VERSION ""

NS_ :

BS_:

BU_: Bosch_Radar2 Bosch_Radar1 RADAR_INPUT BoschRadar1
VAL_TABLE_ ValueTable_Power_SNA 255 "SNA" ;
VAL_TABLE_ ValueTable_YAngle_SNA 65535 "SNA" ;
VAL_TABLE_ ValueTable_YSigmaAngle_SNA 1023 "SNA" ;
VAL_TABLE_ ValueTable_AngleType 1 "First 2 angles valid in C msg" 0 "First 4 angles valid in C msg" ;
VAL_TABLE_ RI_Veh_PRNDSTAT 0 "Park" 1 "Reverse" 2 "Neutral" 3 "Drive" ;

BO_ 1958 Radar2_Diag_Response: 8 Bosch_Radar2
 SG_ R2_DiagResponse : 7|64@0+ (1,0) [0|0] "" Vector__XXX

BO_ 1957 Radar2_Diag_Request: 8 RADAR_INPUT
 SG_ R2_DiagRequest : 7|64@0+ (1,0) [0|0] ""  Bosch_Radar2

BO_ 1985 Radar1_Diag_Response: 8 Bosch_Radar1
 SG_ R1_DiagResponse : 7|64@0+ (1,0) [0|0] "" Vector__XXX

BO_ 1879 Radar1_Diag_Request: 8 RADAR_INPUT
 SG_ R1_DiagRequest : 7|64@0+ (1,0) [0|0] ""  Bosch_Radar1

BO_ 1285 Radar1_Obj00_A: 8 Bosch_Radar1
 SG_ Radar1_Obj00_wObstacle : 53|5@0+ (0.03125,0) [0|0.96875] "" Vector__XXX
 SG_ Radar1_Obj00_wNonObstacle : 63|5@0+ (0.03125,0) [0|0.96875] "" Vector__XXX
 SG_ Radar1_Obj00_wExist : 36|5@0+ (0.03125,0) [0|0.96875] "-" Vector__XXX
 SG_ Radar1_Obj00_ax : 47|10@0+ (0.03125,-16) [-16|15.96875] "m/s2" Vector__XXX
 SG_ Radar1_Obj00_vx : 11|12@0+ (0.0625,-128) [-128|127.9375] "m/s" Vector__XXX
 SG_ Radar1_Obj00_dy : 31|11@0+ (0.125,-128) [-128|127.875] "m" Vector__XXX
 SG_ Radar1_Obj00_dx : 7|12@0+ (0.0625,-128) [-128|127.9375] "m" Vector__XXX
 SG_ Radar1_Obj00_flagValid : 48|1@0+ (1,0) [0|1] "" Vector__XXX
 SG_ Radar1_Obj00_flagHist : 57|1@0+ (1,0) [0|1] "" Vector__XXX
 SG_ Radar1_Obj00_flagMeas : 58|1@0+ (1,0) [0|1] "" Vector__XXX
 SG_ Radar1_Obj00_MessAconsistBit : 56|1@0+ (1,0) [0|1] "" Vector__XXX

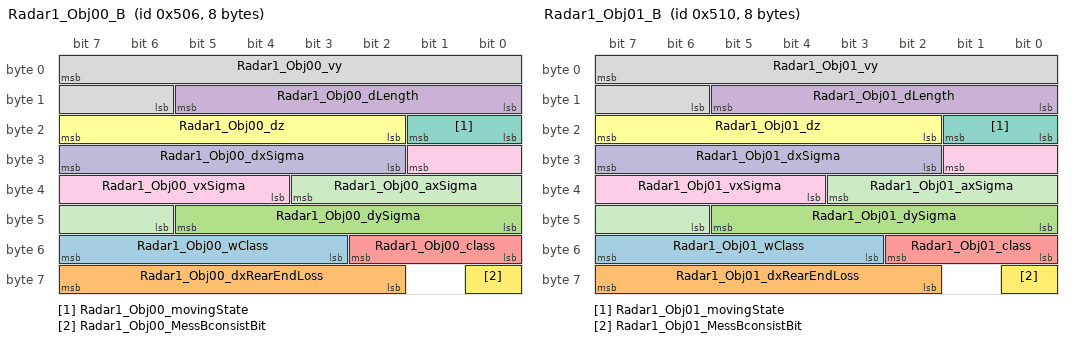
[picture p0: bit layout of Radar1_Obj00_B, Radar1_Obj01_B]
BO_ 1286 Radar1_Obj00_B: 8 Bosch_Radar1
 SG_ Radar1_Obj00_wClass : 55|5@0+ (0.03125,0) [0|0.96875] "" Vector__XXX
 SG_ Radar1_Obj00_dxRearEndLoss : 63|6@0+ (0.125,0) [0|7.875] "m" Vector__XXX
 SG_ Radar1_Obj00_dySigma : 45|6@0+ (0.0625,0) [0|3.9375] "m" Vector__XXX
 SG_ Radar1_Obj00_dLength : 13|6@0+ (0.125,0) [0|7.875] "m" Vector__XXX
 SG_ Radar1_Obj00_class : 50|3@0+ (1,0) [0|7] "" Vector__XXX
 SG_ Radar1_Obj00_dz : 23|6@0+ (0.25,-5) [-5|10.75] "m" Vector__XXX
 SG_ Radar1_Obj00_movingState : 17|2@0+ (1,0) [0|3] "" Vector__XXX
 SG_ Radar1_Obj00_vy : 7|10@0+ (0.125,-64) [-64|63.875] "m/s" Vector__XXX
 SG_ Radar1_Obj00_vxSigma : 25|6@0+ (0.0625,0) [0|3.9375] "m/s" Vector__XXX
 SG_ Radar1_Obj00_dxSigma : 31|6@0+ (0.0625,0) [0|3.9375] "m" Vector__XXX
 SG_ Radar1_Obj00_axSigma : 35|6@0+ (0.0625,0) [0|3.9375] "m/s2" Vector__XXX
 SG_ Radar1_Obj00_MessBconsistBit : 56|1@0+ (1,0) [0|1] "" Vector__XXX

BO_ 1295 Radar1_Obj01_A: 8 Bosch_Radar1
 SG_ Radar1_Obj01_wObstacle : 53|5@0+ (0.03125,0) [0|0.96875] "" Vector__XXX
 SG_ Radar1_Obj01_wNonObstacle : 63|5@0+ (0.03125,0) [0|0.96875] "" Vector__XXX
 SG_ Radar1_Obj01_wExist : 36|5@0+ (0.03125,0) [0|0.96875] "-" Vector__XXX
 SG_ Radar1_Obj01_ax : 47|10@0+ (0.03125,-16) [-16|15.96875] "m/s2" Vector__XXX
 SG_ Radar1_Obj01_vx : 11|12@0+ (0.0625,-128) [-128|127.9375] "m/s" Vector__XXX
 SG_ Radar1_Obj01_dy : 31|11@0+ (0.125,-128) [-128|127.875] "m" Vector__XXX
 SG_ Radar1_Obj01_dx : 7|12@0+ (0.0625,-128) [-128|127.9375] "m" Vector__XXX
 SG_ Radar1_Obj01_flagValid : 48|1@0+ (1,0) [0|1] "" Vector__XXX
 SG_ Radar1_Obj01_flagHist : 57|1@0+ (1,0) [0|1] "" Vector__XXX
 SG_ Radar1_Obj01_flagMeas : 58|1@0+ (1,0) [0|1] "" Vector__XXX
 SG_ Radar1_Obj01_MessAconsistBit : 56|1@0+ (1,0) [0|1] "" Vector__XXX

BO_ 1296 Radar1_Obj01_B: 8 Bosch_Radar1
 SG_ Radar1_Obj01_wClass : 55|5@0+ (0.03125,0) [0|0.96875] "" Vector__XXX
 SG_ Radar1_Obj01_dxRearEndLoss : 63|6@0+ (0.125,0) [0|7.875] "m" Vector__XXX
 SG_ Radar1_Obj01_dySigma : 45|6@0+ (0.0625,0) [0|3.9375] "m" Vector__XXX
 SG_ Radar1_Obj01_dLength : 13|6@0+ (0.125,0) [0|7.875] "m" Vector__XXX
 SG_ Radar1_Obj01_class : 50|3@0+ (1,0) [0|7] "" Vector__XXX
 SG_ Radar1_Obj01_dz : 23|6@0+ (0.25,-5) [-5|10.75] "m" Vector__XXX
 SG_ Radar1_Obj01_movingState : 17|2@0+ (1,0) [0|3] "" Vector__XXX
 SG_ Radar1_Obj01_vy : 7|10@0+ (0.125,-64) [-64|63.875] "m/s" Vector__XXX
 SG_ Radar1_Obj01_vxSigma : 25|6@0+ (0.0625,0) [0|3.9375] "m/s" Vector__XXX
 SG_ Radar1_Obj01_dxSigma : 31|6@0+ (0.0625,0) [0|3.9375] "m" Vector__XXX
 SG_ Radar1_Obj01_axSigma : 35|6@0+ (0.0625,0) [0|3.9375] "m/s2" Vector__XXX
 SG_ Radar1_Obj01_MessBconsistBit : 56|1@0+ (1,0) [0|1] "" Vector__XXX

BO_ 1305 Radar1_Obj02_A: 8 Bosch_Radar1
 SG_ Radar1_Obj02_wObstacle : 53|5@0+ (0.03125,0) [0|0.96875] "" Vector__XXX
 SG_ Radar1_Obj02_wNonObstacle : 63|5@0+ (0.03125,0) [0|0.96875] "" Vector__XXX
 SG_ Radar1_Obj02_wExist : 36|5@0+ (0.03125,0) [0|0.96875] "-" Vector__XXX
 SG_ Radar1_Obj02_ax : 47|10@0+ (0.03125,-16) [-16|15.96875] "m/s2" Vector__XXX
 SG_ Radar1_Obj02_vx : 11|12@0+ (0.0625,-128) [-128|127.9375] "m/s" Vector__XXX
 SG_ Radar1_Obj02_dy : 31|11@0+ (0.125,-128) [-128|127.875] "m" Vector__XXX
 SG_ Radar1_Obj02_dx : 7|12@0+ (0.0625,-128) [-128|127.9375] "m" Vector__XXX
 SG_ Radar1_Obj02_flagValid : 48|1@0+ (1,0) [0|1] "" Vector__XXX
 SG_ Radar1_Obj02_flagHist : 57|1@0+ (1,0) [0|1] "" Vector__XXX
 SG_ Radar1_Obj02_flagMeas : 58|1@0+ (1,0) [0|1] "" Vector__XXX
 SG_ Radar1_Obj02_MessAconsistBit : 56|1@0+ (1,0) [0|1] "" Vector__XXX

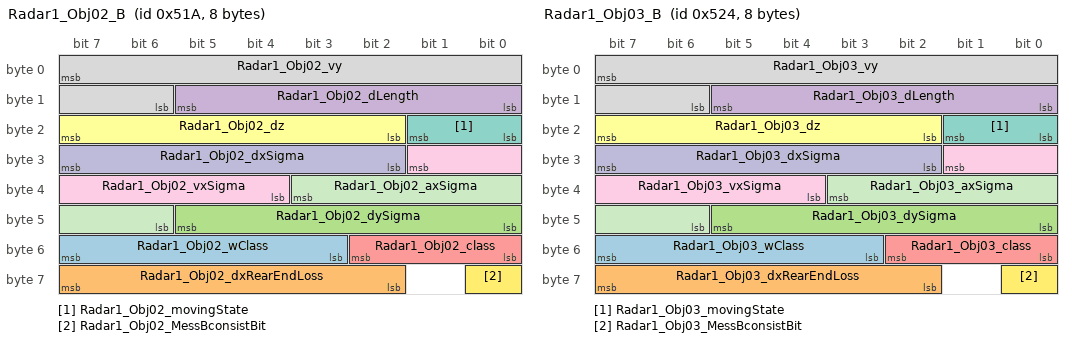
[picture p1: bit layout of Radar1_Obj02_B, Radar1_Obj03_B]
BO_ 1306 Radar1_Obj02_B: 8 Bosch_Radar1
 SG_ Radar1_Obj02_wClass : 55|5@0+ (0.03125,0) [0|0.96875] "" Vector__XXX
 SG_ Radar1_Obj02_dxRearEndLoss : 63|6@0+ (0.125,0) [0|7.875] "m" Vector__XXX
 SG_ Radar1_Obj02_dySigma : 45|6@0+ (0.0625,0) [0|3.9375] "m" Vector__XXX
 SG_ Radar1_Obj02_dLength : 13|6@0+ (0.125,0) [0|7.875] "m" Vector__XXX
 SG_ Radar1_Obj02_class : 50|3@0+ (1,0) [0|7] "" Vector__XXX
 SG_ Radar1_Obj02_dz : 23|6@0+ (0.25,-5) [-5|10.75] "m" Vector__XXX
 SG_ Radar1_Obj02_movingState : 17|2@0+ (1,0) [0|3] "" Vector__XXX
 SG_ Radar1_Obj02_vy : 7|10@0+ (0.125,-64) [-64|63.875] "m/s" Vector__XXX
 SG_ Radar1_Obj02_vxSigma : 25|6@0+ (0.0625,0) [0|3.9375] "m/s" Vector__XXX
 SG_ Radar1_Obj02_dxSigma : 31|6@0+ (0.0625,0) [0|3.9375] "m" Vector__XXX
 SG_ Radar1_Obj02_axSigma : 35|6@0+ (0.0625,0) [0|3.9375] "m/s2" Vector__XXX
 SG_ Radar1_Obj02_MessBconsistBit : 56|1@0+ (1,0) [0|1] "" Vector__XXX

BO_ 1315 Radar1_Obj03_A: 8 Bosch_Radar1
 SG_ Radar1_Obj03_wObstacle : 53|5@0+ (0.03125,0) [0|0.96875] "" Vector__XXX
 SG_ Radar1_Obj03_wNonObstacle : 63|5@0+ (0.03125,0) [0|0.96875] "" Vector__XXX
 SG_ Radar1_Obj03_wExist : 36|5@0+ (0.03125,0) [0|0.96875] "-" Vector__XXX
 SG_ Radar1_Obj03_ax : 47|10@0+ (0.03125,-16) [-16|15.96875] "m/s2" Vector__XXX
 SG_ Radar1_Obj03_vx : 11|12@0+ (0.0625,-128) [-128|127.9375] "m/s" Vector__XXX
 SG_ Radar1_Obj03_dy : 31|11@0+ (0.125,-128) [-128|127.875] "m" Vector__XXX
 SG_ Radar1_Obj03_dx : 7|12@0+ (0.0625,-128) [-128|127.9375] "m" Vector__XXX
 SG_ Radar1_Obj03_flagValid : 48|1@0+ (1,0) [0|1] "" Vector__XXX
 SG_ Radar1_Obj03_flagHist : 57|1@0+ (1,0) [0|1] "" Vector__XXX
 SG_ Radar1_Obj03_flagMeas : 58|1@0+ (1,0) [0|1] "" Vector__XXX
 SG_ Radar1_Obj03_MessAconsistBit : 56|1@0+ (1,0) [0|1] "" Vector__XXX

BO_ 1316 Radar1_Obj03_B: 8 Bosch_Radar1
 SG_ Radar1_Obj03_wClass : 55|5@0+ (0.03125,0) [0|0.96875] "" Vector__XXX
 SG_ Radar1_Obj03_dxRearEndLoss : 63|6@0+ (0.125,0) [0|7.875] "m" Vector__XXX
 SG_ Radar1_Obj03_dySigma : 45|6@0+ (0.0625,0) [0|3.9375] "m" Vector__XXX
 SG_ Radar1_Obj03_dLength : 13|6@0+ (0.125,0) [0|7.875] "m" Vector__XXX
 SG_ Radar1_Obj03_class : 50|3@0+ (1,0) [0|7] "" Vector__XXX
 SG_ Radar1_Obj03_dz : 23|6@0+ (0.25,-5) [-5|10.75] "m" Vector__XXX
 SG_ Radar1_Obj03_movingState : 17|2@0+ (1,0) [0|3] "" Vector__XXX
 SG_ Radar1_Obj03_vy : 7|10@0+ (0.125,-64) [-64|63.875] "m/s" Vector__XXX
 SG_ Radar1_Obj03_vxSigma : 25|6@0+ (0.0625,0) [0|3.9375] "m/s" Vector__XXX
 SG_ Radar1_Obj03_dxSigma : 31|6@0+ (0.0625,0) [0|3.9375] "m" Vector__XXX
 SG_ Radar1_Obj03_axSigma : 35|6@0+ (0.0625,0) [0|3.9375] "m/s2" Vector__XXX
 SG_ Radar1_Obj03_MessBconsistBit : 56|1@0+ (1,0) [0|1] "" Vector__XXX

BO_ 1325 Radar1_Obj04_A: 8 Bosch_Radar1
 SG_ Radar1_Obj04_wObstacle : 53|5@0+ (0.03125,0) [0|0.96875] "" Vector__XXX
 SG_ Radar1_Obj04_wNonObstacle : 63|5@0+ (0.03125,0) [0|0.96875] "" Vector__XXX
 SG_ Radar1_Obj04_wExist : 36|5@0+ (0.03125,0) [0|0.96875] "-" Vector__XXX
 SG_ Radar1_Obj04_ax : 47|10@0+ (0.03125,-16) [-16|15.96875] "m/s2" Vector__XXX
 SG_ Radar1_Obj04_vx : 11|12@0+ (0.0625,-128) [-128|127.9375] "m/s" Vector__XXX
 SG_ Radar1_Obj04_dy : 31|11@0+ (0.125,-128) [-128|127.875] "m" Vector__XXX
 SG_ Radar1_Obj04_dx : 7|12@0+ (0.0625,-128) [-128|127.9375] "m" Vector__XXX
 SG_ Radar1_Obj04_flagValid : 48|1@0+ (1,0) [0|1] "" Vector__XXX
 SG_ Radar1_Obj04_flagHist : 57|1@0+ (1,0) [0|1] "" Vector__XXX
 SG_ Radar1_Obj04_flagMeas : 58|1@0+ (1,0) [0|1] "" Vector__XXX
 SG_ Radar1_Obj04_MessAconsistBit : 56|1@0+ (1,0) [0|1] "" Vector__XXX

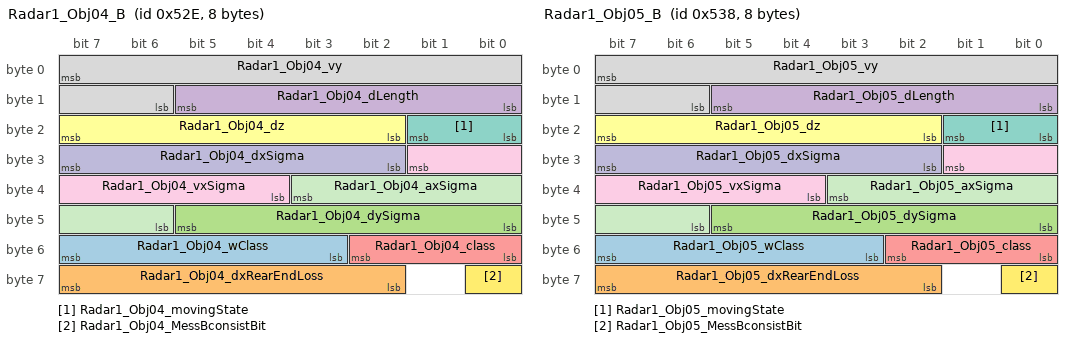
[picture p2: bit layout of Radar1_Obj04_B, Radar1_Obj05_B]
BO_ 1326 Radar1_Obj04_B: 8 Bosch_Radar1
 SG_ Radar1_Obj04_wClass : 55|5@0+ (0.03125,0) [0|0.96875] "" Vector__XXX
 SG_ Radar1_Obj04_dxRearEndLoss : 63|6@0+ (0.125,0) [0|7.875] "m" Vector__XXX
 SG_ Radar1_Obj04_dySigma : 45|6@0+ (0.0625,0) [0|3.9375] "m" Vector__XXX
 SG_ Radar1_Obj04_dLength : 13|6@0+ (0.125,0) [0|7.875] "m" Vector__XXX
 SG_ Radar1_Obj04_class : 50|3@0+ (1,0) [0|7] "" Vector__XXX
 SG_ Radar1_Obj04_dz : 23|6@0+ (0.25,-5) [-5|10.75] "m" Vector__XXX
 SG_ Radar1_Obj04_movingState : 17|2@0+ (1,0) [0|3] "" Vector__XXX
 SG_ Radar1_Obj04_vy : 7|10@0+ (0.125,-64) [-64|63.875] "m/s" Vector__XXX
 SG_ Radar1_Obj04_vxSigma : 25|6@0+ (0.0625,0) [0|3.9375] "m/s" Vector__XXX
 SG_ Radar1_Obj04_dxSigma : 31|6@0+ (0.0625,0) [0|3.9375] "m" Vector__XXX
 SG_ Radar1_Obj04_axSigma : 35|6@0+ (0.0625,0) [0|3.9375] "m/s2" Vector__XXX
 SG_ Radar1_Obj04_MessBconsistBit : 56|1@0+ (1,0) [0|1] "" Vector__XXX

BO_ 1335 Radar1_Obj05_A: 8 Bosch_Radar1
 SG_ Radar1_Obj05_wObstacle : 53|5@0+ (0.03125,0) [0|0.96875] "" Vector__XXX
 SG_ Radar1_Obj05_wNonObstacle : 63|5@0+ (0.03125,0) [0|0.96875] "" Vector__XXX
 SG_ Radar1_Obj05_wExist : 36|5@0+ (0.03125,0) [0|0.96875] "-" Vector__XXX
 SG_ Radar1_Obj05_ax : 47|10@0+ (0.03125,-16) [-16|15.96875] "m/s2" Vector__XXX
 SG_ Radar1_Obj05_vx : 11|12@0+ (0.0625,-128) [-128|127.9375] "m/s" Vector__XXX
 SG_ Radar1_Obj05_dy : 31|11@0+ (0.125,-128) [-128|127.875] "m" Vector__XXX
 SG_ Radar1_Obj05_dx : 7|12@0+ (0.0625,-128) [-128|127.9375] "m" Vector__XXX
 SG_ Radar1_Obj05_flagValid : 48|1@0+ (1,0) [0|1] "" Vector__XXX
 SG_ Radar1_Obj05_flagHist : 57|1@0+ (1,0) [0|1] "" Vector__XXX
 SG_ Radar1_Obj05_flagMeas : 58|1@0+ (1,0) [0|1] "" Vector__XXX
 SG_ Radar1_Obj05_MessAconsistBit : 56|1@0+ (1,0) [0|1] "" Vector__XXX

BO_ 1336 Radar1_Obj05_B: 8 Bosch_Radar1
 SG_ Radar1_Obj05_wClass : 55|5@0+ (0.03125,0) [0|0.96875] "" Vector__XXX
 SG_ Radar1_Obj05_dxRearEndLoss : 63|6@0+ (0.125,0) [0|7.875] "m" Vector__XXX
 SG_ Radar1_Obj05_dySigma : 45|6@0+ (0.0625,0) [0|3.9375] "m" Vector__XXX
 SG_ Radar1_Obj05_dLength : 13|6@0+ (0.125,0) [0|7.875] "m" Vector__XXX
 SG_ Radar1_Obj05_class : 50|3@0+ (1,0) [0|7] "" Vector__XXX
 SG_ Radar1_Obj05_dz : 23|6@0+ (0.25,-5) [-5|10.75] "m" Vector__XXX
 SG_ Radar1_Obj05_movingState : 17|2@0+ (1,0) [0|3] "" Vector__XXX
 SG_ Radar1_Obj05_vy : 7|10@0+ (0.125,-64) [-64|63.875] "m/s" Vector__XXX
 SG_ Radar1_Obj05_vxSigma : 25|6@0+ (0.0625,0) [0|3.9375] "m/s" Vector__XXX
 SG_ Radar1_Obj05_dxSigma : 31|6@0+ (0.0625,0) [0|3.9375] "m" Vector__XXX
 SG_ Radar1_Obj05_axSigma : 35|6@0+ (0.0625,0) [0|3.9375] "m/s2" Vector__XXX
 SG_ Radar1_Obj05_MessBconsistBit : 56|1@0+ (1,0) [0|1] "" Vector__XXX

BO_ 1345 Radar1_Obj06_A: 8 Bosch_Radar1
 SG_ Radar1_Obj06_wObstacle : 53|5@0+ (0.03125,0) [0|0.96875] "" Vector__XXX
 SG_ Radar1_Obj06_wNonObstacle : 63|5@0+ (0.03125,0) [0|0.96875] "" Vector__XXX
 SG_ Radar1_Obj06_wExist : 36|5@0+ (0.03125,0) [0|0.96875] "-" Vector__XXX
 SG_ Radar1_Obj06_ax : 47|10@0+ (0.03125,-16) [-16|15.96875] "m/s2" Vector__XXX
 SG_ Radar1_Obj06_vx : 11|12@0+ (0.0625,-128) [-128|127.9375] "m/s" Vector__XXX
 SG_ Radar1_Obj06_dy : 31|11@0+ (0.125,-128) [-128|127.875] "m" Vector__XXX
 SG_ Radar1_Obj06_dx : 7|12@0+ (0.0625,-128) [-128|127.9375] "m" Vector__XXX
 SG_ Radar1_Obj06_flagValid : 48|1@0+ (1,0) [0|1] "" Vector__XXX
 SG_ Radar1_Obj06_flagHist : 57|1@0+ (1,0) [0|1] "" Vector__XXX
 SG_ Radar1_Obj06_flagMeas : 58|1@0+ (1,0) [0|1] "" Vector__XXX
 SG_ Radar1_Obj06_MessAconsistBit : 56|1@0+ (1,0) [0|1] "" Vector__XXX

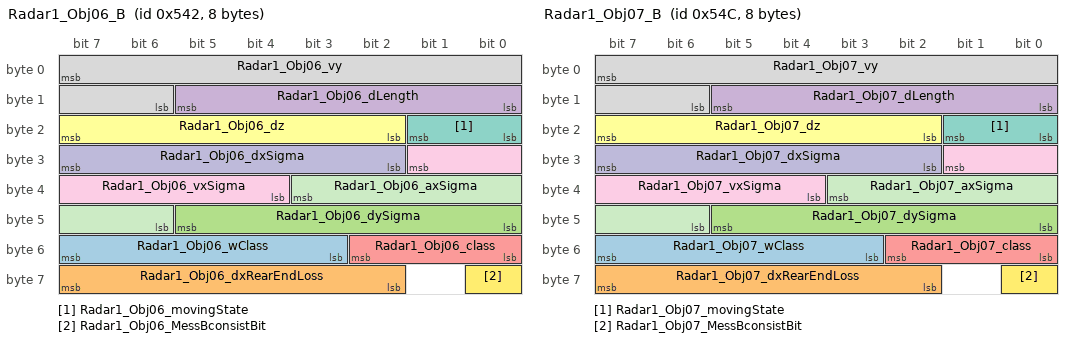
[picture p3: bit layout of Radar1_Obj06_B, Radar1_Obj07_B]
BO_ 1346 Radar1_Obj06_B: 8 Bosch_Radar1
 SG_ Radar1_Obj06_wClass : 55|5@0+ (0.03125,0) [0|0.96875] "" Vector__XXX
 SG_ Radar1_Obj06_dxRearEndLoss : 63|6@0+ (0.125,0) [0|7.875] "m" Vector__XXX
 SG_ Radar1_Obj06_dySigma : 45|6@0+ (0.0625,0) [0|3.9375] "m" Vector__XXX
 SG_ Radar1_Obj06_dLength : 13|6@0+ (0.125,0) [0|7.875] "m" Vector__XXX
 SG_ Radar1_Obj06_class : 50|3@0+ (1,0) [0|7] "" Vector__XXX
 SG_ Radar1_Obj06_dz : 23|6@0+ (0.25,-5) [-5|10.75] "m" Vector__XXX
 SG_ Radar1_Obj06_movingState : 17|2@0+ (1,0) [0|3] "" Vector__XXX
 SG_ Radar1_Obj06_vy : 7|10@0+ (0.125,-64) [-64|63.875] "m/s" Vector__XXX
 SG_ Radar1_Obj06_vxSigma : 25|6@0+ (0.0625,0) [0|3.9375] "m/s" Vector__XXX
 SG_ Radar1_Obj06_dxSigma : 31|6@0+ (0.0625,0) [0|3.9375] "m" Vector__XXX
 SG_ Radar1_Obj06_axSigma : 35|6@0+ (0.0625,0) [0|3.9375] "m/s2" Vector__XXX
 SG_ Radar1_Obj06_MessBconsistBit : 56|1@0+ (1,0) [0|1] "" Vector__XXX

BO_ 1355 Radar1_Obj07_A: 8 Bosch_Radar1
 SG_ Radar1_Obj07_wObstacle : 53|5@0+ (0.03125,0) [0|0.96875] "" Vector__XXX
 SG_ Radar1_Obj07_wNonObstacle : 63|5@0+ (0.03125,0) [0|0.96875] "" Vector__XXX
 SG_ Radar1_Obj07_wExist : 36|5@0+ (0.03125,0) [0|0.96875] "-" Vector__XXX
 SG_ Radar1_Obj07_ax : 47|10@0+ (0.03125,-16) [-16|15.96875] "m/s2" Vector__XXX
 SG_ Radar1_Obj07_vx : 11|12@0+ (0.0625,-128) [-128|127.9375] "m/s" Vector__XXX
 SG_ Radar1_Obj07_dy : 31|11@0+ (0.125,-128) [-128|127.875] "m" Vector__XXX
 SG_ Radar1_Obj07_dx : 7|12@0+ (0.0625,-128) [-128|127.9375] "m" Vector__XXX
 SG_ Radar1_Obj07_flagValid : 48|1@0+ (1,0) [0|1] "" Vector__XXX
 SG_ Radar1_Obj07_flagHist : 57|1@0+ (1,0) [0|1] "" Vector__XXX
 SG_ Radar1_Obj07_flagMeas : 58|1@0+ (1,0) [0|1] "" Vector__XXX
 SG_ Radar1_Obj07_MessAconsistBit : 56|1@0+ (1,0) [0|1] "" Vector__XXX

BO_ 1356 Radar1_Obj07_B: 8 Bosch_Radar1
 SG_ Radar1_Obj07_wClass : 55|5@0+ (0.03125,0) [0|0.96875] "" Vector__XXX
 SG_ Radar1_Obj07_dxRearEndLoss : 63|6@0+ (0.125,0) [0|7.875] "m" Vector__XXX
 SG_ Radar1_Obj07_dySigma : 45|6@0+ (0.0625,0) [0|3.9375] "m" Vector__XXX
 SG_ Radar1_Obj07_dLength : 13|6@0+ (0.125,0) [0|7.875] "m" Vector__XXX
 SG_ Radar1_Obj07_class : 50|3@0+ (1,0) [0|7] "" Vector__XXX
 SG_ Radar1_Obj07_dz : 23|6@0+ (0.25,-5) [-5|10.75] "m" Vector__XXX
 SG_ Radar1_Obj07_movingState : 17|2@0+ (1,0) [0|3] "" Vector__XXX
 SG_ Radar1_Obj07_vy : 7|10@0+ (0.125,-64) [-64|63.875] "m/s" Vector__XXX
 SG_ Radar1_Obj07_vxSigma : 25|6@0+ (0.0625,0) [0|3.9375] "m/s" Vector__XXX
 SG_ Radar1_Obj07_dxSigma : 31|6@0+ (0.0625,0) [0|3.9375] "m" Vector__XXX
 SG_ Radar1_Obj07_axSigma : 35|6@0+ (0.0625,0) [0|3.9375] "m/s2" Vector__XXX
 SG_ Radar1_Obj07_MessBconsistBit : 56|1@0+ (1,0) [0|1] "" Vector__XXX

BO_ 1365 Radar1_Obj08_A: 8 Bosch_Radar1
 SG_ Radar1_Obj08_wObstacle : 53|5@0+ (0.03125,0) [0|0.96875] "" Vector__XXX
 SG_ Radar1_Obj08_wNonObstacle : 63|5@0+ (0.03125,0) [0|0.96875] "" Vector__XXX
 SG_ Radar1_Obj08_wExist : 36|5@0+ (0.03125,0) [0|0.96875] "-" Vector__XXX
 SG_ Radar1_Obj08_ax : 47|10@0+ (0.03125,-16) [-16|15.96875] "m/s2" Vector__XXX
 SG_ Radar1_Obj08_vx : 11|12@0+ (0.0625,-128) [-128|127.9375] "m/s" Vector__XXX
 SG_ Radar1_Obj08_dy : 31|11@0+ (0.125,-128) [-128|127.875] "m" Vector__XXX
 SG_ Radar1_Obj08_dx : 7|12@0+ (0.0625,-128) [-128|127.9375] "m" Vector__XXX
 SG_ Radar1_Obj08_flagValid : 48|1@0+ (1,0) [0|1] "" Vector__XXX
 SG_ Radar1_Obj08_flagHist : 57|1@0+ (1,0) [0|1] "" Vector__XXX
 SG_ Radar1_Obj08_flagMeas : 58|1@0+ (1,0) [0|1] "" Vector__XXX
 SG_ Radar1_Obj08_MessAconsistBit : 56|1@0+ (1,0) [0|1] "" Vector__XXX

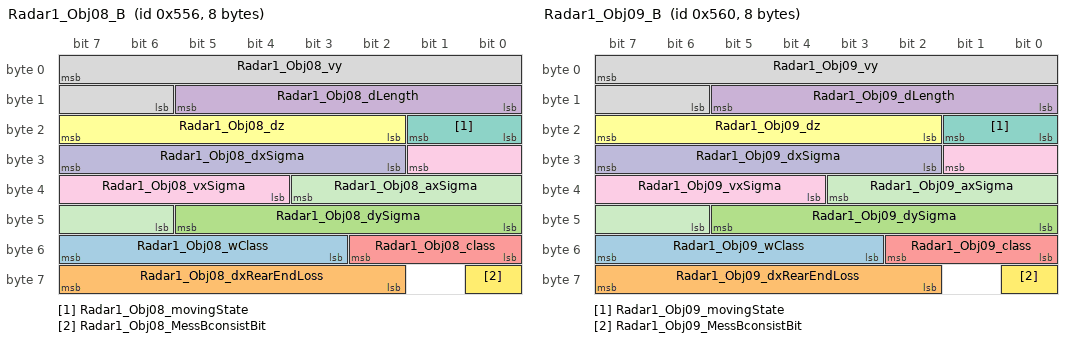
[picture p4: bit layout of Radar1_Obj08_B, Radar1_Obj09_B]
BO_ 1366 Radar1_Obj08_B: 8 Bosch_Radar1
 SG_ Radar1_Obj08_wClass : 55|5@0+ (0.03125,0) [0|0.96875] "" Vector__XXX
 SG_ Radar1_Obj08_dxRearEndLoss : 63|6@0+ (0.125,0) [0|7.875] "m" Vector__XXX
 SG_ Radar1_Obj08_dySigma : 45|6@0+ (0.0625,0) [0|3.9375] "m" Vector__XXX
 SG_ Radar1_Obj08_dLength : 13|6@0+ (0.125,0) [0|7.875] "m" Vector__XXX
 SG_ Radar1_Obj08_class : 50|3@0+ (1,0) [0|7] "" Vector__XXX
 SG_ Radar1_Obj08_dz : 23|6@0+ (0.25,-5) [-5|10.75] "m" Vector__XXX
 SG_ Radar1_Obj08_movingState : 17|2@0+ (1,0) [0|3] "" Vector__XXX
 SG_ Radar1_Obj08_vy : 7|10@0+ (0.125,-64) [-64|63.875] "m/s" Vector__XXX
 SG_ Radar1_Obj08_vxSigma : 25|6@0+ (0.0625,0) [0|3.9375] "m/s" Vector__XXX
 SG_ Radar1_Obj08_dxSigma : 31|6@0+ (0.0625,0) [0|3.9375] "m" Vector__XXX
 SG_ Radar1_Obj08_axSigma : 35|6@0+ (0.0625,0) [0|3.9375] "m/s2" Vector__XXX
 SG_ Radar1_Obj08_MessBconsistBit : 56|1@0+ (1,0) [0|1] "" Vector__XXX

BO_ 1375 Radar1_Obj09_A: 8 Bosch_Radar1
 SG_ Radar1_Obj09_wObstacle : 53|5@0+ (0.03125,0) [0|0.96875] "" Vector__XXX
 SG_ Radar1_Obj09_wNonObstacle : 63|5@0+ (0.03125,0) [0|0.96875] "" Vector__XXX
 SG_ Radar1_Obj09_wExist : 36|5@0+ (0.03125,0) [0|0.96875] "-" Vector__XXX
 SG_ Radar1_Obj09_ax : 47|10@0+ (0.03125,-16) [-16|15.96875] "m/s2" Vector__XXX
 SG_ Radar1_Obj09_vx : 11|12@0+ (0.0625,-128) [-128|127.9375] "m/s" Vector__XXX
 SG_ Radar1_Obj09_dy : 31|11@0+ (0.125,-128) [-128|127.875] "m" Vector__XXX
 SG_ Radar1_Obj09_dx : 7|12@0+ (0.0625,-128) [-128|127.9375] "m" Vector__XXX
 SG_ Radar1_Obj09_flagValid : 48|1@0+ (1,0) [0|1] "" Vector__XXX
 SG_ Radar1_Obj09_flagHist : 57|1@0+ (1,0) [0|1] "" Vector__XXX
 SG_ Radar1_Obj09_flagMeas : 58|1@0+ (1,0) [0|1] "" Vector__XXX
 SG_ Radar1_Obj09_MessAconsistBit : 56|1@0+ (1,0) [0|1] "" Vector__XXX

BO_ 1376 Radar1_Obj09_B: 8 Bosch_Radar1
 SG_ Radar1_Obj09_wClass : 55|5@0+ (0.03125,0) [0|0.96875] "" Vector__XXX
 SG_ Radar1_Obj09_dxRearEndLoss : 63|6@0+ (0.125,0) [0|7.875] "m" Vector__XXX
 SG_ Radar1_Obj09_dySigma : 45|6@0+ (0.0625,0) [0|3.9375] "m" Vector__XXX
 SG_ Radar1_Obj09_dLength : 13|6@0+ (0.125,0) [0|7.875] "m" Vector__XXX
 SG_ Radar1_Obj09_class : 50|3@0+ (1,0) [0|7] "" Vector__XXX
 SG_ Radar1_Obj09_dz : 23|6@0+ (0.25,-5) [-5|10.75] "m" Vector__XXX
 SG_ Radar1_Obj09_movingState : 17|2@0+ (1,0) [0|3] "" Vector__XXX
 SG_ Radar1_Obj09_vy : 7|10@0+ (0.125,-64) [-64|63.875] "m/s" Vector__XXX
 SG_ Radar1_Obj09_vxSigma : 25|6@0+ (0.0625,0) [0|3.9375] "m/s" Vector__XXX
 SG_ Radar1_Obj09_dxSigma : 31|6@0+ (0.0625,0) [0|3.9375] "m" Vector__XXX
 SG_ Radar1_Obj09_axSigma : 35|6@0+ (0.0625,0) [0|3.9375] "m/s2" Vector__XXX
 SG_ Radar1_Obj09_MessBconsistBit : 56|1@0+ (1,0) [0|1] "" Vector__XXX

BO_ 1385 Radar1_Obj10_A: 8 Bosch_Radar1
 SG_ Radar1_Obj10_wObstacle : 53|5@0+ (0.03125,0) [0|0.96875] "" Vector__XXX
 SG_ Radar1_Obj10_wNonObstacle : 63|5@0+ (0.03125,0) [0|0.96875] "" Vector__XXX
 SG_ Radar1_Obj10_wExist : 36|5@0+ (0.03125,0) [0|0.96875] "-" Vector__XXX
 SG_ Radar1_Obj10_ax : 47|10@0+ (0.03125,-16) [-16|15.96875] "m/s2" Vector__XXX
 SG_ Radar1_Obj10_vx : 11|12@0+ (0.0625,-128) [-128|127.9375] "m/s" Vector__XXX
 SG_ Radar1_Obj10_dy : 31|11@0+ (0.125,-128) [-128|127.875] "m" Vector__XXX
 SG_ Radar1_Obj10_dx : 7|12@0+ (0.0625,-128) [-128|127.9375] "m" Vector__XXX
 SG_ Radar1_Obj10_flagValid : 48|1@0+ (1,0) [0|1] "" Vector__XXX
 SG_ Radar1_Obj10_flagHist : 57|1@0+ (1,0) [0|1] "" Vector__XXX
 SG_ Radar1_Obj10_flagMeas : 58|1@0+ (1,0) [0|1] "" Vector__XXX
 SG_ Radar1_Obj10_MessAconsistBit : 56|1@0+ (1,0) [0|1] "" Vector__XXX

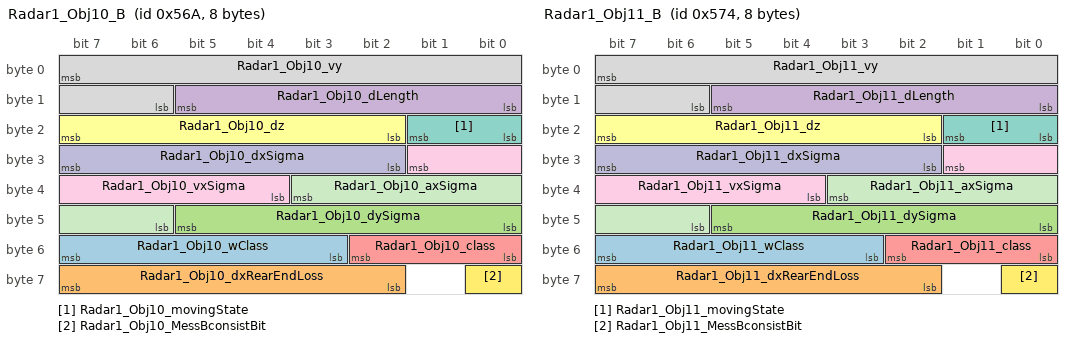
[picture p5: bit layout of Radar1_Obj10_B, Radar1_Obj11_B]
BO_ 1386 Radar1_Obj10_B: 8 Bosch_Radar1
 SG_ Radar1_Obj10_wClass : 55|5@0+ (0.03125,0) [0|0.96875] "" Vector__XXX
 SG_ Radar1_Obj10_dxRearEndLoss : 63|6@0+ (0.125,0) [0|7.875] "m" Vector__XXX
 SG_ Radar1_Obj10_dySigma : 45|6@0+ (0.0625,0) [0|3.9375] "m" Vector__XXX
 SG_ Radar1_Obj10_dLength : 13|6@0+ (0.125,0) [0|7.875] "m" Vector__XXX
 SG_ Radar1_Obj10_class : 50|3@0+ (1,0) [0|7] "" Vector__XXX
 SG_ Radar1_Obj10_dz : 23|6@0+ (0.25,-5) [-5|10.75] "m" Vector__XXX
 SG_ Radar1_Obj10_movingState : 17|2@0+ (1,0) [0|3] "" Vector__XXX
 SG_ Radar1_Obj10_vy : 7|10@0+ (0.125,-64) [-64|63.875] "m/s" Vector__XXX
 SG_ Radar1_Obj10_vxSigma : 25|6@0+ (0.0625,0) [0|3.9375] "m/s" Vector__XXX
 SG_ Radar1_Obj10_dxSigma : 31|6@0+ (0.0625,0) [0|3.9375] "m" Vector__XXX
 SG_ Radar1_Obj10_axSigma : 35|6@0+ (0.0625,0) [0|3.9375] "m/s2" Vector__XXX
 SG_ Radar1_Obj10_MessBconsistBit : 56|1@0+ (1,0) [0|1] "" Vector__XXX

BO_ 1395 Radar1_Obj11_A: 8 Bosch_Radar1
 SG_ Radar1_Obj11_wObstacle : 53|5@0+ (0.03125,0) [0|0.96875] "" Vector__XXX
 SG_ Radar1_Obj11_wNonObstacle : 63|5@0+ (0.03125,0) [0|0.96875] "" Vector__XXX
 SG_ Radar1_Obj11_wExist : 36|5@0+ (0.03125,0) [0|0.96875] "-" Vector__XXX
 SG_ Radar1_Obj11_ax : 47|10@0+ (0.03125,-16) [-16|15.96875] "m/s2" Vector__XXX
 SG_ Radar1_Obj11_vx : 11|12@0+ (0.0625,-128) [-128|127.9375] "m/s" Vector__XXX
 SG_ Radar1_Obj11_dy : 31|11@0+ (0.125,-128) [-128|127.875] "m" Vector__XXX
 SG_ Radar1_Obj11_dx : 7|12@0+ (0.0625,-128) [-128|127.9375] "m" Vector__XXX
 SG_ Radar1_Obj11_flagValid : 48|1@0+ (1,0) [0|1] "" Vector__XXX
 SG_ Radar1_Obj11_flagHist : 57|1@0+ (1,0) [0|1] "" Vector__XXX
 SG_ Radar1_Obj11_flagMeas : 58|1@0+ (1,0) [0|1] "" Vector__XXX
 SG_ Radar1_Obj11_MessAconsistBit : 56|1@0+ (1,0) [0|1] "" Vector__XXX

BO_ 1396 Radar1_Obj11_B: 8 Bosch_Radar1
 SG_ Radar1_Obj11_wClass : 55|5@0+ (0.03125,0) [0|0.96875] "" Vector__XXX
 SG_ Radar1_Obj11_dxRearEndLoss : 63|6@0+ (0.125,0) [0|7.875] "m" Vector__XXX
 SG_ Radar1_Obj11_dySigma : 45|6@0+ (0.0625,0) [0|3.9375] "m" Vector__XXX
 SG_ Radar1_Obj11_dLength : 13|6@0+ (0.125,0) [0|7.875] "m" Vector__XXX
 SG_ Radar1_Obj11_class : 50|3@0+ (1,0) [0|7] "" Vector__XXX
 SG_ Radar1_Obj11_dz : 23|6@0+ (0.25,-5) [-5|10.75] "m" Vector__XXX
 SG_ Radar1_Obj11_movingState : 17|2@0+ (1,0) [0|3] "" Vector__XXX
 SG_ Radar1_Obj11_vy : 7|10@0+ (0.125,-64) [-64|63.875] "m/s" Vector__XXX
 SG_ Radar1_Obj11_vxSigma : 25|6@0+ (0.0625,0) [0|3.9375] "m/s" Vector__XXX
 SG_ Radar1_Obj11_dxSigma : 31|6@0+ (0.0625,0) [0|3.9375] "m" Vector__XXX
 SG_ Radar1_Obj11_axSigma : 35|6@0+ (0.0625,0) [0|3.9375] "m/s2" Vector__XXX
 SG_ Radar1_Obj11_MessBconsistBit : 56|1@0+ (1,0) [0|1] "" Vector__XXX

BO_ 1405 Radar1_Obj12_A: 8 Bosch_Radar1
 SG_ Radar1_Obj12_wObstacle : 53|5@0+ (0.03125,0) [0|0.96875] "" Vector__XXX
 SG_ Radar1_Obj12_wNonObstacle : 63|5@0+ (0.03125,0) [0|0.96875] "" Vector__XXX
 SG_ Radar1_Obj12_wExist : 36|5@0+ (0.03125,0) [0|0.96875] "-" Vector__XXX
 SG_ Radar1_Obj12_ax : 47|10@0+ (0.03125,-16) [-16|15.96875] "m/s2" Vector__XXX
 SG_ Radar1_Obj12_vx : 11|12@0+ (0.0625,-128) [-128|127.9375] "m/s" Vector__XXX
 SG_ Radar1_Obj12_dy : 31|11@0+ (0.125,-128) [-128|127.875] "m" Vector__XXX
 SG_ Radar1_Obj12_dx : 7|12@0+ (0.0625,-128) [-128|127.9375] "m" Vector__XXX
 SG_ Radar1_Obj12_flagValid : 48|1@0+ (1,0) [0|1] "" Vector__XXX
 SG_ Radar1_Obj12_flagHist : 57|1@0+ (1,0) [0|1] "" Vector__XXX
 SG_ Radar1_Obj12_flagMeas : 58|1@0+ (1,0) [0|1] "" Vector__XXX
 SG_ Radar1_Obj12_MessAconsistBit : 56|1@0+ (1,0) [0|1] "" Vector__XXX

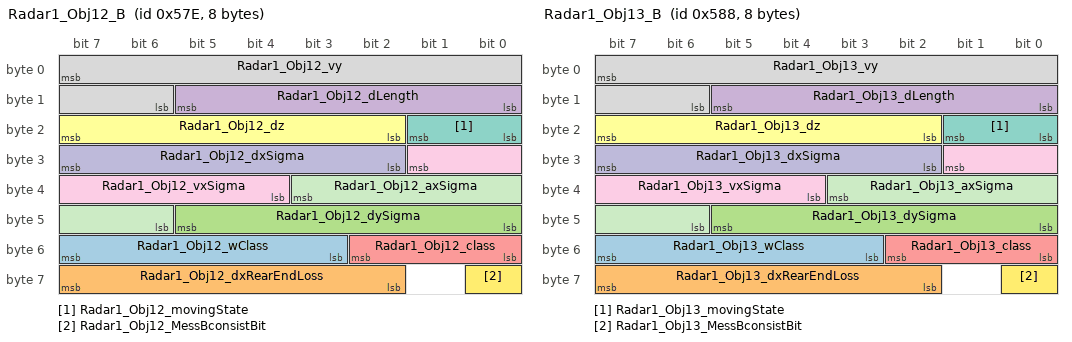
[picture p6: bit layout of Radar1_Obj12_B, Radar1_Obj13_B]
BO_ 1406 Radar1_Obj12_B: 8 Bosch_Radar1
 SG_ Radar1_Obj12_wClass : 55|5@0+ (0.03125,0) [0|0.96875] "" Vector__XXX
 SG_ Radar1_Obj12_dxRearEndLoss : 63|6@0+ (0.125,0) [0|7.875] "m" Vector__XXX
 SG_ Radar1_Obj12_dySigma : 45|6@0+ (0.0625,0) [0|3.9375] "m" Vector__XXX
 SG_ Radar1_Obj12_dLength : 13|6@0+ (0.125,0) [0|7.875] "m" Vector__XXX
 SG_ Radar1_Obj12_class : 50|3@0+ (1,0) [0|7] "" Vector__XXX
 SG_ Radar1_Obj12_dz : 23|6@0+ (0.25,-5) [-5|10.75] "m" Vector__XXX
 SG_ Radar1_Obj12_movingState : 17|2@0+ (1,0) [0|3] "" Vector__XXX
 SG_ Radar1_Obj12_vy : 7|10@0+ (0.125,-64) [-64|63.875] "m/s" Vector__XXX
 SG_ Radar1_Obj12_vxSigma : 25|6@0+ (0.0625,0) [0|3.9375] "m/s" Vector__XXX
 SG_ Radar1_Obj12_dxSigma : 31|6@0+ (0.0625,0) [0|3.9375] "m" Vector__XXX
 SG_ Radar1_Obj12_axSigma : 35|6@0+ (0.0625,0) [0|3.9375] "m/s2" Vector__XXX
 SG_ Radar1_Obj12_MessBconsistBit : 56|1@0+ (1,0) [0|1] "" Vector__XXX

BO_ 1415 Radar1_Obj13_A: 8 Bosch_Radar1
 SG_ Radar1_Obj13_wObstacle : 53|5@0+ (0.03125,0) [0|0.96875] "" Vector__XXX
 SG_ Radar1_Obj13_wNonObstacle : 63|5@0+ (0.03125,0) [0|0.96875] "" Vector__XXX
 SG_ Radar1_Obj13_wExist : 36|5@0+ (0.03125,0) [0|0.96875] "-" Vector__XXX
 SG_ Radar1_Obj13_ax : 47|10@0+ (0.03125,-16) [-16|15.96875] "m/s2" Vector__XXX
 SG_ Radar1_Obj13_vx : 11|12@0+ (0.0625,-128) [-128|127.9375] "m/s" Vector__XXX
 SG_ Radar1_Obj13_dy : 31|11@0+ (0.125,-128) [-128|127.875] "m" Vector__XXX
 SG_ Radar1_Obj13_dx : 7|12@0+ (0.0625,-128) [-128|127.9375] "m" Vector__XXX
 SG_ Radar1_Obj13_flagValid : 48|1@0+ (1,0) [0|1] "" Vector__XXX
 SG_ Radar1_Obj13_flagHist : 57|1@0+ (1,0) [0|1] "" Vector__XXX
 SG_ Radar1_Obj13_flagMeas : 58|1@0+ (1,0) [0|1] "" Vector__XXX
 SG_ Radar1_Obj13_MessAconsistBit : 56|1@0+ (1,0) [0|1] "" Vector__XXX

BO_ 1416 Radar1_Obj13_B: 8 Bosch_Radar1
 SG_ Radar1_Obj13_wClass : 55|5@0+ (0.03125,0) [0|0.96875] "" Vector__XXX
 SG_ Radar1_Obj13_dxRearEndLoss : 63|6@0+ (0.125,0) [0|7.875] "m" Vector__XXX
 SG_ Radar1_Obj13_dySigma : 45|6@0+ (0.0625,0) [0|3.9375] "m" Vector__XXX
 SG_ Radar1_Obj13_dLength : 13|6@0+ (0.125,0) [0|7.875] "m" Vector__XXX
 SG_ Radar1_Obj13_class : 50|3@0+ (1,0) [0|7] "" Vector__XXX
 SG_ Radar1_Obj13_dz : 23|6@0+ (0.25,-5) [-5|10.75] "m" Vector__XXX
 SG_ Radar1_Obj13_movingState : 17|2@0+ (1,0) [0|3] "" Vector__XXX
 SG_ Radar1_Obj13_vy : 7|10@0+ (0.125,-64) [-64|63.875] "m/s" Vector__XXX
 SG_ Radar1_Obj13_vxSigma : 25|6@0+ (0.0625,0) [0|3.9375] "m/s" Vector__XXX
 SG_ Radar1_Obj13_dxSigma : 31|6@0+ (0.0625,0) [0|3.9375] "m" Vector__XXX
 SG_ Radar1_Obj13_axSigma : 35|6@0+ (0.0625,0) [0|3.9375] "m/s2" Vector__XXX
 SG_ Radar1_Obj13_MessBconsistBit : 56|1@0+ (1,0) [0|1] "" Vector__XXX

BO_ 1425 Radar1_Obj14_A: 8 Bosch_Radar1
 SG_ Radar1_Obj14_wObstacle : 53|5@0+ (0.03125,0) [0|0.96875] "" Vector__XXX
 SG_ Radar1_Obj14_wNonObstacle : 63|5@0+ (0.03125,0) [0|0.96875] "" Vector__XXX
 SG_ Radar1_Obj14_wExist : 36|5@0+ (0.03125,0) [0|0.96875] "-" Vector__XXX
 SG_ Radar1_Obj14_ax : 47|10@0+ (0.03125,-16) [-16|15.96875] "m/s2" Vector__XXX
 SG_ Radar1_Obj14_vx : 11|12@0+ (0.0625,-128) [-128|127.9375] "m/s" Vector__XXX
 SG_ Radar1_Obj14_dy : 31|11@0+ (0.125,-128) [-128|127.875] "m" Vector__XXX
 SG_ Radar1_Obj14_dx : 7|12@0+ (0.0625,-128) [-128|127.9375] "m" Vector__XXX
 SG_ Radar1_Obj14_flagValid : 48|1@0+ (1,0) [0|1] "" Vector__XXX
 SG_ Radar1_Obj14_flagHist : 57|1@0+ (1,0) [0|1] "" Vector__XXX
 SG_ Radar1_Obj14_flagMeas : 58|1@0+ (1,0) [0|1] "" Vector__XXX
 SG_ Radar1_Obj14_MessAconsistBit : 56|1@0+ (1,0) [0|1] "" Vector__XXX

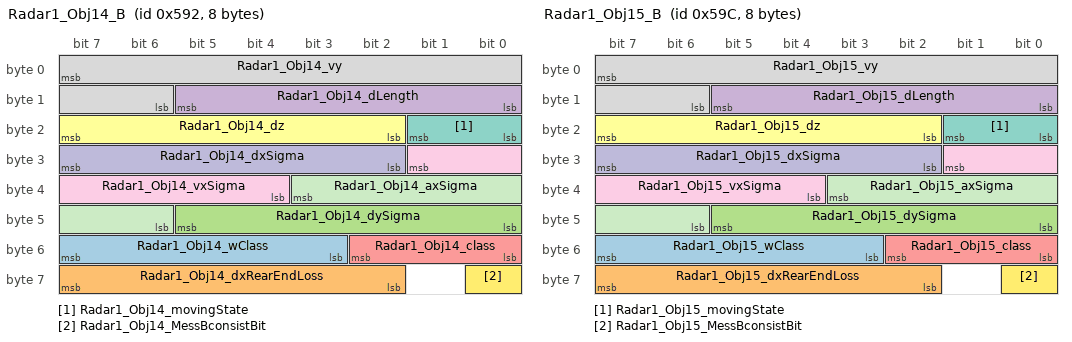
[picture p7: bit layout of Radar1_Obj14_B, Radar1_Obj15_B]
BO_ 1426 Radar1_Obj14_B: 8 Bosch_Radar1
 SG_ Radar1_Obj14_wClass : 55|5@0+ (0.03125,0) [0|0.96875] "" Vector__XXX
 SG_ Radar1_Obj14_dxRearEndLoss : 63|6@0+ (0.125,0) [0|7.875] "m" Vector__XXX
 SG_ Radar1_Obj14_dySigma : 45|6@0+ (0.0625,0) [0|3.9375] "m" Vector__XXX
 SG_ Radar1_Obj14_dLength : 13|6@0+ (0.125,0) [0|7.875] "m" Vector__XXX
 SG_ Radar1_Obj14_class : 50|3@0+ (1,0) [0|7] "" Vector__XXX
 SG_ Radar1_Obj14_dz : 23|6@0+ (0.25,-5) [-5|10.75] "m" Vector__XXX
 SG_ Radar1_Obj14_movingState : 17|2@0+ (1,0) [0|3] "" Vector__XXX
 SG_ Radar1_Obj14_vy : 7|10@0+ (0.125,-64) [-64|63.875] "m/s" Vector__XXX
 SG_ Radar1_Obj14_vxSigma : 25|6@0+ (0.0625,0) [0|3.9375] "m/s" Vector__XXX
 SG_ Radar1_Obj14_dxSigma : 31|6@0+ (0.0625,0) [0|3.9375] "m" Vector__XXX
 SG_ Radar1_Obj14_axSigma : 35|6@0+ (0.0625,0) [0|3.9375] "m/s2" Vector__XXX
 SG_ Radar1_Obj14_MessBconsistBit : 56|1@0+ (1,0) [0|1] "" Vector__XXX

BO_ 1435 Radar1_Obj15_A: 8 Bosch_Radar1
 SG_ Radar1_Obj15_wObstacle : 53|5@0+ (0.03125,0) [0|0.96875] "" Vector__XXX
 SG_ Radar1_Obj15_wNonObstacle : 63|5@0+ (0.03125,0) [0|0.96875] "" Vector__XXX
 SG_ Radar1_Obj15_wExist : 36|5@0+ (0.03125,0) [0|0.96875] "-" Vector__XXX
 SG_ Radar1_Obj15_ax : 47|10@0+ (0.03125,-16) [-16|15.96875] "m/s2" Vector__XXX
 SG_ Radar1_Obj15_vx : 11|12@0+ (0.0625,-128) [-128|127.9375] "m/s" Vector__XXX
 SG_ Radar1_Obj15_dy : 31|11@0+ (0.125,-128) [-128|127.875] "m" Vector__XXX
 SG_ Radar1_Obj15_dx : 7|12@0+ (0.0625,-128) [-128|127.9375] "m" Vector__XXX
 SG_ Radar1_Obj15_flagValid : 48|1@0+ (1,0) [0|1] "" Vector__XXX
 SG_ Radar1_Obj15_flagHist : 57|1@0+ (1,0) [0|1] "" Vector__XXX
 SG_ Radar1_Obj15_flagMeas : 58|1@0+ (1,0) [0|1] "" Vector__XXX
 SG_ Radar1_Obj15_MessAconsistBit : 56|1@0+ (1,0) [0|1] "" Vector__XXX

BO_ 1436 Radar1_Obj15_B: 8 Bosch_Radar1
 SG_ Radar1_Obj15_wClass : 55|5@0+ (0.03125,0) [0|0.96875] "" Vector__XXX
 SG_ Radar1_Obj15_dxRearEndLoss : 63|6@0+ (0.125,0) [0|7.875] "m" Vector__XXX
 SG_ Radar1_Obj15_dySigma : 45|6@0+ (0.0625,0) [0|3.9375] "m" Vector__XXX
 SG_ Radar1_Obj15_dLength : 13|6@0+ (0.125,0) [0|7.875] "m" Vector__XXX
 SG_ Radar1_Obj15_class : 50|3@0+ (1,0) [0|7] "" Vector__XXX
 SG_ Radar1_Obj15_dz : 23|6@0+ (0.25,-5) [-5|10.75] "m" Vector__XXX
 SG_ Radar1_Obj15_movingState : 17|2@0+ (1,0) [0|3] "" Vector__XXX
 SG_ Radar1_Obj15_vy : 7|10@0+ (0.125,-64) [-64|63.875] "m/s" Vector__XXX
 SG_ Radar1_Obj15_vxSigma : 25|6@0+ (0.0625,0) [0|3.9375] "m/s" Vector__XXX
 SG_ Radar1_Obj15_dxSigma : 31|6@0+ (0.0625,0) [0|3.9375] "m" Vector__XXX
 SG_ Radar1_Obj15_axSigma : 35|6@0+ (0.0625,0) [0|3.9375] "m/s2" Vector__XXX
 SG_ Radar1_Obj15_MessBconsistBit : 56|1@0+ (1,0) [0|1] "" Vector__XXX

BO_ 1445 Radar1_Obj16_A: 8 Bosch_Radar1
 SG_ Radar1_Obj16_wObstacle : 53|5@0+ (0.03125,0) [0|0.96875] "" Vector__XXX
 SG_ Radar1_Obj16_wNonObstacle : 63|5@0+ (0.03125,0) [0|0.96875] "" Vector__XXX
 SG_ Radar1_Obj16_wExist : 36|5@0+ (0.03125,0) [0|0.96875] "-" Vector__XXX
 SG_ Radar1_Obj16_ax : 47|10@0+ (0.03125,-16) [-16|15.96875] "m/s2" Vector__XXX
 SG_ Radar1_Obj16_vx : 11|12@0+ (0.0625,-128) [-128|127.9375] "m/s" Vector__XXX
 SG_ Radar1_Obj16_dy : 31|11@0+ (0.125,-128) [-128|127.875] "m" Vector__XXX
 SG_ Radar1_Obj16_dx : 7|12@0+ (0.0625,-128) [-128|127.9375] "m" Vector__XXX
 SG_ Radar1_Obj16_flagValid : 48|1@0+ (1,0) [0|1] "" Vector__XXX
 SG_ Radar1_Obj16_flagHist : 57|1@0+ (1,0) [0|1] "" Vector__XXX
 SG_ Radar1_Obj16_flagMeas : 58|1@0+ (1,0) [0|1] "" Vector__XXX
 SG_ Radar1_Obj16_MessAconsistBit : 56|1@0+ (1,0) [0|1] "" Vector__XXX

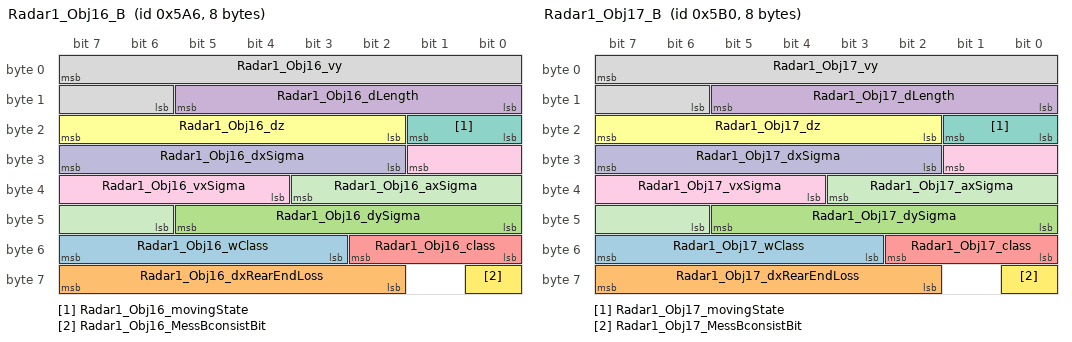
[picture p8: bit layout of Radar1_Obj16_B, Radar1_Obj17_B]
BO_ 1446 Radar1_Obj16_B: 8 Bosch_Radar1
 SG_ Radar1_Obj16_wClass : 55|5@0+ (0.03125,0) [0|0.96875] "" Vector__XXX
 SG_ Radar1_Obj16_dxRearEndLoss : 63|6@0+ (0.125,0) [0|7.875] "m" Vector__XXX
 SG_ Radar1_Obj16_dySigma : 45|6@0+ (0.0625,0) [0|3.9375] "m" Vector__XXX
 SG_ Radar1_Obj16_dLength : 13|6@0+ (0.125,0) [0|7.875] "m" Vector__XXX
 SG_ Radar1_Obj16_class : 50|3@0+ (1,0) [0|7] "" Vector__XXX
 SG_ Radar1_Obj16_dz : 23|6@0+ (0.25,-5) [-5|10.75] "m" Vector__XXX
 SG_ Radar1_Obj16_movingState : 17|2@0+ (1,0) [0|3] "" Vector__XXX
 SG_ Radar1_Obj16_vy : 7|10@0+ (0.125,-64) [-64|63.875] "m/s" Vector__XXX
 SG_ Radar1_Obj16_vxSigma : 25|6@0+ (0.0625,0) [0|3.9375] "m/s" Vector__XXX
 SG_ Radar1_Obj16_dxSigma : 31|6@0+ (0.0625,0) [0|3.9375] "m" Vector__XXX
 SG_ Radar1_Obj16_axSigma : 35|6@0+ (0.0625,0) [0|3.9375] "m/s2" Vector__XXX
 SG_ Radar1_Obj16_MessBconsistBit : 56|1@0+ (1,0) [0|1] "" Vector__XXX

BO_ 1455 Radar1_Obj17_A: 8 Bosch_Radar1
 SG_ Radar1_Obj17_wObstacle : 53|5@0+ (0.03125,0) [0|0.96875] "" Vector__XXX
 SG_ Radar1_Obj17_wNonObstacle : 63|5@0+ (0.03125,0) [0|0.96875] "" Vector__XXX
 SG_ Radar1_Obj17_wExist : 36|5@0+ (0.03125,0) [0|0.96875] "-" Vector__XXX
 SG_ Radar1_Obj17_ax : 47|10@0+ (0.03125,-16) [-16|15.96875] "m/s2" Vector__XXX
 SG_ Radar1_Obj17_vx : 11|12@0+ (0.0625,-128) [-128|127.9375] "m/s" Vector__XXX
 SG_ Radar1_Obj17_dy : 31|11@0+ (0.125,-128) [-128|127.875] "m" Vector__XXX
 SG_ Radar1_Obj17_dx : 7|12@0+ (0.0625,-128) [-128|127.9375] "m" Vector__XXX
 SG_ Radar1_Obj17_flagValid : 48|1@0+ (1,0) [0|1] "" Vector__XXX
 SG_ Radar1_Obj17_flagHist : 57|1@0+ (1,0) [0|1] "" Vector__XXX
 SG_ Radar1_Obj17_flagMeas : 58|1@0+ (1,0) [0|1] "" Vector__XXX
 SG_ Radar1_Obj17_MessAconsistBit : 56|1@0+ (1,0) [0|1] "" Vector__XXX

BO_ 1456 Radar1_Obj17_B: 8 Bosch_Radar1
 SG_ Radar1_Obj17_wClass : 55|5@0+ (0.03125,0) [0|0.96875] "" Vector__XXX
 SG_ Radar1_Obj17_dxRearEndLoss : 63|6@0+ (0.125,0) [0|7.875] "m" Vector__XXX
 SG_ Radar1_Obj17_dySigma : 45|6@0+ (0.0625,0) [0|3.9375] "m" Vector__XXX
 SG_ Radar1_Obj17_dLength : 13|6@0+ (0.125,0) [0|7.875] "m" Vector__XXX
 SG_ Radar1_Obj17_class : 50|3@0+ (1,0) [0|7] "" Vector__XXX
 SG_ Radar1_Obj17_dz : 23|6@0+ (0.25,-5) [-5|10.75] "m" Vector__XXX
 SG_ Radar1_Obj17_movingState : 17|2@0+ (1,0) [0|3] "" Vector__XXX
 SG_ Radar1_Obj17_vy : 7|10@0+ (0.125,-64) [-64|63.875] "m/s" Vector__XXX
 SG_ Radar1_Obj17_vxSigma : 25|6@0+ (0.0625,0) [0|3.9375] "m/s" Vector__XXX
 SG_ Radar1_Obj17_dxSigma : 31|6@0+ (0.0625,0) [0|3.9375] "m" Vector__XXX
 SG_ Radar1_Obj17_axSigma : 35|6@0+ (0.0625,0) [0|3.9375] "m/s2" Vector__XXX
 SG_ Radar1_Obj17_MessBconsistBit : 56|1@0+ (1,0) [0|1] "" Vector__XXX

BO_ 1465 Radar1_Obj18_A: 8 Bosch_Radar1
 SG_ Radar1_Obj18_wObstacle : 53|5@0+ (0.03125,0) [0|0.96875] "" Vector__XXX
 SG_ Radar1_Obj18_wNonObstacle : 63|5@0+ (0.03125,0) [0|0.96875] "" Vector__XXX
 SG_ Radar1_Obj18_wExist : 36|5@0+ (0.03125,0) [0|0.96875] "-" Vector__XXX
 SG_ Radar1_Obj18_ax : 47|10@0+ (0.03125,-16) [-16|15.96875] "m/s2" Vector__XXX
 SG_ Radar1_Obj18_vx : 11|12@0+ (0.0625,-128) [-128|127.9375] "m/s" Vector__XXX
 SG_ Radar1_Obj18_dy : 31|11@0+ (0.125,-128) [-128|127.875] "m" Vector__XXX
 SG_ Radar1_Obj18_dx : 7|12@0+ (0.0625,-128) [-128|127.9375] "m" Vector__XXX
 SG_ Radar1_Obj18_flagValid : 48|1@0+ (1,0) [0|1] "" Vector__XXX
 SG_ Radar1_Obj18_flagHist : 57|1@0+ (1,0) [0|1] "" Vector__XXX
 SG_ Radar1_Obj18_flagMeas : 58|1@0+ (1,0) [0|1] "" Vector__XXX
 SG_ Radar1_Obj18_MessAconsistBit : 56|1@0+ (1,0) [0|1] "" Vector__XXX

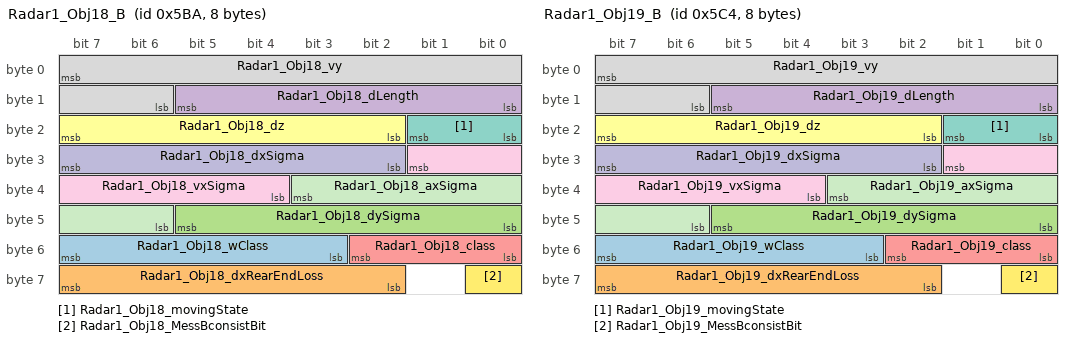
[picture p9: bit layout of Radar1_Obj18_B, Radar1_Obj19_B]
BO_ 1466 Radar1_Obj18_B: 8 Bosch_Radar1
 SG_ Radar1_Obj18_wClass : 55|5@0+ (0.03125,0) [0|0.96875] "" Vector__XXX
 SG_ Radar1_Obj18_dxRearEndLoss : 63|6@0+ (0.125,0) [0|7.875] "m" Vector__XXX
 SG_ Radar1_Obj18_dySigma : 45|6@0+ (0.0625,0) [0|3.9375] "m" Vector__XXX
 SG_ Radar1_Obj18_dLength : 13|6@0+ (0.125,0) [0|7.875] "m" Vector__XXX
 SG_ Radar1_Obj18_class : 50|3@0+ (1,0) [0|7] "" Vector__XXX
 SG_ Radar1_Obj18_dz : 23|6@0+ (0.25,-5) [-5|10.75] "m" Vector__XXX
 SG_ Radar1_Obj18_movingState : 17|2@0+ (1,0) [0|3] "" Vector__XXX
 SG_ Radar1_Obj18_vy : 7|10@0+ (0.125,-64) [-64|63.875] "m/s" Vector__XXX
 SG_ Radar1_Obj18_vxSigma : 25|6@0+ (0.0625,0) [0|3.9375] "m/s" Vector__XXX
 SG_ Radar1_Obj18_dxSigma : 31|6@0+ (0.0625,0) [0|3.9375] "m" Vector__XXX
 SG_ Radar1_Obj18_axSigma : 35|6@0+ (0.0625,0) [0|3.9375] "m/s2" Vector__XXX
 SG_ Radar1_Obj18_MessBconsistBit : 56|1@0+ (1,0) [0|1] "" Vector__XXX

BO_ 1475 Radar1_Obj19_A: 8 Bosch_Radar1
 SG_ Radar1_Obj19_wObstacle : 53|5@0+ (0.03125,0) [0|0.96875] "" Vector__XXX
 SG_ Radar1_Obj19_wNonObstacle : 63|5@0+ (0.03125,0) [0|0.96875] "" Vector__XXX
 SG_ Radar1_Obj19_wExist : 36|5@0+ (0.03125,0) [0|0.96875] "-" Vector__XXX
 SG_ Radar1_Obj19_ax : 47|10@0+ (0.03125,-16) [-16|15.96875] "m/s2" Vector__XXX
 SG_ Radar1_Obj19_vx : 11|12@0+ (0.0625,-128) [-128|127.9375] "m/s" Vector__XXX
 SG_ Radar1_Obj19_dy : 31|11@0+ (0.125,-128) [-128|127.875] "m" Vector__XXX
 SG_ Radar1_Obj19_dx : 7|12@0+ (0.0625,-128) [-128|127.9375] "m" Vector__XXX
 SG_ Radar1_Obj19_flagValid : 48|1@0+ (1,0) [0|1] "" Vector__XXX
 SG_ Radar1_Obj19_flagHist : 57|1@0+ (1,0) [0|1] "" Vector__XXX
 SG_ Radar1_Obj19_flagMeas : 58|1@0+ (1,0) [0|1] "" Vector__XXX
 SG_ Radar1_Obj19_MessAconsistBit : 56|1@0+ (1,0) [0|1] "" Vector__XXX

BO_ 1476 Radar1_Obj19_B: 8 Bosch_Radar1
 SG_ Radar1_Obj19_wClass : 55|5@0+ (0.03125,0) [0|0.96875] "" Vector__XXX
 SG_ Radar1_Obj19_dxRearEndLoss : 63|6@0+ (0.125,0) [0|7.875] "m" Vector__XXX
 SG_ Radar1_Obj19_dySigma : 45|6@0+ (0.0625,0) [0|3.9375] "m" Vector__XXX
 SG_ Radar1_Obj19_dLength : 13|6@0+ (0.125,0) [0|7.875] "m" Vector__XXX
 SG_ Radar1_Obj19_class : 50|3@0+ (1,0) [0|7] "" Vector__XXX
 SG_ Radar1_Obj19_dz : 23|6@0+ (0.25,-5) [-5|10.75] "m" Vector__XXX
 SG_ Radar1_Obj19_movingState : 17|2@0+ (1,0) [0|3] "" Vector__XXX
 SG_ Radar1_Obj19_vy : 7|10@0+ (0.125,-64) [-64|63.875] "m/s" Vector__XXX
 SG_ Radar1_Obj19_vxSigma : 25|6@0+ (0.0625,0) [0|3.9375] "m/s" Vector__XXX
 SG_ Radar1_Obj19_dxSigma : 31|6@0+ (0.0625,0) [0|3.9375] "m" Vector__XXX
 SG_ Radar1_Obj19_axSigma : 35|6@0+ (0.0625,0) [0|3.9375] "m/s2" Vector__XXX
 SG_ Radar1_Obj19_MessBconsistBit : 56|1@0+ (1,0) [0|1] "" Vector__XXX

BO_ 1485 Radar1_Obj20_A: 8 Bosch_Radar1
 SG_ Radar1_Obj20_wObstacle : 53|5@0+ (0.03125,0) [0|0.96875] "" Vector__XXX
 SG_ Radar1_Obj20_wNonObstacle : 63|5@0+ (0.03125,0) [0|0.96875] "" Vector__XXX
 SG_ Radar1_Obj20_wExist : 36|5@0+ (0.03125,0) [0|0.96875] "-" Vector__XXX
 SG_ Radar1_Obj20_ax : 47|10@0+ (0.03125,-16) [-16|15.96875] "m/s2" Vector__XXX
 SG_ Radar1_Obj20_vx : 11|12@0+ (0.0625,-128) [-128|127.9375] "m/s" Vector__XXX
 SG_ Radar1_Obj20_dy : 31|11@0+ (0.125,-128) [-128|127.875] "m" Vector__XXX
 SG_ Radar1_Obj20_dx : 7|12@0+ (0.0625,-128) [-128|127.9375] "m" Vector__XXX
 SG_ Radar1_Obj20_flagValid : 48|1@0+ (1,0) [0|1] "" Vector__XXX
 SG_ Radar1_Obj20_flagHist : 57|1@0+ (1,0) [0|1] "" Vector__XXX
 SG_ Radar1_Obj20_flagMeas : 58|1@0+ (1,0) [0|1] "" Vector__XXX
 SG_ Radar1_Obj20_MessAconsistBit : 56|1@0+ (1,0) [0|1] "" Vector__XXX

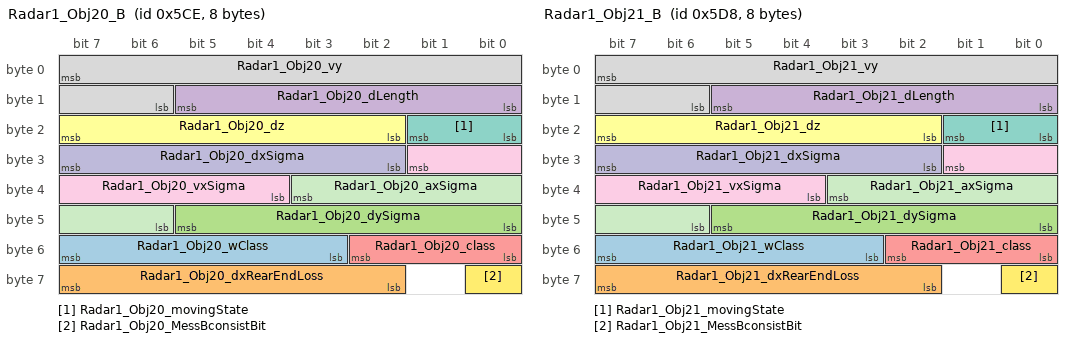
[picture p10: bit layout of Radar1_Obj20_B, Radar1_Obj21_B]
BO_ 1486 Radar1_Obj20_B: 8 Bosch_Radar1
 SG_ Radar1_Obj20_wClass : 55|5@0+ (0.03125,0) [0|0.96875] "" Vector__XXX
 SG_ Radar1_Obj20_dxRearEndLoss : 63|6@0+ (0.125,0) [0|7.875] "m" Vector__XXX
 SG_ Radar1_Obj20_dySigma : 45|6@0+ (0.0625,0) [0|3.9375] "m" Vector__XXX
 SG_ Radar1_Obj20_dLength : 13|6@0+ (0.125,0) [0|7.875] "m" Vector__XXX
 SG_ Radar1_Obj20_class : 50|3@0+ (1,0) [0|7] "" Vector__XXX
 SG_ Radar1_Obj20_dz : 23|6@0+ (0.25,-5) [-5|10.75] "m" Vector__XXX
 SG_ Radar1_Obj20_movingState : 17|2@0+ (1,0) [0|3] "" Vector__XXX
 SG_ Radar1_Obj20_vy : 7|10@0+ (0.125,-64) [-64|63.875] "m/s" Vector__XXX
 SG_ Radar1_Obj20_vxSigma : 25|6@0+ (0.0625,0) [0|3.9375] "m/s" Vector__XXX
 SG_ Radar1_Obj20_dxSigma : 31|6@0+ (0.0625,0) [0|3.9375] "m" Vector__XXX
 SG_ Radar1_Obj20_axSigma : 35|6@0+ (0.0625,0) [0|3.9375] "m/s2" Vector__XXX
 SG_ Radar1_Obj20_MessBconsistBit : 56|1@0+ (1,0) [0|1] "" Vector__XXX

BO_ 1495 Radar1_Obj21_A: 8 Bosch_Radar1
 SG_ Radar1_Obj21_wObstacle : 53|5@0+ (0.03125,0) [0|0.96875] "" Vector__XXX
 SG_ Radar1_Obj21_wNonObstacle : 63|5@0+ (0.03125,0) [0|0.96875] "" Vector__XXX
 SG_ Radar1_Obj21_wExist : 36|5@0+ (0.03125,0) [0|0.96875] "-" Vector__XXX
 SG_ Radar1_Obj21_ax : 47|10@0+ (0.03125,-16) [-16|15.96875] "m/s2" Vector__XXX
 SG_ Radar1_Obj21_vx : 11|12@0+ (0.0625,-128) [-128|127.9375] "m/s" Vector__XXX
 SG_ Radar1_Obj21_dy : 31|11@0+ (0.125,-128) [-128|127.875] "m" Vector__XXX
 SG_ Radar1_Obj21_dx : 7|12@0+ (0.0625,-128) [-128|127.9375] "m" Vector__XXX
 SG_ Radar1_Obj21_flagValid : 48|1@0+ (1,0) [0|1] "" Vector__XXX
 SG_ Radar1_Obj21_flagHist : 57|1@0+ (1,0) [0|1] "" Vector__XXX
 SG_ Radar1_Obj21_flagMeas : 58|1@0+ (1,0) [0|1] "" Vector__XXX
 SG_ Radar1_Obj21_MessAconsistBit : 56|1@0+ (1,0) [0|1] "" Vector__XXX

BO_ 1496 Radar1_Obj21_B: 8 Bosch_Radar1
 SG_ Radar1_Obj21_wClass : 55|5@0+ (0.03125,0) [0|0.96875] "" Vector__XXX
 SG_ Radar1_Obj21_dxRearEndLoss : 63|6@0+ (0.125,0) [0|7.875] "m" Vector__XXX
 SG_ Radar1_Obj21_dySigma : 45|6@0+ (0.0625,0) [0|3.9375] "m" Vector__XXX
 SG_ Radar1_Obj21_dLength : 13|6@0+ (0.125,0) [0|7.875] "m" Vector__XXX
 SG_ Radar1_Obj21_class : 50|3@0+ (1,0) [0|7] "" Vector__XXX
 SG_ Radar1_Obj21_dz : 23|6@0+ (0.25,-5) [-5|10.75] "m" Vector__XXX
 SG_ Radar1_Obj21_movingState : 17|2@0+ (1,0) [0|3] "" Vector__XXX
 SG_ Radar1_Obj21_vy : 7|10@0+ (0.125,-64) [-64|63.875] "m/s" Vector__XXX
 SG_ Radar1_Obj21_vxSigma : 25|6@0+ (0.0625,0) [0|3.9375] "m/s" Vector__XXX
 SG_ Radar1_Obj21_dxSigma : 31|6@0+ (0.0625,0) [0|3.9375] "m" Vector__XXX
 SG_ Radar1_Obj21_axSigma : 35|6@0+ (0.0625,0) [0|3.9375] "m/s2" Vector__XXX
 SG_ Radar1_Obj21_MessBconsistBit : 56|1@0+ (1,0) [0|1] "" Vector__XXX

BO_ 1505 Radar1_Obj22_A: 8 Bosch_Radar1
 SG_ Radar1_Obj22_wObstacle : 53|5@0+ (0.03125,0) [0|0.96875] "" Vector__XXX
 SG_ Radar1_Obj22_wNonObstacle : 63|5@0+ (0.03125,0) [0|0.96875] "" Vector__XXX
 SG_ Radar1_Obj22_wExist : 36|5@0+ (0.03125,0) [0|0.96875] "-" Vector__XXX
 SG_ Radar1_Obj22_ax : 47|10@0+ (0.03125,-16) [-16|15.96875] "m/s2" Vector__XXX
 SG_ Radar1_Obj22_vx : 11|12@0+ (0.0625,-128) [-128|127.9375] "m/s" Vector__XXX
 SG_ Radar1_Obj22_dy : 31|11@0+ (0.125,-128) [-128|127.875] "m" Vector__XXX
 SG_ Radar1_Obj22_dx : 7|12@0+ (0.0625,-128) [-128|127.9375] "m" Vector__XXX
 SG_ Radar1_Obj22_flagValid : 48|1@0+ (1,0) [0|1] "" Vector__XXX
 SG_ Radar1_Obj22_flagHist : 57|1@0+ (1,0) [0|1] "" Vector__XXX
 SG_ Radar1_Obj22_flagMeas : 58|1@0+ (1,0) [0|1] "" Vector__XXX
 SG_ Radar1_Obj22_MessAconsistBit : 56|1@0+ (1,0) [0|1] "" Vector__XXX

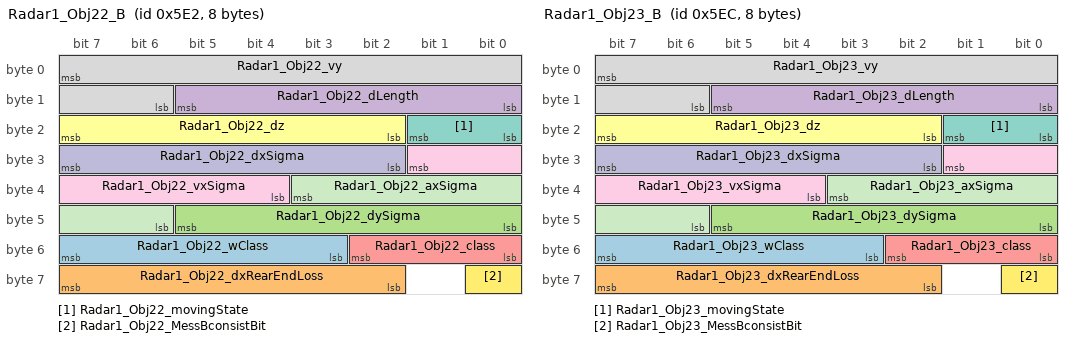
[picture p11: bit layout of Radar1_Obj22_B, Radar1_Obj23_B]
BO_ 1506 Radar1_Obj22_B: 8 Bosch_Radar1
 SG_ Radar1_Obj22_wClass : 55|5@0+ (0.03125,0) [0|0.96875] "" Vector__XXX
 SG_ Radar1_Obj22_dxRearEndLoss : 63|6@0+ (0.125,0) [0|7.875] "m" Vector__XXX
 SG_ Radar1_Obj22_dySigma : 45|6@0+ (0.0625,0) [0|3.9375] "m" Vector__XXX
 SG_ Radar1_Obj22_dLength : 13|6@0+ (0.125,0) [0|7.875] "m" Vector__XXX
 SG_ Radar1_Obj22_class : 50|3@0+ (1,0) [0|7] "" Vector__XXX
 SG_ Radar1_Obj22_dz : 23|6@0+ (0.25,-5) [-5|10.75] "m" Vector__XXX
 SG_ Radar1_Obj22_movingState : 17|2@0+ (1,0) [0|3] "" Vector__XXX
 SG_ Radar1_Obj22_vy : 7|10@0+ (0.125,-64) [-64|63.875] "m/s" Vector__XXX
 SG_ Radar1_Obj22_vxSigma : 25|6@0+ (0.0625,0) [0|3.9375] "m/s" Vector__XXX
 SG_ Radar1_Obj22_dxSigma : 31|6@0+ (0.0625,0) [0|3.9375] "m" Vector__XXX
 SG_ Radar1_Obj22_axSigma : 35|6@0+ (0.0625,0) [0|3.9375] "m/s2" Vector__XXX
 SG_ Radar1_Obj22_MessBconsistBit : 56|1@0+ (1,0) [0|1] "" Vector__XXX

BO_ 1515 Radar1_Obj23_A: 8 Bosch_Radar1
 SG_ Radar1_Obj23_wObstacle : 53|5@0+ (0.03125,0) [0|0.96875] "" Vector__XXX
 SG_ Radar1_Obj23_wNonObstacle : 63|5@0+ (0.03125,0) [0|0.96875] "" Vector__XXX
 SG_ Radar1_Obj23_wExist : 36|5@0+ (0.03125,0) [0|0.96875] "-" Vector__XXX
 SG_ Radar1_Obj23_ax : 47|10@0+ (0.03125,-16) [-16|15.96875] "m/s2" Vector__XXX
 SG_ Radar1_Obj23_vx : 11|12@0+ (0.0625,-128) [-128|127.9375] "m/s" Vector__XXX
 SG_ Radar1_Obj23_dy : 31|11@0+ (0.125,-128) [-128|127.875] "m" Vector__XXX
 SG_ Radar1_Obj23_dx : 7|12@0+ (0.0625,-128) [-128|127.9375] "m" Vector__XXX
 SG_ Radar1_Obj23_flagValid : 48|1@0+ (1,0) [0|1] "" Vector__XXX
 SG_ Radar1_Obj23_flagHist : 57|1@0+ (1,0) [0|1] "" Vector__XXX
 SG_ Radar1_Obj23_flagMeas : 58|1@0+ (1,0) [0|1] "" Vector__XXX
 SG_ Radar1_Obj23_MessAconsistBit : 56|1@0+ (1,0) [0|1] "" Vector__XXX

BO_ 1516 Radar1_Obj23_B: 8 Bosch_Radar1
 SG_ Radar1_Obj23_wClass : 55|5@0+ (0.03125,0) [0|0.96875] "" Vector__XXX
 SG_ Radar1_Obj23_dxRearEndLoss : 63|6@0+ (0.125,0) [0|7.875] "m" Vector__XXX
 SG_ Radar1_Obj23_dySigma : 45|6@0+ (0.0625,0) [0|3.9375] "m" Vector__XXX
 SG_ Radar1_Obj23_dLength : 13|6@0+ (0.125,0) [0|7.875] "m" Vector__XXX
 SG_ Radar1_Obj23_class : 50|3@0+ (1,0) [0|7] "" Vector__XXX
 SG_ Radar1_Obj23_dz : 23|6@0+ (0.25,-5) [-5|10.75] "m" Vector__XXX
 SG_ Radar1_Obj23_movingState : 17|2@0+ (1,0) [0|3] "" Vector__XXX
 SG_ Radar1_Obj23_vy : 7|10@0+ (0.125,-64) [-64|63.875] "m/s" Vector__XXX
 SG_ Radar1_Obj23_vxSigma : 25|6@0+ (0.0625,0) [0|3.9375] "m/s" Vector__XXX
 SG_ Radar1_Obj23_dxSigma : 31|6@0+ (0.0625,0) [0|3.9375] "m" Vector__XXX
 SG_ Radar1_Obj23_axSigma : 35|6@0+ (0.0625,0) [0|3.9375] "m/s2" Vector__XXX
 SG_ Radar1_Obj23_MessBconsistBit : 56|1@0+ (1,0) [0|1] "" Vector__XXX

BO_ 1525 Radar1_Obj24_A: 8 Bosch_Radar1
 SG_ Radar1_Obj24_wObstacle : 53|5@0+ (0.03125,0) [0|0.96875] "" Vector__XXX
 SG_ Radar1_Obj24_wNonObstacle : 63|5@0+ (0.03125,0) [0|0.96875] "" Vector__XXX
 SG_ Radar1_Obj24_wExist : 36|5@0+ (0.03125,0) [0|0.96875] "-" Vector__XXX
 SG_ Radar1_Obj24_ax : 47|10@0+ (0.03125,-16) [-16|15.96875] "m/s2" Vector__XXX
 SG_ Radar1_Obj24_vx : 11|12@0+ (0.0625,-128) [-128|127.9375] "m/s" Vector__XXX
 SG_ Radar1_Obj24_dy : 31|11@0+ (0.125,-128) [-128|127.875] "m" Vector__XXX
 SG_ Radar1_Obj24_dx : 7|12@0+ (0.0625,-128) [-128|127.9375] "m" Vector__XXX
 SG_ Radar1_Obj24_flagValid : 48|1@0+ (1,0) [0|1] "" Vector__XXX
 SG_ Radar1_Obj24_flagHist : 57|1@0+ (1,0) [0|1] "" Vector__XXX
 SG_ Radar1_Obj24_flagMeas : 58|1@0+ (1,0) [0|1] "" Vector__XXX
 SG_ Radar1_Obj24_MessAconsistBit : 56|1@0+ (1,0) [0|1] "" Vector__XXX

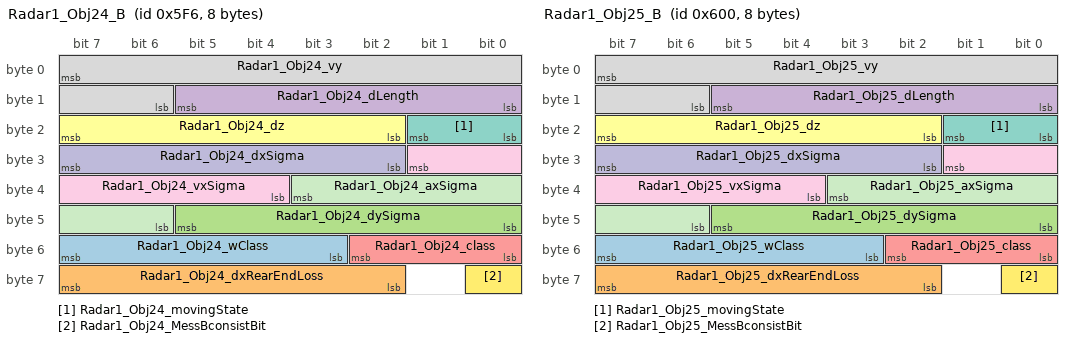
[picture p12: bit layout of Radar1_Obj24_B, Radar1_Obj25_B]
BO_ 1526 Radar1_Obj24_B: 8 Bosch_Radar1
 SG_ Radar1_Obj24_wClass : 55|5@0+ (0.03125,0) [0|0.96875] "" Vector__XXX
 SG_ Radar1_Obj24_dxRearEndLoss : 63|6@0+ (0.125,0) [0|7.875] "m" Vector__XXX
 SG_ Radar1_Obj24_dySigma : 45|6@0+ (0.0625,0) [0|3.9375] "m" Vector__XXX
 SG_ Radar1_Obj24_dLength : 13|6@0+ (0.125,0) [0|7.875] "m" Vector__XXX
 SG_ Radar1_Obj24_class : 50|3@0+ (1,0) [0|7] "" Vector__XXX
 SG_ Radar1_Obj24_dz : 23|6@0+ (0.25,-5) [-5|10.75] "m" Vector__XXX
 SG_ Radar1_Obj24_movingState : 17|2@0+ (1,0) [0|3] "" Vector__XXX
 SG_ Radar1_Obj24_vy : 7|10@0+ (0.125,-64) [-64|63.875] "m/s" Vector__XXX
 SG_ Radar1_Obj24_vxSigma : 25|6@0+ (0.0625,0) [0|3.9375] "m/s" Vector__XXX
 SG_ Radar1_Obj24_dxSigma : 31|6@0+ (0.0625,0) [0|3.9375] "m" Vector__XXX
 SG_ Radar1_Obj24_axSigma : 35|6@0+ (0.0625,0) [0|3.9375] "m/s2" Vector__XXX
 SG_ Radar1_Obj24_MessBconsistBit : 56|1@0+ (1,0) [0|1] "" Vector__XXX

BO_ 1535 Radar1_Obj25_A: 8 Bosch_Radar1
 SG_ Radar1_Obj25_wObstacle : 53|5@0+ (0.03125,0) [0|0.96875] "" Vector__XXX
 SG_ Radar1_Obj25_wNonObstacle : 63|5@0+ (0.03125,0) [0|0.96875] "" Vector__XXX
 SG_ Radar1_Obj25_wExist : 36|5@0+ (0.03125,0) [0|0.96875] "-" Vector__XXX
 SG_ Radar1_Obj25_ax : 47|10@0+ (0.03125,-16) [-16|15.96875] "m/s2" Vector__XXX
 SG_ Radar1_Obj25_vx : 11|12@0+ (0.0625,-128) [-128|127.9375] "m/s" Vector__XXX
 SG_ Radar1_Obj25_dy : 31|11@0+ (0.125,-128) [-128|127.875] "m" Vector__XXX
 SG_ Radar1_Obj25_dx : 7|12@0+ (0.0625,-128) [-128|127.9375] "m" Vector__XXX
 SG_ Radar1_Obj25_flagValid : 48|1@0+ (1,0) [0|1] "" Vector__XXX
 SG_ Radar1_Obj25_flagHist : 57|1@0+ (1,0) [0|1] "" Vector__XXX
 SG_ Radar1_Obj25_flagMeas : 58|1@0+ (1,0) [0|1] "" Vector__XXX
 SG_ Radar1_Obj25_MessAconsistBit : 56|1@0+ (1,0) [0|1] "" Vector__XXX

BO_ 1536 Radar1_Obj25_B: 8 Bosch_Radar1
 SG_ Radar1_Obj25_wClass : 55|5@0+ (0.03125,0) [0|0.96875] "" Vector__XXX
 SG_ Radar1_Obj25_dxRearEndLoss : 63|6@0+ (0.125,0) [0|7.875] "m" Vector__XXX
 SG_ Radar1_Obj25_dySigma : 45|6@0+ (0.0625,0) [0|3.9375] "m" Vector__XXX
 SG_ Radar1_Obj25_dLength : 13|6@0+ (0.125,0) [0|7.875] "m" Vector__XXX
 SG_ Radar1_Obj25_class : 50|3@0+ (1,0) [0|7] "" Vector__XXX
 SG_ Radar1_Obj25_dz : 23|6@0+ (0.25,-5) [-5|10.75] "m" Vector__XXX
 SG_ Radar1_Obj25_movingState : 17|2@0+ (1,0) [0|3] "" Vector__XXX
 SG_ Radar1_Obj25_vy : 7|10@0+ (0.125,-64) [-64|63.875] "m/s" Vector__XXX
 SG_ Radar1_Obj25_vxSigma : 25|6@0+ (0.0625,0) [0|3.9375] "m/s" Vector__XXX
 SG_ Radar1_Obj25_dxSigma : 31|6@0+ (0.0625,0) [0|3.9375] "m" Vector__XXX
 SG_ Radar1_Obj25_axSigma : 35|6@0+ (0.0625,0) [0|3.9375] "m/s2" Vector__XXX
 SG_ Radar1_Obj25_MessBconsistBit : 56|1@0+ (1,0) [0|1] "" Vector__XXX

BO_ 1545 Radar1_Obj26_A: 8 Bosch_Radar1
 SG_ Radar1_Obj26_wObstacle : 53|5@0+ (0.03125,0) [0|0.96875] "" Vector__XXX
 SG_ Radar1_Obj26_wNonObstacle : 63|5@0+ (0.03125,0) [0|0.96875] "" Vector__XXX
 SG_ Radar1_Obj26_wExist : 36|5@0+ (0.03125,0) [0|0.96875] "-" Vector__XXX
 SG_ Radar1_Obj26_ax : 47|10@0+ (0.03125,-16) [-16|15.96875] "m/s2" Vector__XXX
 SG_ Radar1_Obj26_vx : 11|12@0+ (0.0625,-128) [-128|127.9375] "m/s" Vector__XXX
 SG_ Radar1_Obj26_dy : 31|11@0+ (0.125,-128) [-128|127.875] "m" Vector__XXX
 SG_ Radar1_Obj26_dx : 7|12@0+ (0.0625,-128) [-128|127.9375] "m" Vector__XXX
 SG_ Radar1_Obj26_flagValid : 48|1@0+ (1,0) [0|1] "" Vector__XXX
 SG_ Radar1_Obj26_flagHist : 57|1@0+ (1,0) [0|1] "" Vector__XXX
 SG_ Radar1_Obj26_flagMeas : 58|1@0+ (1,0) [0|1] "" Vector__XXX
 SG_ Radar1_Obj26_MessAconsistBit : 56|1@0+ (1,0) [0|1] "" Vector__XXX

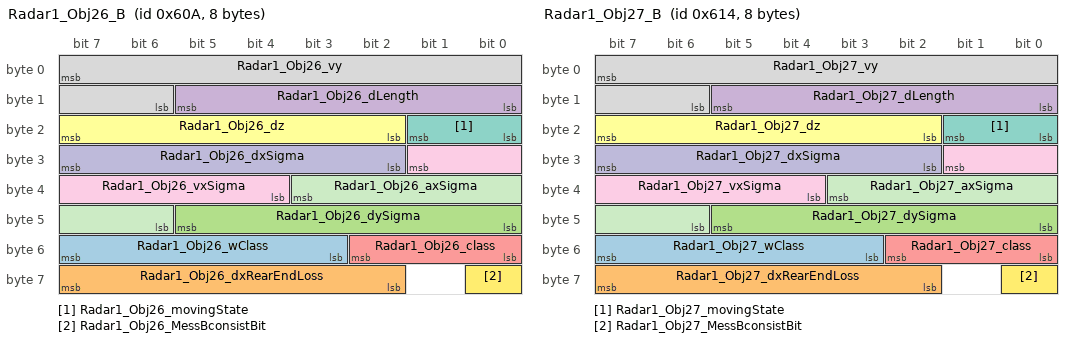
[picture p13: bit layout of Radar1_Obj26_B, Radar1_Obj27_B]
BO_ 1546 Radar1_Obj26_B: 8 Bosch_Radar1
 SG_ Radar1_Obj26_wClass : 55|5@0+ (0.03125,0) [0|0.96875] "" Vector__XXX
 SG_ Radar1_Obj26_dxRearEndLoss : 63|6@0+ (0.125,0) [0|7.875] "m" Vector__XXX
 SG_ Radar1_Obj26_dySigma : 45|6@0+ (0.0625,0) [0|3.9375] "m" Vector__XXX
 SG_ Radar1_Obj26_dLength : 13|6@0+ (0.125,0) [0|7.875] "m" Vector__XXX
 SG_ Radar1_Obj26_class : 50|3@0+ (1,0) [0|7] "" Vector__XXX
 SG_ Radar1_Obj26_dz : 23|6@0+ (0.25,-5) [-5|10.75] "m" Vector__XXX
 SG_ Radar1_Obj26_movingState : 17|2@0+ (1,0) [0|3] "" Vector__XXX
 SG_ Radar1_Obj26_vy : 7|10@0+ (0.125,-64) [-64|63.875] "m/s" Vector__XXX
 SG_ Radar1_Obj26_vxSigma : 25|6@0+ (0.0625,0) [0|3.9375] "m/s" Vector__XXX
 SG_ Radar1_Obj26_dxSigma : 31|6@0+ (0.0625,0) [0|3.9375] "m" Vector__XXX
 SG_ Radar1_Obj26_axSigma : 35|6@0+ (0.0625,0) [0|3.9375] "m/s2" Vector__XXX
 SG_ Radar1_Obj26_MessBconsistBit : 56|1@0+ (1,0) [0|1] "" Vector__XXX

BO_ 1555 Radar1_Obj27_A: 8 Bosch_Radar1
 SG_ Radar1_Obj27_wObstacle : 53|5@0+ (0.03125,0) [0|0.96875] "" Vector__XXX
 SG_ Radar1_Obj27_wNonObstacle : 63|5@0+ (0.03125,0) [0|0.96875] "" Vector__XXX
 SG_ Radar1_Obj27_wExist : 36|5@0+ (0.03125,0) [0|0.96875] "-" Vector__XXX
 SG_ Radar1_Obj27_ax : 47|10@0+ (0.03125,-16) [-16|15.96875] "m/s2" Vector__XXX
 SG_ Radar1_Obj27_vx : 11|12@0+ (0.0625,-128) [-128|127.9375] "m/s" Vector__XXX
 SG_ Radar1_Obj27_dy : 31|11@0+ (0.125,-128) [-128|127.875] "m" Vector__XXX
 SG_ Radar1_Obj27_dx : 7|12@0+ (0.0625,-128) [-128|127.9375] "m" Vector__XXX
 SG_ Radar1_Obj27_flagValid : 48|1@0+ (1,0) [0|1] "" Vector__XXX
 SG_ Radar1_Obj27_flagHist : 57|1@0+ (1,0) [0|1] "" Vector__XXX
 SG_ Radar1_Obj27_flagMeas : 58|1@0+ (1,0) [0|1] "" Vector__XXX
 SG_ Radar1_Obj27_MessAconsistBit : 56|1@0+ (1,0) [0|1] "" Vector__XXX

BO_ 1556 Radar1_Obj27_B: 8 Bosch_Radar1
 SG_ Radar1_Obj27_wClass : 55|5@0+ (0.03125,0) [0|0.96875] "" Vector__XXX
 SG_ Radar1_Obj27_dxRearEndLoss : 63|6@0+ (0.125,0) [0|7.875] "m" Vector__XXX
 SG_ Radar1_Obj27_dySigma : 45|6@0+ (0.0625,0) [0|3.9375] "m" Vector__XXX
 SG_ Radar1_Obj27_dLength : 13|6@0+ (0.125,0) [0|7.875] "m" Vector__XXX
 SG_ Radar1_Obj27_class : 50|3@0+ (1,0) [0|7] "" Vector__XXX
 SG_ Radar1_Obj27_dz : 23|6@0+ (0.25,-5) [-5|10.75] "m" Vector__XXX
 SG_ Radar1_Obj27_movingState : 17|2@0+ (1,0) [0|3] "" Vector__XXX
 SG_ Radar1_Obj27_vy : 7|10@0+ (0.125,-64) [-64|63.875] "m/s" Vector__XXX
 SG_ Radar1_Obj27_vxSigma : 25|6@0+ (0.0625,0) [0|3.9375] "m/s" Vector__XXX
 SG_ Radar1_Obj27_dxSigma : 31|6@0+ (0.0625,0) [0|3.9375] "m" Vector__XXX
 SG_ Radar1_Obj27_axSigma : 35|6@0+ (0.0625,0) [0|3.9375] "m/s2" Vector__XXX
 SG_ Radar1_Obj27_MessBconsistBit : 56|1@0+ (1,0) [0|1] "" Vector__XXX

BO_ 1565 Radar1_Obj28_A: 8 Bosch_Radar1
 SG_ Radar1_Obj28_wObstacle : 53|5@0+ (0.03125,0) [0|0.96875] "" Vector__XXX
 SG_ Radar1_Obj28_wNonObstacle : 63|5@0+ (0.03125,0) [0|0.96875] "" Vector__XXX
 SG_ Radar1_Obj28_wExist : 36|5@0+ (0.03125,0) [0|0.96875] "-" Vector__XXX
 SG_ Radar1_Obj28_ax : 47|10@0+ (0.03125,-16) [-16|15.96875] "m/s2" Vector__XXX
 SG_ Radar1_Obj28_vx : 11|12@0+ (0.0625,-128) [-128|127.9375] "m/s" Vector__XXX
 SG_ Radar1_Obj28_dy : 31|11@0+ (0.125,-128) [-128|127.875] "m" Vector__XXX
 SG_ Radar1_Obj28_dx : 7|12@0+ (0.0625,-128) [-128|127.9375] "m" Vector__XXX
 SG_ Radar1_Obj28_flagValid : 48|1@0+ (1,0) [0|1] "" Vector__XXX
 SG_ Radar1_Obj28_flagHist : 57|1@0+ (1,0) [0|1] "" Vector__XXX
 SG_ Radar1_Obj28_flagMeas : 58|1@0+ (1,0) [0|1] "" Vector__XXX
 SG_ Radar1_Obj28_MessAconsistBit : 56|1@0+ (1,0) [0|1] "" Vector__XXX

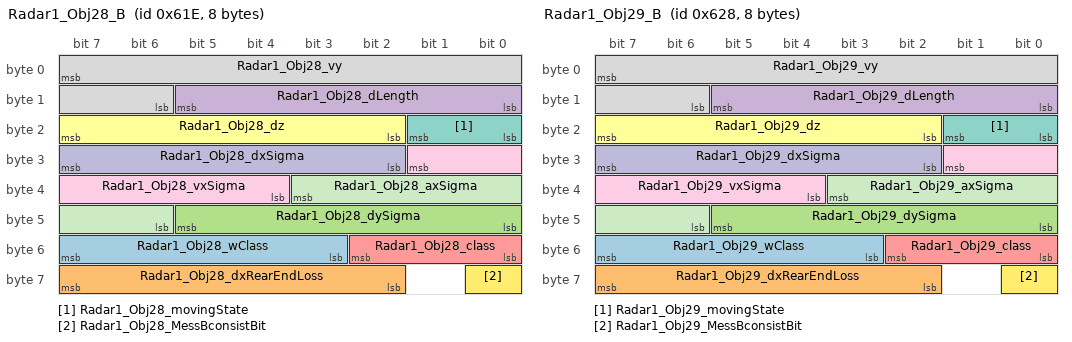
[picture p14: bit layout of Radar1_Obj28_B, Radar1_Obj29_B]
BO_ 1566 Radar1_Obj28_B: 8 Bosch_Radar1
 SG_ Radar1_Obj28_wClass : 55|5@0+ (0.03125,0) [0|0.96875] "" Vector__XXX
 SG_ Radar1_Obj28_dxRearEndLoss : 63|6@0+ (0.125,0) [0|7.875] "m" Vector__XXX
 SG_ Radar1_Obj28_dySigma : 45|6@0+ (0.0625,0) [0|3.9375] "m" Vector__XXX
 SG_ Radar1_Obj28_dLength : 13|6@0+ (0.125,0) [0|7.875] "m" Vector__XXX
 SG_ Radar1_Obj28_class : 50|3@0+ (1,0) [0|7] "" Vector__XXX
 SG_ Radar1_Obj28_dz : 23|6@0+ (0.25,-5) [-5|10.75] "m" Vector__XXX
 SG_ Radar1_Obj28_movingState : 17|2@0+ (1,0) [0|3] "" Vector__XXX
 SG_ Radar1_Obj28_vy : 7|10@0+ (0.125,-64) [-64|63.875] "m/s" Vector__XXX
 SG_ Radar1_Obj28_vxSigma : 25|6@0+ (0.0625,0) [0|3.9375] "m/s" Vector__XXX
 SG_ Radar1_Obj28_dxSigma : 31|6@0+ (0.0625,0) [0|3.9375] "m" Vector__XXX
 SG_ Radar1_Obj28_axSigma : 35|6@0+ (0.0625,0) [0|3.9375] "m/s2" Vector__XXX
 SG_ Radar1_Obj28_MessBconsistBit : 56|1@0+ (1,0) [0|1] "" Vector__XXX

BO_ 1575 Radar1_Obj29_A: 8 Bosch_Radar1
 SG_ Radar1_Obj29_wObstacle : 53|5@0+ (0.03125,0) [0|0.96875] "" Vector__XXX
 SG_ Radar1_Obj29_wNonObstacle : 63|5@0+ (0.03125,0) [0|0.96875] "" Vector__XXX
 SG_ Radar1_Obj29_wExist : 36|5@0+ (0.03125,0) [0|0.96875] "-" Vector__XXX
 SG_ Radar1_Obj29_ax : 47|10@0+ (0.03125,-16) [-16|15.96875] "m/s2" Vector__XXX
 SG_ Radar1_Obj29_vx : 11|12@0+ (0.0625,-128) [-128|127.9375] "m/s" Vector__XXX
 SG_ Radar1_Obj29_dy : 31|11@0+ (0.125,-128) [-128|127.875] "m" Vector__XXX
 SG_ Radar1_Obj29_dx : 7|12@0+ (0.0625,-128) [-128|127.9375] "m" Vector__XXX
 SG_ Radar1_Obj29_flagValid : 48|1@0+ (1,0) [0|1] "" Vector__XXX
 SG_ Radar1_Obj29_flagHist : 57|1@0+ (1,0) [0|1] "" Vector__XXX
 SG_ Radar1_Obj29_flagMeas : 58|1@0+ (1,0) [0|1] "" Vector__XXX
 SG_ Radar1_Obj29_MessAconsistBit : 56|1@0+ (1,0) [0|1] "" Vector__XXX

BO_ 1576 Radar1_Obj29_B: 8 Bosch_Radar1
 SG_ Radar1_Obj29_wClass : 55|5@0+ (0.03125,0) [0|0.96875] "" Vector__XXX
 SG_ Radar1_Obj29_dxRearEndLoss : 63|6@0+ (0.125,0) [0|7.875] "m" Vector__XXX
 SG_ Radar1_Obj29_dySigma : 45|6@0+ (0.0625,0) [0|3.9375] "m" Vector__XXX
 SG_ Radar1_Obj29_dLength : 13|6@0+ (0.125,0) [0|7.875] "m" Vector__XXX
 SG_ Radar1_Obj29_class : 50|3@0+ (1,0) [0|7] "" Vector__XXX
 SG_ Radar1_Obj29_dz : 23|6@0+ (0.25,-5) [-5|10.75] "m" Vector__XXX
 SG_ Radar1_Obj29_movingState : 17|2@0+ (1,0) [0|3] "" Vector__XXX
 SG_ Radar1_Obj29_vy : 7|10@0+ (0.125,-64) [-64|63.875] "m/s" Vector__XXX
 SG_ Radar1_Obj29_vxSigma : 25|6@0+ (0.0625,0) [0|3.9375] "m/s" Vector__XXX
 SG_ Radar1_Obj29_dxSigma : 31|6@0+ (0.0625,0) [0|3.9375] "m" Vector__XXX
 SG_ Radar1_Obj29_axSigma : 35|6@0+ (0.0625,0) [0|3.9375] "m/s2" Vector__XXX
 SG_ Radar1_Obj29_MessBconsistBit : 56|1@0+ (1,0) [0|1] "" Vector__XXX

BO_ 1585 Radar1_Obj30_A: 8 Bosch_Radar1
 SG_ Radar1_Obj30_wObstacle : 53|5@0+ (0.03125,0) [0|0.96875] "" Vector__XXX
 SG_ Radar1_Obj30_wNonObstacle : 63|5@0+ (0.03125,0) [0|0.96875] "" Vector__XXX
 SG_ Radar1_Obj30_wExist : 36|5@0+ (0.03125,0) [0|0.96875] "-" Vector__XXX
 SG_ Radar1_Obj30_ax : 47|10@0+ (0.03125,-16) [-16|15.96875] "m/s2" Vector__XXX
 SG_ Radar1_Obj30_vx : 11|12@0+ (0.0625,-128) [-128|127.9375] "m/s" Vector__XXX
 SG_ Radar1_Obj30_dy : 31|11@0+ (0.125,-128) [-128|127.875] "m" Vector__XXX
 SG_ Radar1_Obj30_dx : 7|12@0+ (0.0625,-128) [-128|127.9375] "m" Vector__XXX
 SG_ Radar1_Obj30_flagValid : 48|1@0+ (1,0) [0|1] "" Vector__XXX
 SG_ Radar1_Obj30_flagHist : 57|1@0+ (1,0) [0|1] "" Vector__XXX
 SG_ Radar1_Obj30_flagMeas : 58|1@0+ (1,0) [0|1] "" Vector__XXX
 SG_ Radar1_Obj30_MessAconsistBit : 56|1@0+ (1,0) [0|1] "" Vector__XXX

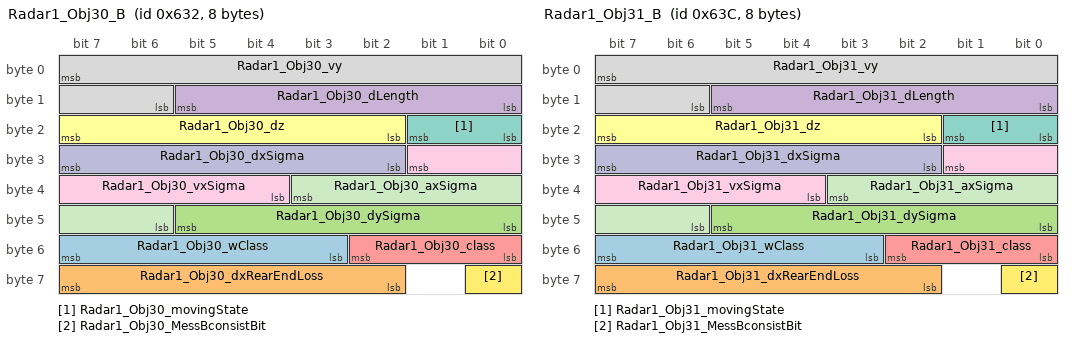
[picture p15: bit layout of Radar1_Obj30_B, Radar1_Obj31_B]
BO_ 1586 Radar1_Obj30_B: 8 Bosch_Radar1
 SG_ Radar1_Obj30_wClass : 55|5@0+ (0.03125,0) [0|0.96875] "" Vector__XXX
 SG_ Radar1_Obj30_dxRearEndLoss : 63|6@0+ (0.125,0) [0|7.875] "m" Vector__XXX
 SG_ Radar1_Obj30_dySigma : 45|6@0+ (0.0625,0) [0|3.9375] "m" Vector__XXX
 SG_ Radar1_Obj30_dLength : 13|6@0+ (0.125,0) [0|7.875] "m" Vector__XXX
 SG_ Radar1_Obj30_class : 50|3@0+ (1,0) [0|7] "" Vector__XXX
 SG_ Radar1_Obj30_dz : 23|6@0+ (0.25,-5) [-5|10.75] "m" Vector__XXX
 SG_ Radar1_Obj30_movingState : 17|2@0+ (1,0) [0|3] "" Vector__XXX
 SG_ Radar1_Obj30_vy : 7|10@0+ (0.125,-64) [-64|63.875] "m/s" Vector__XXX
 SG_ Radar1_Obj30_vxSigma : 25|6@0+ (0.0625,0) [0|3.9375] "m/s" Vector__XXX
 SG_ Radar1_Obj30_dxSigma : 31|6@0+ (0.0625,0) [0|3.9375] "m" Vector__XXX
 SG_ Radar1_Obj30_axSigma : 35|6@0+ (0.0625,0) [0|3.9375] "m/s2" Vector__XXX
 SG_ Radar1_Obj30_MessBconsistBit : 56|1@0+ (1,0) [0|1] "" Vector__XXX

BO_ 1595 Radar1_Obj31_A: 8 Bosch_Radar1
 SG_ Radar1_Obj31_wObstacle : 53|5@0+ (0.03125,0) [0|0.96875] "" Vector__XXX
 SG_ Radar1_Obj31_wNonObstacle : 63|5@0+ (0.03125,0) [0|0.96875] "" Vector__XXX
 SG_ Radar1_Obj31_wExist : 36|5@0+ (0.03125,0) [0|0.96875] "-" Vector__XXX
 SG_ Radar1_Obj31_ax : 47|10@0+ (0.03125,-16) [-16|15.96875] "m/s2" Vector__XXX
 SG_ Radar1_Obj31_vx : 11|12@0+ (0.0625,-128) [-128|127.9375] "m/s" Vector__XXX
 SG_ Radar1_Obj31_dy : 31|11@0+ (0.125,-128) [-128|127.875] "m" Vector__XXX
 SG_ Radar1_Obj31_dx : 7|12@0+ (0.0625,-128) [-128|127.9375] "m" Vector__XXX
 SG_ Radar1_Obj31_flagValid : 48|1@0+ (1,0) [0|1] "" Vector__XXX
 SG_ Radar1_Obj31_flagHist : 57|1@0+ (1,0) [0|1] "" Vector__XXX
 SG_ Radar1_Obj31_flagMeas : 58|1@0+ (1,0) [0|1] "" Vector__XXX
 SG_ Radar1_Obj31_MessAconsistBit : 56|1@0+ (1,0) [0|1] "" Vector__XXX

BO_ 1596 Radar1_Obj31_B: 8 Bosch_Radar1
 SG_ Radar1_Obj31_wClass : 55|5@0+ (0.03125,0) [0|0.96875] "" Vector__XXX
 SG_ Radar1_Obj31_dxRearEndLoss : 63|6@0+ (0.125,0) [0|7.875] "m" Vector__XXX
 SG_ Radar1_Obj31_dySigma : 45|6@0+ (0.0625,0) [0|3.9375] "m" Vector__XXX
 SG_ Radar1_Obj31_dLength : 13|6@0+ (0.125,0) [0|7.875] "m" Vector__XXX
 SG_ Radar1_Obj31_class : 50|3@0+ (1,0) [0|7] "" Vector__XXX
 SG_ Radar1_Obj31_dz : 23|6@0+ (0.25,-5) [-5|10.75] "m" Vector__XXX
 SG_ Radar1_Obj31_movingState : 17|2@0+ (1,0) [0|3] "" Vector__XXX
 SG_ Radar1_Obj31_vy : 7|10@0+ (0.125,-64) [-64|63.875] "m/s" Vector__XXX
 SG_ Radar1_Obj31_vxSigma : 25|6@0+ (0.0625,0) [0|3.9375] "m/s" Vector__XXX
 SG_ Radar1_Obj31_dxSigma : 31|6@0+ (0.0625,0) [0|3.9375] "m" Vector__XXX
 SG_ Radar1_Obj31_axSigma : 35|6@0+ (0.0625,0) [0|3.9375] "m/s2" Vector__XXX
 SG_ Radar1_Obj31_MessBconsistBit : 56|1@0+ (1,0) [0|1] "" Vector__XXX

BO_ 1605 Radar1_Target00_A: 8 Bosch_Radar1
 SG_ Radar1_Target00_wObstacle : 53|5@0+ (0.03125,0) [0|0.96875] "" Vector__XXX
 SG_ Radar1_Target00_wNonObstacle : 63|5@0+ (0.03125,0) [0|0.96875] "" Vector__XXX
 SG_ Radar1_Target00_wExist : 36|5@0+ (0.03125,0) [0|0.96875] "-" Vector__XXX
 SG_ Radar1_Target00_ax : 47|10@0+ (0.03125,-16) [-16|15.96875] "m/s2" Vector__XXX
 SG_ Radar1_Target00_vx : 11|12@0+ (0.0625,-128) [-128|127.9375] "m/s" Vector__XXX
 SG_ Radar1_Target00_dy : 31|11@0+ (0.125,-128) [-128|127.875] "m" Vector__XXX
 SG_ Radar1_Target00_dx : 7|12@0+ (0.0625,-128) [-128|127.9375] "m" Vector__XXX
 SG_ Radar1_Target00_flagValid : 48|1@0+ (1,0) [0|1] "" Vector__XXX
 SG_ Radar1_Target00_flagHist : 57|1@0+ (1,0) [0|1] "" Vector__XXX
 SG_ Radar1_Target00_flagMeas : 58|1@0+ (1,0) [0|1] "" Vector__XXX
 SG_ Radar1_Target00_MessAconsistBit : 56|1@0+ (1,0) [0|1] "" Vector__XXX

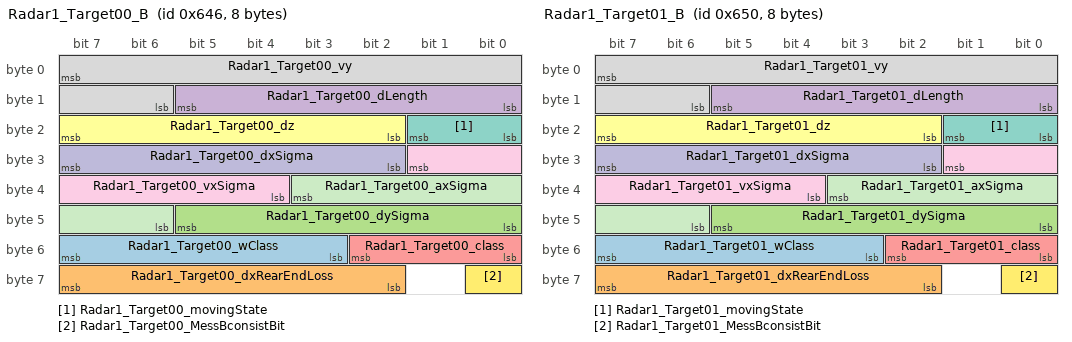
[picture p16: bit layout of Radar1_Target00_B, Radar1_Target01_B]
BO_ 1606 Radar1_Target00_B: 8 Bosch_Radar1
 SG_ Radar1_Target00_wClass : 55|5@0+ (0.03125,0) [0|0.96875] "" Vector__XXX
 SG_ Radar1_Target00_dxRearEndLoss : 63|6@0+ (0.125,0) [0|7.875] "m" Vector__XXX
 SG_ Radar1_Target00_dySigma : 45|6@0+ (0.0625,0) [0|3.9375] "m" Vector__XXX
 SG_ Radar1_Target00_dLength : 13|6@0+ (0.125,0) [0|7.875] "m" Vector__XXX
 SG_ Radar1_Target00_class : 50|3@0+ (1,0) [0|7] "" Vector__XXX
 SG_ Radar1_Target00_dz : 23|6@0+ (0.25,-5) [-5|10.75] "m" Vector__XXX
 SG_ Radar1_Target00_movingState : 17|2@0+ (1,0) [0|3] "" Vector__XXX
 SG_ Radar1_Target00_vy : 7|10@0+ (0.125,-64) [-64|63.875] "m/s" Vector__XXX
 SG_ Radar1_Target00_vxSigma : 25|6@0+ (0.0625,0) [0|3.9375] "m/s" Vector__XXX
 SG_ Radar1_Target00_dxSigma : 31|6@0+ (0.0625,0) [0|3.9375] "m" Vector__XXX
 SG_ Radar1_Target00_axSigma : 35|6@0+ (0.0625,0) [0|3.9375] "m/s2" Vector__XXX
 SG_ Radar1_Target00_MessBconsistBit : 56|1@0+ (1,0) [0|1] "" Vector__XXX

BO_ 1615 Radar1_Target01_A: 8 Bosch_Radar1
 SG_ Radar1_Target01_wObstacle : 53|5@0+ (0.03125,0) [0|0.96875] "" Vector__XXX
 SG_ Radar1_Target01_wNonObstacle : 63|5@0+ (0.03125,0) [0|0.96875] "" Vector__XXX
 SG_ Radar1_Target01_wExist : 36|5@0+ (0.03125,0) [0|0.96875] "-" Vector__XXX
 SG_ Radar1_Target01_ax : 47|10@0+ (0.03125,-16) [-16|15.96875] "m/s2" Vector__XXX
 SG_ Radar1_Target01_vx : 11|12@0+ (0.0625,-128) [-128|127.9375] "m/s" Vector__XXX
 SG_ Radar1_Target01_dy : 31|11@0+ (0.125,-128) [-128|127.875] "m" Vector__XXX
 SG_ Radar1_Target01_dx : 7|12@0+ (0.0625,-128) [-128|127.9375] "m" Vector__XXX
 SG_ Radar1_Target01_flagValid : 48|1@0+ (1,0) [0|1] "" Vector__XXX
 SG_ Radar1_Target01_flagHist : 57|1@0+ (1,0) [0|1] "" Vector__XXX
 SG_ Radar1_Target01_flagMeas : 58|1@0+ (1,0) [0|1] "" Vector__XXX
 SG_ Radar1_Target01_MessAconsistBit : 56|1@0+ (1,0) [0|1] "" Vector__XXX

BO_ 1616 Radar1_Target01_B: 8 Bosch_Radar1
 SG_ Radar1_Target01_wClass : 55|5@0+ (0.03125,0) [0|0.96875] "" Vector__XXX
 SG_ Radar1_Target01_dxRearEndLoss : 63|6@0+ (0.125,0) [0|7.875] "m" Vector__XXX
 SG_ Radar1_Target01_dySigma : 45|6@0+ (0.0625,0) [0|3.9375] "m" Vector__XXX
 SG_ Radar1_Target01_dLength : 13|6@0+ (0.125,0) [0|7.875] "m" Vector__XXX
 SG_ Radar1_Target01_class : 50|3@0+ (1,0) [0|7] "" Vector__XXX
 SG_ Radar1_Target01_dz : 23|6@0+ (0.25,-5) [-5|10.75] "m" Vector__XXX
 SG_ Radar1_Target01_movingState : 17|2@0+ (1,0) [0|3] "" Vector__XXX
 SG_ Radar1_Target01_vy : 7|10@0+ (0.125,-64) [-64|63.875] "m/s" Vector__XXX
 SG_ Radar1_Target01_vxSigma : 25|6@0+ (0.0625,0) [0|3.9375] "m/s" Vector__XXX
 SG_ Radar1_Target01_dxSigma : 31|6@0+ (0.0625,0) [0|3.9375] "m" Vector__XXX
 SG_ Radar1_Target01_axSigma : 35|6@0+ (0.0625,0) [0|3.9375] "m/s2" Vector__XXX
 SG_ Radar1_Target01_MessBconsistBit : 56|1@0+ (1,0) [0|1] "" Vector__XXX

BO_ 1625 Radar1_Target02_A: 8 Bosch_Radar1
 SG_ Radar1_Target02_wObstacle : 53|5@0+ (0.03125,0) [0|0.96875] "" Vector__XXX
 SG_ Radar1_Target02_wNonObstacle : 63|5@0+ (0.03125,0) [0|0.96875] "" Vector__XXX
 SG_ Radar1_Target02_wExist : 36|5@0+ (0.03125,0) [0|0.96875] "-" Vector__XXX
 SG_ Radar1_Target02_ax : 47|10@0+ (0.03125,-16) [-16|15.96875] "m/s2" Vector__XXX
 SG_ Radar1_Target02_vx : 11|12@0+ (0.0625,-128) [-128|127.9375] "m/s" Vector__XXX
 SG_ Radar1_Target02_dy : 31|11@0+ (0.125,-128) [-128|127.875] "m" Vector__XXX
 SG_ Radar1_Target02_dx : 7|12@0+ (0.0625,-128) [-128|127.9375] "m" Vector__XXX
 SG_ Radar1_Target02_flagValid : 48|1@0+ (1,0) [0|1] "" Vector__XXX
 SG_ Radar1_Target02_flagHist : 57|1@0+ (1,0) [0|1] "" Vector__XXX
 SG_ Radar1_Target02_flagMeas : 58|1@0+ (1,0) [0|1] "" Vector__XXX
 SG_ Radar1_Target02_MessAconsistBit : 56|1@0+ (1,0) [0|1] "" Vector__XXX

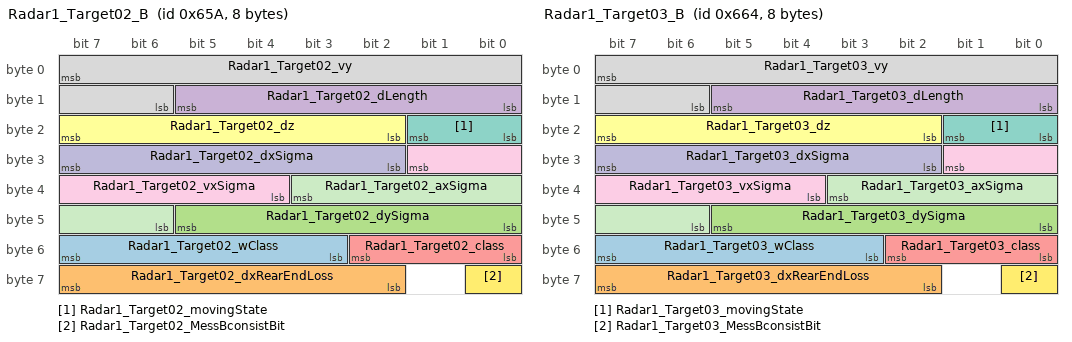
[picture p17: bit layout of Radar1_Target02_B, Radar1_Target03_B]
BO_ 1626 Radar1_Target02_B: 8 Bosch_Radar1
 SG_ Radar1_Target02_wClass : 55|5@0+ (0.03125,0) [0|0.96875] "" Vector__XXX
 SG_ Radar1_Target02_dxRearEndLoss : 63|6@0+ (0.125,0) [0|7.875] "m" Vector__XXX
 SG_ Radar1_Target02_dySigma : 45|6@0+ (0.0625,0) [0|3.9375] "m" Vector__XXX
 SG_ Radar1_Target02_dLength : 13|6@0+ (0.125,0) [0|7.875] "m" Vector__XXX
 SG_ Radar1_Target02_class : 50|3@0+ (1,0) [0|7] "" Vector__XXX
 SG_ Radar1_Target02_dz : 23|6@0+ (0.25,-5) [-5|10.75] "m" Vector__XXX
 SG_ Radar1_Target02_movingState : 17|2@0+ (1,0) [0|3] "" Vector__XXX
 SG_ Radar1_Target02_vy : 7|10@0+ (0.125,-64) [-64|63.875] "m/s" Vector__XXX
 SG_ Radar1_Target02_vxSigma : 25|6@0+ (0.0625,0) [0|3.9375] "m/s" Vector__XXX
 SG_ Radar1_Target02_dxSigma : 31|6@0+ (0.0625,0) [0|3.9375] "m" Vector__XXX
 SG_ Radar1_Target02_axSigma : 35|6@0+ (0.0625,0) [0|3.9375] "m/s2" Vector__XXX
 SG_ Radar1_Target02_MessBconsistBit : 56|1@0+ (1,0) [0|1] "" Vector__XXX

BO_ 1635 Radar1_Target03_A: 8 Bosch_Radar1
 SG_ Radar1_Target03_wObstacle : 53|5@0+ (0.03125,0) [0|0.96875] "" Vector__XXX
 SG_ Radar1_Target03_wNonObstacle : 63|5@0+ (0.03125,0) [0|0.96875] "" Vector__XXX
 SG_ Radar1_Target03_wExist : 36|5@0+ (0.03125,0) [0|0.96875] "-" Vector__XXX
 SG_ Radar1_Target03_ax : 47|10@0+ (0.03125,-16) [-16|15.96875] "m/s2" Vector__XXX
 SG_ Radar1_Target03_vx : 11|12@0+ (0.0625,-128) [-128|127.9375] "m/s" Vector__XXX
 SG_ Radar1_Target03_dy : 31|11@0+ (0.125,-128) [-128|127.875] "m" Vector__XXX
 SG_ Radar1_Target03_dx : 7|12@0+ (0.0625,-128) [-128|127.9375] "m" Vector__XXX
 SG_ Radar1_Target03_flagValid : 48|1@0+ (1,0) [0|1] "" Vector__XXX
 SG_ Radar1_Target03_flagHist : 57|1@0+ (1,0) [0|1] "" Vector__XXX
 SG_ Radar1_Target03_flagMeas : 58|1@0+ (1,0) [0|1] "" Vector__XXX
 SG_ Radar1_Target03_MessAconsistBit : 56|1@0+ (1,0) [0|1] "" Vector__XXX

BO_ 1636 Radar1_Target03_B: 8 Bosch_Radar1
 SG_ Radar1_Target03_wClass : 55|5@0+ (0.03125,0) [0|0.96875] "" Vector__XXX
 SG_ Radar1_Target03_dxRearEndLoss : 63|6@0+ (0.125,0) [0|7.875] "m" Vector__XXX
 SG_ Radar1_Target03_dySigma : 45|6@0+ (0.0625,0) [0|3.9375] "m" Vector__XXX
 SG_ Radar1_Target03_dLength : 13|6@0+ (0.125,0) [0|7.875] "m" Vector__XXX
 SG_ Radar1_Target03_class : 50|3@0+ (1,0) [0|7] "" Vector__XXX
 SG_ Radar1_Target03_dz : 23|6@0+ (0.25,-5) [-5|10.75] "m" Vector__XXX
 SG_ Radar1_Target03_movingState : 17|2@0+ (1,0) [0|3] "" Vector__XXX
 SG_ Radar1_Target03_vy : 7|10@0+ (0.125,-64) [-64|63.875] "m/s" Vector__XXX
 SG_ Radar1_Target03_vxSigma : 25|6@0+ (0.0625,0) [0|3.9375] "m/s" Vector__XXX
 SG_ Radar1_Target03_dxSigma : 31|6@0+ (0.0625,0) [0|3.9375] "m" Vector__XXX
 SG_ Radar1_Target03_axSigma : 35|6@0+ (0.0625,0) [0|3.9375] "m/s2" Vector__XXX
 SG_ Radar1_Target03_MessBconsistBit : 56|1@0+ (1,0) [0|1] "" Vector__XXX

BO_ 1645 Radar1_Target04_A: 8 Bosch_Radar1
 SG_ Radar1_Target04_wObstacle : 53|5@0+ (0.03125,0) [0|0.96875] "" Vector__XXX
 SG_ Radar1_Target04_wNonObstacle : 63|5@0+ (0.03125,0) [0|0.96875] "" Vector__XXX
 SG_ Radar1_Target04_wExist : 36|5@0+ (0.03125,0) [0|0.96875] "-" Vector__XXX
 SG_ Radar1_Target04_ax : 47|10@0+ (0.03125,-16) [-16|15.96875] "m/s2" Vector__XXX
 SG_ Radar1_Target04_vx : 11|12@0+ (0.0625,-128) [-128|127.9375] "m/s" Vector__XXX
 SG_ Radar1_Target04_dy : 31|11@0+ (0.125,-128) [-128|127.875] "m" Vector__XXX
 SG_ Radar1_Target04_dx : 7|12@0+ (0.0625,-128) [-128|127.9375] "m" Vector__XXX
 SG_ Radar1_Target04_flagValid : 48|1@0+ (1,0) [0|1] "" Vector__XXX
 SG_ Radar1_Target04_flagHist : 57|1@0+ (1,0) [0|1] "" Vector__XXX
 SG_ Radar1_Target04_flagMeas : 58|1@0+ (1,0) [0|1] "" Vector__XXX
 SG_ Radar1_Target04_MessAconsistBit : 56|1@0+ (1,0) [0|1] "" Vector__XXX

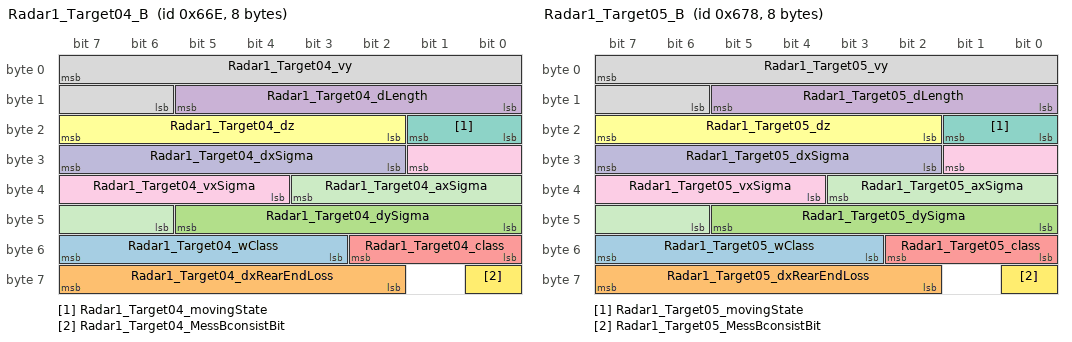
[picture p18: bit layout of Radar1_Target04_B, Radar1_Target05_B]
BO_ 1646 Radar1_Target04_B: 8 Bosch_Radar1
 SG_ Radar1_Target04_wClass : 55|5@0+ (0.03125,0) [0|0.96875] "" Vector__XXX
 SG_ Radar1_Target04_dxRearEndLoss : 63|6@0+ (0.125,0) [0|7.875] "m" Vector__XXX
 SG_ Radar1_Target04_dySigma : 45|6@0+ (0.0625,0) [0|3.9375] "m" Vector__XXX
 SG_ Radar1_Target04_dLength : 13|6@0+ (0.125,0) [0|7.875] "m" Vector__XXX
 SG_ Radar1_Target04_class : 50|3@0+ (1,0) [0|7] "" Vector__XXX
 SG_ Radar1_Target04_dz : 23|6@0+ (0.25,-5) [-5|10.75] "m" Vector__XXX
 SG_ Radar1_Target04_movingState : 17|2@0+ (1,0) [0|3] "" Vector__XXX
 SG_ Radar1_Target04_vy : 7|10@0+ (0.125,-64) [-64|63.875] "m/s" Vector__XXX
 SG_ Radar1_Target04_vxSigma : 25|6@0+ (0.0625,0) [0|3.9375] "m/s" Vector__XXX
 SG_ Radar1_Target04_dxSigma : 31|6@0+ (0.0625,0) [0|3.9375] "m" Vector__XXX
 SG_ Radar1_Target04_axSigma : 35|6@0+ (0.0625,0) [0|3.9375] "m/s2" Vector__XXX
 SG_ Radar1_Target04_MessBconsistBit : 56|1@0+ (1,0) [0|1] "" Vector__XXX

BO_ 1655 Radar1_Target05_A: 8 Bosch_Radar1
 SG_ Radar1_Target05_wObstacle : 53|5@0+ (0.03125,0) [0|0.96875] "" Vector__XXX
 SG_ Radar1_Target05_wNonObstacle : 63|5@0+ (0.03125,0) [0|0.96875] "" Vector__XXX
 SG_ Radar1_Target05_wExist : 36|5@0+ (0.03125,0) [0|0.96875] "-" Vector__XXX
 SG_ Radar1_Target05_ax : 47|10@0+ (0.03125,-16) [-16|15.96875] "m/s2" Vector__XXX
 SG_ Radar1_Target05_vx : 11|12@0+ (0.0625,-128) [-128|127.9375] "m/s" Vector__XXX
 SG_ Radar1_Target05_dy : 31|11@0+ (0.125,-128) [-128|127.875] "m" Vector__XXX
 SG_ Radar1_Target05_dx : 7|12@0+ (0.0625,-128) [-128|127.9375] "m" Vector__XXX
 SG_ Radar1_Target05_flagValid : 48|1@0+ (1,0) [0|1] "" Vector__XXX
 SG_ Radar1_Target05_flagHist : 57|1@0+ (1,0) [0|1] "" Vector__XXX
 SG_ Radar1_Target05_flagMeas : 58|1@0+ (1,0) [0|1] "" Vector__XXX
 SG_ Radar1_Target05_MessAconsistBit : 56|1@0+ (1,0) [0|1] "" Vector__XXX

BO_ 1656 Radar1_Target05_B: 8 Bosch_Radar1
 SG_ Radar1_Target05_wClass : 55|5@0+ (0.03125,0) [0|0.96875] "" Vector__XXX
 SG_ Radar1_Target05_dxRearEndLoss : 63|6@0+ (0.125,0) [0|7.875] "m" Vector__XXX
 SG_ Radar1_Target05_dySigma : 45|6@0+ (0.0625,0) [0|3.9375] "m" Vector__XXX
 SG_ Radar1_Target05_dLength : 13|6@0+ (0.125,0) [0|7.875] "m" Vector__XXX
 SG_ Radar1_Target05_class : 50|3@0+ (1,0) [0|7] "" Vector__XXX
 SG_ Radar1_Target05_dz : 23|6@0+ (0.25,-5) [-5|10.75] "m" Vector__XXX
 SG_ Radar1_Target05_movingState : 17|2@0+ (1,0) [0|3] "" Vector__XXX
 SG_ Radar1_Target05_vy : 7|10@0+ (0.125,-64) [-64|63.875] "m/s" Vector__XXX
 SG_ Radar1_Target05_vxSigma : 25|6@0+ (0.0625,0) [0|3.9375] "m/s" Vector__XXX
 SG_ Radar1_Target05_dxSigma : 31|6@0+ (0.0625,0) [0|3.9375] "m" Vector__XXX
 SG_ Radar1_Target05_axSigma : 35|6@0+ (0.0625,0) [0|3.9375] "m/s2" Vector__XXX
 SG_ Radar1_Target05_MessBconsistBit : 56|1@0+ (1,0) [0|1] "" Vector__XXX

BO_ 1665 Radar1_Object_Ender: 8 Bosch_Radar1
 SG_ Radar1_PacketChecksum : 63|8@0+ (1,0) [0|0] "" Vector__XXX
 SG_ Radar1_timestamp : 7|8@0+ (0.0009765625,0) [0|0.2490234375] "s" Vector__XXX
 SG_ Radar1_MessEnderConsistBit : 48|1@0+ (1,0) [0|1] "" Vector__XXX
 SG_ Radar1_TCCounter : 31|8@0+ (1,0) [0|0] "" Vector__XXX

BO_ 1280 Radar1_Object_Starter: 8 Bosch_Radar1
 SG_ Radar1_Veh_vEgo : 23|12@0+ (0.0625,-128) [-128|127.9375] "m/s" Vector__XXX
 SG_ Radar1_Veh_aEgo : 27|10@0+ (0.03125,-16) [-16|15.96875] "m/s²" Vector__XXX
 SG_ Radar1_Veh_slipAngle : 45|14@0+ (6.103515625E-005,-0.5) [-0.5|0.49993896484375] "Rad" Vector__XXX
 SG_ Radar1_Veh_psiDt : 7|16@0+ (6.103515625E-005,-2) [-2|1.99993896484375] "rad/s" Vector__XXX
 SG_ Radar1_MessStarterConsistBit : 56|1@0+ (1,0) [0|1] "" Vector__XXX

BO_ 1670 Radar1_Status: 8 BoschRadar1
 SG_ R1_Stat_HWFail : 20|1@0+ (1,0) [0|1] "" Vector__XXX
 SG_ R1_Stat_SGUFail : 21|1@0+ (1,0) [0|1] "" Vector__XXX
 SG_ R1_Stat_AbsorptionBlindness : 39|8@0+ (0.00390625,0) [0|0.99609375] "" Vector__XXX
 SG_ R1_Stat_DistortionBlindness : 47|8@0+ (0.00390625,0) [0|0.99609375] "" Vector__XXX
 SG_ R1_Stat_ITCInfo : 7|16@0+ (1,0) [0|65535] "" Vector__XXX
 SG_ R1_Stat_HorizontalMisalignment : 19|12@0+ (0.0001,-0.2048) [-0.2048|0.2047] "rad" Vector__XXX
 SG_ R1_Stat_MC : 51|4@0+ (1,0) [0|15] "" Vector__XXX
 SG_ R1_Stat_CRC : 63|8@0+ (1,0) [0|255] "" Vector__XXX

BO_ 1287 Radar2_Obj00_A: 8 Bosch_Radar2
 SG_ Radar2_Obj00_wObstacle : 53|5@0+ (0.03125,0) [0|0.96875] "" Vector__XXX
 SG_ Radar2_Obj00_wNonObstacle : 63|5@0+ (0.03125,0) [0|0.96875] "" Vector__XXX
 SG_ Radar2_Obj00_wExist : 36|5@0+ (0.03125,0) [0|0.96875] "-" Vector__XXX
 SG_ Radar2_Obj00_ax : 47|10@0+ (0.03125,-16) [-16|15.96875] "m/s2" Vector__XXX
 SG_ Radar2_Obj00_vx : 11|12@0+ (0.0625,-128) [-128|127.9375] "m/s" Vector__XXX
 SG_ Radar2_Obj00_dy : 31|11@0+ (0.125,-128) [-128|127.875] "m" Vector__XXX
 SG_ Radar2_Obj00_dx : 7|12@0+ (0.0625,-128) [-128|127.9375] "m" Vector__XXX
 SG_ Radar2_Obj00_flagValid : 48|1@0+ (1,0) [0|1] "" Vector__XXX
 SG_ Radar2_Obj00_flagHist : 57|1@0+ (1,0) [0|1] "" Vector__XXX
 SG_ Radar2_Obj00_flagMeas : 58|1@0+ (1,0) [0|1] "" Vector__XXX
 SG_ Radar2_Obj00_MessAconsistBit : 56|1@0+ (1,0) [0|1] "" Vector__XXX

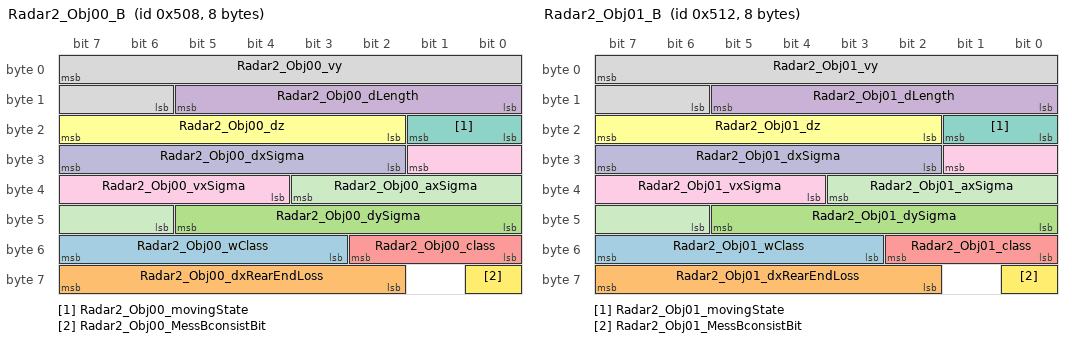
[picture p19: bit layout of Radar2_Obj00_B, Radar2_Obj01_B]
BO_ 1288 Radar2_Obj00_B: 8 Bosch_Radar2
 SG_ Radar2_Obj00_wClass : 55|5@0+ (0.03125,0) [0|0.96875] "" Vector__XXX
 SG_ Radar2_Obj00_dxRearEndLoss : 63|6@0+ (0.125,0) [0|7.875] "m" Vector__XXX
 SG_ Radar2_Obj00_dySigma : 45|6@0+ (0.0625,0) [0|3.9375] "m" Vector__XXX
 SG_ Radar2_Obj00_dLength : 13|6@0+ (0.125,0) [0|7.875] "m" Vector__XXX
 SG_ Radar2_Obj00_class : 50|3@0+ (1,0) [0|7] "" Vector__XXX
 SG_ Radar2_Obj00_dz : 23|6@0+ (0.25,-5) [-5|10.75] "m" Vector__XXX
 SG_ Radar2_Obj00_movingState : 17|2@0+ (1,0) [0|3] "" Vector__XXX
 SG_ Radar2_Obj00_vy : 7|10@0+ (0.125,-64) [-64|63.875] "m/s" Vector__XXX
 SG_ Radar2_Obj00_vxSigma : 25|6@0+ (0.0625,0) [0|3.9375] "m/s" Vector__XXX
 SG_ Radar2_Obj00_dxSigma : 31|6@0+ (0.0625,0) [0|3.9375] "m" Vector__XXX
 SG_ Radar2_Obj00_axSigma : 35|6@0+ (0.0625,0) [0|3.9375] "m/s2" Vector__XXX
 SG_ Radar2_Obj00_MessBconsistBit : 56|1@0+ (1,0) [0|1] "" Vector__XXX

BO_ 1297 Radar2_Obj01_A: 8 Bosch_Radar2
 SG_ Radar2_Obj01_wObstacle : 53|5@0+ (0.03125,0) [0|0.96875] "" Vector__XXX
 SG_ Radar2_Obj01_wNonObstacle : 63|5@0+ (0.03125,0) [0|0.96875] "" Vector__XXX
 SG_ Radar2_Obj01_wExist : 36|5@0+ (0.03125,0) [0|0.96875] "-" Vector__XXX
 SG_ Radar2_Obj01_ax : 47|10@0+ (0.03125,-16) [-16|15.96875] "m/s2" Vector__XXX
 SG_ Radar2_Obj01_vx : 11|12@0+ (0.0625,-128) [-128|127.9375] "m/s" Vector__XXX
 SG_ Radar2_Obj01_dy : 31|11@0+ (0.125,-128) [-128|127.875] "m" Vector__XXX
 SG_ Radar2_Obj01_dx : 7|12@0+ (0.0625,-128) [-128|127.9375] "m" Vector__XXX
 SG_ Radar2_Obj01_flagValid : 48|1@0+ (1,0) [0|1] "" Vector__XXX
 SG_ Radar2_Obj01_flagHist : 57|1@0+ (1,0) [0|1] "" Vector__XXX
 SG_ Radar2_Obj01_flagMeas : 58|1@0+ (1,0) [0|1] "" Vector__XXX
 SG_ Radar2_Obj01_MessAconsistBit : 56|1@0+ (1,0) [0|1] "" Vector__XXX

BO_ 1298 Radar2_Obj01_B: 8 Bosch_Radar2
 SG_ Radar2_Obj01_wClass : 55|5@0+ (0.03125,0) [0|0.96875] "" Vector__XXX
 SG_ Radar2_Obj01_dxRearEndLoss : 63|6@0+ (0.125,0) [0|7.875] "m" Vector__XXX
 SG_ Radar2_Obj01_dySigma : 45|6@0+ (0.0625,0) [0|3.9375] "m" Vector__XXX
 SG_ Radar2_Obj01_dLength : 13|6@0+ (0.125,0) [0|7.875] "m" Vector__XXX
 SG_ Radar2_Obj01_class : 50|3@0+ (1,0) [0|7] "" Vector__XXX
 SG_ Radar2_Obj01_dz : 23|6@0+ (0.25,-5) [-5|10.75] "m" Vector__XXX
 SG_ Radar2_Obj01_movingState : 17|2@0+ (1,0) [0|3] "" Vector__XXX
 SG_ Radar2_Obj01_vy : 7|10@0+ (0.125,-64) [-64|63.875] "m/s" Vector__XXX
 SG_ Radar2_Obj01_vxSigma : 25|6@0+ (0.0625,0) [0|3.9375] "m/s" Vector__XXX
 SG_ Radar2_Obj01_dxSigma : 31|6@0+ (0.0625,0) [0|3.9375] "m" Vector__XXX
 SG_ Radar2_Obj01_axSigma : 35|6@0+ (0.0625,0) [0|3.9375] "m/s2" Vector__XXX
 SG_ Radar2_Obj01_MessBconsistBit : 56|1@0+ (1,0) [0|1] "" Vector__XXX

BO_ 1307 Radar2_Obj02_A: 8 Bosch_Radar2
 SG_ Radar2_Obj02_wObstacle : 53|5@0+ (0.03125,0) [0|0.96875] "" Vector__XXX
 SG_ Radar2_Obj02_wNonObstacle : 63|5@0+ (0.03125,0) [0|0.96875] "" Vector__XXX
 SG_ Radar2_Obj02_wExist : 36|5@0+ (0.03125,0) [0|0.96875] "-" Vector__XXX
 SG_ Radar2_Obj02_ax : 47|10@0+ (0.03125,-16) [-16|15.96875] "m/s2" Vector__XXX
 SG_ Radar2_Obj02_vx : 11|12@0+ (0.0625,-128) [-128|127.9375] "m/s" Vector__XXX
 SG_ Radar2_Obj02_dy : 31|11@0+ (0.125,-128) [-128|127.875] "m" Vector__XXX
 SG_ Radar2_Obj02_dx : 7|12@0+ (0.0625,-128) [-128|127.9375] "m" Vector__XXX
 SG_ Radar2_Obj02_flagValid : 48|1@0+ (1,0) [0|1] "" Vector__XXX
 SG_ Radar2_Obj02_flagHist : 57|1@0+ (1,0) [0|1] "" Vector__XXX
 SG_ Radar2_Obj02_flagMeas : 58|1@0+ (1,0) [0|1] "" Vector__XXX
 SG_ Radar2_Obj02_MessAconsistBit : 56|1@0+ (1,0) [0|1] "" Vector__XXX

BO_ 1308 Radar2_Obj02_B: 8 Bosch_Radar2
 SG_ Radar2_Obj02_wClass : 55|5@0+ (0.03125,0) [0|0.96875] "" Vector__XXX
 SG_ Radar2_Obj02_dxRearEndLoss : 63|6@0+ (0.125,0) [0|7.875] "m" Vector__XXX
 SG_ Radar2_Obj02_dySigma : 45|6@0+ (0.0625,0) [0|3.9375] "m" Vector__XXX
 SG_ Radar2_Obj02_dLength : 13|6@0+ (0.125,0) [0|7.875] "m" Vector__XXX
 SG_ Radar2_Obj02_class : 50|3@0+ (1,0) [0|7] "" Vector__XXX
 SG_ Radar2_Obj02_dz : 23|6@0+ (0.25,-5) [-5|10.75] "m" Vector__XXX
 SG_ Radar2_Obj02_movingState : 17|2@0+ (1,0) [0|3] "" Vector__XXX
 SG_ Radar2_Obj02_vy : 7|10@0+ (0.125,-64) [-64|63.875] "m/s" Vector__XXX
 SG_ Radar2_Obj02_vxSigma : 25|6@0+ (0.0625,0) [0|3.9375] "m/s" Vector__XXX
 SG_ Radar2_Obj02_dxSigma : 31|6@0+ (0.0625,0) [0|3.9375] "m" Vector__XXX
 SG_ Radar2_Obj02_axSigma : 35|6@0+ (0.0625,0) [0|3.9375] "m/s2" Vector__XXX
 SG_ Radar2_Obj02_MessBconsistBit : 56|1@0+ (1,0) [0|1] "" Vector__XXX

BO_ 1317 Radar2_Obj03_A: 8 Bosch_Radar2
 SG_ Radar2_Obj03_wObstacle : 53|5@0+ (0.03125,0) [0|0.96875] "" Vector__XXX
 SG_ Radar2_Obj03_wNonObstacle : 63|5@0+ (0.03125,0) [0|0.96875] "" Vector__XXX
 SG_ Radar2_Obj03_wExist : 36|5@0+ (0.03125,0) [0|0.96875] "-" Vector__XXX
 SG_ Radar2_Obj03_ax : 47|10@0+ (0.03125,-16) [-16|15.96875] "m/s2" Vector__XXX
 SG_ Radar2_Obj03_vx : 11|12@0+ (0.0625,-128) [-128|127.9375] "m/s" Vector__XXX
 SG_ Radar2_Obj03_dy : 31|11@0+ (0.125,-128) [-128|127.875] "m" Vector__XXX
 SG_ Radar2_Obj03_dx : 7|12@0+ (0.0625,-128) [-128|127.9375] "m" Vector__XXX
 SG_ Radar2_Obj03_flagValid : 48|1@0+ (1,0) [0|1] "" Vector__XXX
 SG_ Radar2_Obj03_flagHist : 57|1@0+ (1,0) [0|1] "" Vector__XXX
 SG_ Radar2_Obj03_flagMeas : 58|1@0+ (1,0) [0|1] "" Vector__XXX
 SG_ Radar2_Obj03_MessAconsistBit : 56|1@0+ (1,0) [0|1] "" Vector__XXX

BO_ 1318 Radar2_Obj03_B: 8 Bosch_Radar2
 SG_ Radar2_Obj03_wClass : 55|5@0+ (0.03125,0) [0|0.96875] "" Vector__XXX
 SG_ Radar2_Obj03_dxRearEndLoss : 63|6@0+ (0.125,0) [0|7.875] "m" Vector__XXX
 SG_ Radar2_Obj03_dySigma : 45|6@0+ (0.0625,0) [0|3.9375] "m" Vector__XXX
 SG_ Radar2_Obj03_dLength : 13|6@0+ (0.125,0) [0|7.875] "m" Vector__XXX
 SG_ Radar2_Obj03_class : 50|3@0+ (1,0) [0|7] "" Vector__XXX
 SG_ Radar2_Obj03_dz : 23|6@0+ (0.25,-5) [-5|10.75] "m" Vector__XXX
 SG_ Radar2_Obj03_movingState : 17|2@0+ (1,0) [0|3] "" Vector__XXX
 SG_ Radar2_Obj03_vy : 7|10@0+ (0.125,-64) [-64|63.875] "m/s" Vector__XXX
 SG_ Radar2_Obj03_vxSigma : 25|6@0+ (0.0625,0) [0|3.9375] "m/s" Vector__XXX
 SG_ Radar2_Obj03_dxSigma : 31|6@0+ (0.0625,0) [0|3.9375] "m" Vector__XXX
 SG_ Radar2_Obj03_axSigma : 35|6@0+ (0.0625,0) [0|3.9375] "m/s2" Vector__XXX
 SG_ Radar2_Obj03_MessBconsistBit : 56|1@0+ (1,0) [0|1] "" Vector__XXX

BO_ 1327 Radar2_Obj04_A: 8 Bosch_Radar2
 SG_ Radar2_Obj04_wObstacle : 53|5@0+ (0.03125,0) [0|0.96875] "" Vector__XXX
 SG_ Radar2_Obj04_wNonObstacle : 63|5@0+ (0.03125,0) [0|0.96875] "" Vector__XXX
 SG_ Radar2_Obj04_wExist : 36|5@0+ (0.03125,0) [0|0.96875] "-" Vector__XXX
 SG_ Radar2_Obj04_ax : 47|10@0+ (0.03125,-16) [-16|15.96875] "m/s2" Vector__XXX
 SG_ Radar2_Obj04_vx : 11|12@0+ (0.0625,-128) [-128|127.9375] "m/s" Vector__XXX
 SG_ Radar2_Obj04_dy : 31|11@0+ (0.125,-128) [-128|127.875] "m" Vector__XXX
 SG_ Radar2_Obj04_dx : 7|12@0+ (0.0625,-128) [-128|127.9375] "m" Vector__XXX
 SG_ Radar2_Obj04_flagValid : 48|1@0+ (1,0) [0|1] "" Vector__XXX
 SG_ Radar2_Obj04_flagHist : 57|1@0+ (1,0) [0|1] "" Vector__XXX
 SG_ Radar2_Obj04_flagMeas : 58|1@0+ (1,0) [0|1] "" Vector__XXX
 SG_ Radar2_Obj04_MessAconsistBit : 56|1@0+ (1,0) [0|1] "" Vector__XXX

BO_ 1328 Radar2_Obj04_B: 8 Bosch_Radar2
 SG_ Radar2_Obj04_wClass : 55|5@0+ (0.03125,0) [0|0.96875] "" Vector__XXX
 SG_ Radar2_Obj04_dxRearEndLoss : 63|6@0+ (0.125,0) [0|7.875] "m" Vector__XXX
 SG_ Radar2_Obj04_dySigma : 45|6@0+ (0.0625,0) [0|3.9375] "m" Vector__XXX
 SG_ Radar2_Obj04_dLength : 13|6@0+ (0.125,0) [0|7.875] "m" Vector__XXX
 SG_ Radar2_Obj04_class : 50|3@0+ (1,0) [0|7] "" Vector__XXX
 SG_ Radar2_Obj04_dz : 23|6@0+ (0.25,-5) [-5|10.75] "m" Vector__XXX
 SG_ Radar2_Obj04_movingState : 17|2@0+ (1,0) [0|3] "" Vector__XXX
 SG_ Radar2_Obj04_vy : 7|10@0+ (0.125,-64) [-64|63.875] "m/s" Vector__XXX
 SG_ Radar2_Obj04_vxSigma : 25|6@0+ (0.0625,0) [0|3.9375] "m/s" Vector__XXX
 SG_ Radar2_Obj04_dxSigma : 31|6@0+ (0.0625,0) [0|3.9375] "m" Vector__XXX
 SG_ Radar2_Obj04_axSigma : 35|6@0+ (0.0625,0) [0|3.9375] "m/s2" Vector__XXX
 SG_ Radar2_Obj04_MessBconsistBit : 56|1@0+ (1,0) [0|1] "" Vector__XXX

BO_ 1337 Radar2_Obj05_A: 8 Bosch_Radar2
 SG_ Radar2_Obj05_wObstacle : 53|5@0+ (0.03125,0) [0|0.96875] "" Vector__XXX
 SG_ Radar2_Obj05_wNonObstacle : 63|5@0+ (0.03125,0) [0|0.96875] "" Vector__XXX
 SG_ Radar2_Obj05_wExist : 36|5@0+ (0.03125,0) [0|0.96875] "-" Vector__XXX
 SG_ Radar2_Obj05_ax : 47|10@0+ (0.03125,-16) [-16|15.96875] "m/s2" Vector__XXX
 SG_ Radar2_Obj05_vx : 11|12@0+ (0.0625,-128) [-128|127.9375] "m/s" Vector__XXX
 SG_ Radar2_Obj05_dy : 31|11@0+ (0.125,-128) [-128|127.875] "m" Vector__XXX
 SG_ Radar2_Obj05_dx : 7|12@0+ (0.0625,-128) [-128|127.9375] "m" Vector__XXX
 SG_ Radar2_Obj05_flagValid : 48|1@0+ (1,0) [0|1] "" Vector__XXX
 SG_ Radar2_Obj05_flagHist : 57|1@0+ (1,0) [0|1] "" Vector__XXX
 SG_ Radar2_Obj05_flagMeas : 58|1@0+ (1,0) [0|1] "" Vector__XXX
 SG_ Radar2_Obj05_MessAconsistBit : 56|1@0+ (1,0) [0|1] "" Vector__XXX

BO_ 1338 Radar2_Obj05_B: 8 Bosch_Radar2
 SG_ Radar2_Obj05_wClass : 55|5@0+ (0.03125,0) [0|0.96875] "" Vector__XXX
 SG_ Radar2_Obj05_dxRearEndLoss : 63|6@0+ (0.125,0) [0|7.875] "m" Vector__XXX
 SG_ Radar2_Obj05_dySigma : 45|6@0+ (0.0625,0) [0|3.9375] "m" Vector__XXX
 SG_ Radar2_Obj05_dLength : 13|6@0+ (0.125,0) [0|7.875] "m" Vector__XXX
 SG_ Radar2_Obj05_class : 50|3@0+ (1,0) [0|7] "" Vector__XXX
 SG_ Radar2_Obj05_dz : 23|6@0+ (0.25,-5) [-5|10.75] "m" Vector__XXX
 SG_ Radar2_Obj05_movingState : 17|2@0+ (1,0) [0|3] "" Vector__XXX
 SG_ Radar2_Obj05_vy : 7|10@0+ (0.125,-64) [-64|63.875] "m/s" Vector__XXX
 SG_ Radar2_Obj05_vxSigma : 25|6@0+ (0.0625,0) [0|3.9375] "m/s" Vector__XXX
 SG_ Radar2_Obj05_dxSigma : 31|6@0+ (0.0625,0) [0|3.9375] "m" Vector__XXX
 SG_ Radar2_Obj05_axSigma : 35|6@0+ (0.0625,0) [0|3.9375] "m/s2" Vector__XXX
 SG_ Radar2_Obj05_MessBconsistBit : 56|1@0+ (1,0) [0|1] "" Vector__XXX

BO_ 1347 Radar2_Obj06_A: 8 Bosch_Radar2
 SG_ Radar2_Obj06_wObstacle : 53|5@0+ (0.03125,0) [0|0.96875] "" Vector__XXX
 SG_ Radar2_Obj06_wNonObstacle : 63|5@0+ (0.03125,0) [0|0.96875] "" Vector__XXX
 SG_ Radar2_Obj06_wExist : 36|5@0+ (0.03125,0) [0|0.96875] "-" Vector__XXX
 SG_ Radar2_Obj06_ax : 47|10@0+ (0.03125,-16) [-16|15.96875] "m/s2" Vector__XXX
 SG_ Radar2_Obj06_vx : 11|12@0+ (0.0625,-128) [-128|127.9375] "m/s" Vector__XXX
 SG_ Radar2_Obj06_dy : 31|11@0+ (0.125,-128) [-128|127.875] "m" Vector__XXX
 SG_ Radar2_Obj06_dx : 7|12@0+ (0.0625,-128) [-128|127.9375] "m" Vector__XXX
 SG_ Radar2_Obj06_flagValid : 48|1@0+ (1,0) [0|1] "" Vector__XXX
 SG_ Radar2_Obj06_flagHist : 57|1@0+ (1,0) [0|1] "" Vector__XXX
 SG_ Radar2_Obj06_flagMeas : 58|1@0+ (1,0) [0|1] "" Vector__XXX
 SG_ Radar2_Obj06_MessAconsistBit : 56|1@0+ (1,0) [0|1] "" Vector__XXX

BO_ 1348 Radar2_Obj06_B: 8 Bosch_Radar2
 SG_ Radar2_Obj06_wClass : 55|5@0+ (0.03125,0) [0|0.96875] "" Vector__XXX
 SG_ Radar2_Obj06_dxRearEndLoss : 63|6@0+ (0.125,0) [0|7.875] "m" Vector__XXX
 SG_ Radar2_Obj06_dySigma : 45|6@0+ (0.0625,0) [0|3.9375] "m" Vector__XXX
 SG_ Radar2_Obj06_dLength : 13|6@0+ (0.125,0) [0|7.875] "m" Vector__XXX
 SG_ Radar2_Obj06_class : 50|3@0+ (1,0) [0|7] "" Vector__XXX
 SG_ Radar2_Obj06_dz : 23|6@0+ (0.25,-5) [-5|10.75] "m" Vector__XXX
 SG_ Radar2_Obj06_movingState : 17|2@0+ (1,0) [0|3] "" Vector__XXX
 SG_ Radar2_Obj06_vy : 7|10@0+ (0.125,-64) [-64|63.875] "m/s" Vector__XXX
 SG_ Radar2_Obj06_vxSigma : 25|6@0+ (0.0625,0) [0|3.9375] "m/s" Vector__XXX
 SG_ Radar2_Obj06_dxSigma : 31|6@0+ (0.0625,0) [0|3.9375] "m" Vector__XXX
 SG_ Radar2_Obj06_axSigma : 35|6@0+ (0.0625,0) [0|3.9375] "m/s2" Vector__XXX
 SG_ Radar2_Obj06_MessBconsistBit : 56|1@0+ (1,0) [0|1] "" Vector__XXX

BO_ 1357 Radar2_Obj07_A: 8 Bosch_Radar2
 SG_ Radar2_Obj07_wObstacle : 53|5@0+ (0.03125,0) [0|0.96875] "" Vector__XXX
 SG_ Radar2_Obj07_wNonObstacle : 63|5@0+ (0.03125,0) [0|0.96875] "" Vector__XXX
 SG_ Radar2_Obj07_wExist : 36|5@0+ (0.03125,0) [0|0.96875] "-" Vector__XXX
 SG_ Radar2_Obj07_ax : 47|10@0+ (0.03125,-16) [-16|15.96875] "m/s2" Vector__XXX
 SG_ Radar2_Obj07_vx : 11|12@0+ (0.0625,-128) [-128|127.9375] "m/s" Vector__XXX
 SG_ Radar2_Obj07_dy : 31|11@0+ (0.125,-128) [-128|127.875] "m" Vector__XXX
 SG_ Radar2_Obj07_dx : 7|12@0+ (0.0625,-128) [-128|127.9375] "m" Vector__XXX
 SG_ Radar2_Obj07_flagValid : 48|1@0+ (1,0) [0|1] "" Vector__XXX
 SG_ Radar2_Obj07_flagHist : 57|1@0+ (1,0) [0|1] "" Vector__XXX
 SG_ Radar2_Obj07_flagMeas : 58|1@0+ (1,0) [0|1] "" Vector__XXX
 SG_ Radar2_Obj07_MessAconsistBit : 56|1@0+ (1,0) [0|1] "" Vector__XXX

BO_ 1358 Radar2_Obj07_B: 8 Bosch_Radar2
 SG_ Radar2_Obj07_wClass : 55|5@0+ (0.03125,0) [0|0.96875] "" Vector__XXX
 SG_ Radar2_Obj07_dxRearEndLoss : 63|6@0+ (0.125,0) [0|7.875] "m" Vector__XXX
 SG_ Radar2_Obj07_dySigma : 45|6@0+ (0.0625,0) [0|3.9375] "m" Vector__XXX
 SG_ Radar2_Obj07_dLength : 13|6@0+ (0.125,0) [0|7.875] "m" Vector__XXX
 SG_ Radar2_Obj07_class : 50|3@0+ (1,0) [0|7] "" Vector__XXX
 SG_ Radar2_Obj07_dz : 23|6@0+ (0.25,-5) [-5|10.75] "m" Vector__XXX
 SG_ Radar2_Obj07_movingState : 17|2@0+ (1,0) [0|3] "" Vector__XXX
 SG_ Radar2_Obj07_vy : 7|10@0+ (0.125,-64) [-64|63.875] "m/s" Vector__XXX
 SG_ Radar2_Obj07_vxSigma : 25|6@0+ (0.0625,0) [0|3.9375] "m/s" Vector__XXX
 SG_ Radar2_Obj07_dxSigma : 31|6@0+ (0.0625,0) [0|3.9375] "m" Vector__XXX
 SG_ Radar2_Obj07_axSigma : 35|6@0+ (0.0625,0) [0|3.9375] "m/s2" Vector__XXX
 SG_ Radar2_Obj07_MessBconsistBit : 56|1@0+ (1,0) [0|1] "" Vector__XXX

BO_ 1367 Radar2_Obj08_A: 8 Bosch_Radar2
 SG_ Radar2_Obj08_wObstacle : 53|5@0+ (0.03125,0) [0|0.96875] "" Vector__XXX
 SG_ Radar2_Obj08_wNonObstacle : 63|5@0+ (0.03125,0) [0|0.96875] "" Vector__XXX
 SG_ Radar2_Obj08_wExist : 36|5@0+ (0.03125,0) [0|0.96875] "-" Vector__XXX
 SG_ Radar2_Obj08_ax : 47|10@0+ (0.03125,-16) [-16|15.96875] "m/s2" Vector__XXX
 SG_ Radar2_Obj08_vx : 11|12@0+ (0.0625,-128) [-128|127.9375] "m/s" Vector__XXX
 SG_ Radar2_Obj08_dy : 31|11@0+ (0.125,-128) [-128|127.875] "m" Vector__XXX
 SG_ Radar2_Obj08_dx : 7|12@0+ (0.0625,-128) [-128|127.9375] "m" Vector__XXX
 SG_ Radar2_Obj08_flagValid : 48|1@0+ (1,0) [0|1] "" Vector__XXX
 SG_ Radar2_Obj08_flagHist : 57|1@0+ (1,0) [0|1] "" Vector__XXX
 SG_ Radar2_Obj08_flagMeas : 58|1@0+ (1,0) [0|1] "" Vector__XXX
 SG_ Radar2_Obj08_MessAconsistBit : 56|1@0+ (1,0) [0|1] "" Vector__XXX

BO_ 1368 Radar2_Obj08_B: 8 Bosch_Radar2
 SG_ Radar2_Obj08_wClass : 55|5@0+ (0.03125,0) [0|0.96875] "" Vector__XXX
 SG_ Radar2_Obj08_dxRearEndLoss : 63|6@0+ (0.125,0) [0|7.875] "m" Vector__XXX
 SG_ Radar2_Obj08_dySigma : 45|6@0+ (0.0625,0) [0|3.9375] "m" Vector__XXX
 SG_ Radar2_Obj08_dLength : 13|6@0+ (0.125,0) [0|7.875] "m" Vector__XXX
 SG_ Radar2_Obj08_class : 50|3@0+ (1,0) [0|7] "" Vector__XXX
 SG_ Radar2_Obj08_dz : 23|6@0+ (0.25,-5) [-5|10.75] "m" Vector__XXX
 SG_ Radar2_Obj08_movingState : 17|2@0+ (1,0) [0|3] "" Vector__XXX
 SG_ Radar2_Obj08_vy : 7|10@0+ (0.125,-64) [-64|63.875] "m/s" Vector__XXX
 SG_ Radar2_Obj08_vxSigma : 25|6@0+ (0.0625,0) [0|3.9375] "m/s" Vector__XXX
 SG_ Radar2_Obj08_dxSigma : 31|6@0+ (0.0625,0) [0|3.9375] "m" Vector__XXX
 SG_ Radar2_Obj08_axSigma : 35|6@0+ (0.0625,0) [0|3.9375] "m/s2" Vector__XXX
 SG_ Radar2_Obj08_MessBconsistBit : 56|1@0+ (1,0) [0|1] "" Vector__XXX

BO_ 1377 Radar2_Obj09_A: 8 Bosch_Radar2
 SG_ Radar2_Obj09_wObstacle : 53|5@0+ (0.03125,0) [0|0.96875] "" Vector__XXX
 SG_ Radar2_Obj09_wNonObstacle : 63|5@0+ (0.03125,0) [0|0.96875] "" Vector__XXX
 SG_ Radar2_Obj09_wExist : 36|5@0+ (0.03125,0) [0|0.96875] "-" Vector__XXX
 SG_ Radar2_Obj09_ax : 47|10@0+ (0.03125,-16) [-16|15.96875] "m/s2" Vector__XXX
 SG_ Radar2_Obj09_vx : 11|12@0+ (0.0625,-128) [-128|127.9375] "m/s" Vector__XXX
 SG_ Radar2_Obj09_dy : 31|11@0+ (0.125,-128) [-128|127.875] "m" Vector__XXX
 SG_ Radar2_Obj09_dx : 7|12@0+ (0.0625,-128) [-128|127.9375] "m" Vector__XXX
 SG_ Radar2_Obj09_flagValid : 48|1@0+ (1,0) [0|1] "" Vector__XXX
 SG_ Radar2_Obj09_flagHist : 57|1@0+ (1,0) [0|1] "" Vector__XXX
 SG_ Radar2_Obj09_flagMeas : 58|1@0+ (1,0) [0|1] "" Vector__XXX
 SG_ Radar2_Obj09_MessAconsistBit : 56|1@0+ (1,0) [0|1] "" Vector__XXX

BO_ 1378 Radar2_Obj09_B: 8 Bosch_Radar2
 SG_ Radar2_Obj09_wClass : 55|5@0+ (0.03125,0) [0|0.96875] "" Vector__XXX
 SG_ Radar2_Obj09_dxRearEndLoss : 63|6@0+ (0.125,0) [0|7.875] "m" Vector__XXX
 SG_ Radar2_Obj09_dySigma : 45|6@0+ (0.0625,0) [0|3.9375] "m" Vector__XXX
 SG_ Radar2_Obj09_dLength : 13|6@0+ (0.125,0) [0|7.875] "m" Vector__XXX
 SG_ Radar2_Obj09_class : 50|3@0+ (1,0) [0|7] "" Vector__XXX
 SG_ Radar2_Obj09_dz : 23|6@0+ (0.25,-5) [-5|10.75] "m" Vector__XXX
 SG_ Radar2_Obj09_movingState : 17|2@0+ (1,0) [0|3] "" Vector__XXX
 SG_ Radar2_Obj09_vy : 7|10@0+ (0.125,-64) [-64|63.875] "m/s" Vector__XXX
 SG_ Radar2_Obj09_vxSigma : 25|6@0+ (0.0625,0) [0|3.9375] "m/s" Vector__XXX
 SG_ Radar2_Obj09_dxSigma : 31|6@0+ (0.0625,0) [0|3.9375] "m" Vector__XXX
 SG_ Radar2_Obj09_axSigma : 35|6@0+ (0.0625,0) [0|3.9375] "m/s2" Vector__XXX
 SG_ Radar2_Obj09_MessBconsistBit : 56|1@0+ (1,0) [0|1] "" Vector__XXX

BO_ 1387 Radar2_Obj10_A: 8 Bosch_Radar2
 SG_ Radar2_Obj10_wObstacle : 53|5@0+ (0.03125,0) [0|0.96875] "" Vector__XXX
 SG_ Radar2_Obj10_wNonObstacle : 63|5@0+ (0.03125,0) [0|0.96875] "" Vector__XXX
 SG_ Radar2_Obj10_wExist : 36|5@0+ (0.03125,0) [0|0.96875] "-" Vector__XXX
 SG_ Radar2_Obj10_ax : 47|10@0+ (0.03125,-16) [-16|15.96875] "m/s2" Vector__XXX
 SG_ Radar2_Obj10_vx : 11|12@0+ (0.0625,-128) [-128|127.9375] "m/s" Vector__XXX
 SG_ Radar2_Obj10_dy : 31|11@0+ (0.125,-128) [-128|127.875] "m" Vector__XXX
 SG_ Radar2_Obj10_dx : 7|12@0+ (0.0625,-128) [-128|127.9375] "m" Vector__XXX
 SG_ Radar2_Obj10_flagValid : 48|1@0+ (1,0) [0|1] "" Vector__XXX
 SG_ Radar2_Obj10_flagHist : 57|1@0+ (1,0) [0|1] "" Vector__XXX
 SG_ Radar2_Obj10_flagMeas : 58|1@0+ (1,0) [0|1] "" Vector__XXX
 SG_ Radar2_Obj10_MessAconsistBit : 56|1@0+ (1,0) [0|1] "" Vector__XXX

BO_ 1388 Radar2_Obj10_B: 8 Bosch_Radar2
 SG_ Radar2_Obj10_wClass : 55|5@0+ (0.03125,0) [0|0.96875] "" Vector__XXX
 SG_ Radar2_Obj10_dxRearEndLoss : 63|6@0+ (0.125,0) [0|7.875] "m" Vector__XXX
 SG_ Radar2_Obj10_dySigma : 45|6@0+ (0.0625,0) [0|3.9375] "m" Vector__XXX
 SG_ Radar2_Obj10_dLength : 13|6@0+ (0.125,0) [0|7.875] "m" Vector__XXX
 SG_ Radar2_Obj10_class : 50|3@0+ (1,0) [0|7] "" Vector__XXX
 SG_ Radar2_Obj10_dz : 23|6@0+ (0.25,-5) [-5|10.75] "m" Vector__XXX
 SG_ Radar2_Obj10_movingState : 17|2@0+ (1,0) [0|3] "" Vector__XXX
 SG_ Radar2_Obj10_vy : 7|10@0+ (0.125,-64) [-64|63.875] "m/s" Vector__XXX
 SG_ Radar2_Obj10_vxSigma : 25|6@0+ (0.0625,0) [0|3.9375] "m/s" Vector__XXX
 SG_ Radar2_Obj10_dxSigma : 31|6@0+ (0.0625,0) [0|3.9375] "m" Vector__XXX
 SG_ Radar2_Obj10_axSigma : 35|6@0+ (0.0625,0) [0|3.9375] "m/s2" Vector__XXX
 SG_ Radar2_Obj10_MessBconsistBit : 56|1@0+ (1,0) [0|1] "" Vector__XXX

BO_ 1397 Radar2_Obj11_A: 8 Bosch_Radar2
 SG_ Radar2_Obj11_wObstacle : 53|5@0+ (0.03125,0) [0|0.96875] "" Vector__XXX
 SG_ Radar2_Obj11_wNonObstacle : 63|5@0+ (0.03125,0) [0|0.96875] "" Vector__XXX
 SG_ Radar2_Obj11_wExist : 36|5@0+ (0.03125,0) [0|0.96875] "-" Vector__XXX
 SG_ Radar2_Obj11_ax : 47|10@0+ (0.03125,-16) [-16|15.96875] "m/s2" Vector__XXX
 SG_ Radar2_Obj11_vx : 11|12@0+ (0.0625,-128) [-128|127.9375] "m/s" Vector__XXX
 SG_ Radar2_Obj11_dy : 31|11@0+ (0.125,-128) [-128|127.875] "m" Vector__XXX
 SG_ Radar2_Obj11_dx : 7|12@0+ (0.0625,-128) [-128|127.9375] "m" Vector__XXX
 SG_ Radar2_Obj11_flagValid : 48|1@0+ (1,0) [0|1] "" Vector__XXX
 SG_ Radar2_Obj11_flagHist : 57|1@0+ (1,0) [0|1] "" Vector__XXX
 SG_ Radar2_Obj11_flagMeas : 58|1@0+ (1,0) [0|1] "" Vector__XXX
 SG_ Radar2_Obj11_MessAconsistBit : 56|1@0+ (1,0) [0|1] "" Vector__XXX

BO_ 1398 Radar2_Obj11_B: 8 Bosch_Radar2
 SG_ Radar2_Obj11_wClass : 55|5@0+ (0.03125,0) [0|0.96875] "" Vector__XXX
 SG_ Radar2_Obj11_dxRearEndLoss : 63|6@0+ (0.125,0) [0|7.875] "m" Vector__XXX
 SG_ Radar2_Obj11_dySigma : 45|6@0+ (0.0625,0) [0|3.9375] "m" Vector__XXX
 SG_ Radar2_Obj11_dLength : 13|6@0+ (0.125,0) [0|7.875] "m" Vector__XXX
 SG_ Radar2_Obj11_class : 50|3@0+ (1,0) [0|7] "" Vector__XXX
 SG_ Radar2_Obj11_dz : 23|6@0+ (0.25,-5) [-5|10.75] "m" Vector__XXX
 SG_ Radar2_Obj11_movingState : 17|2@0+ (1,0) [0|3] "" Vector__XXX
 SG_ Radar2_Obj11_vy : 7|10@0+ (0.125,-64) [-64|63.875] "m/s" Vector__XXX
 SG_ Radar2_Obj11_vxSigma : 25|6@0+ (0.0625,0) [0|3.9375] "m/s" Vector__XXX
 SG_ Radar2_Obj11_dxSigma : 31|6@0+ (0.0625,0) [0|3.9375] "m" Vector__XXX
 SG_ Radar2_Obj11_axSigma : 35|6@0+ (0.0625,0) [0|3.9375] "m/s2" Vector__XXX
 SG_ Radar2_Obj11_MessBconsistBit : 56|1@0+ (1,0) [0|1] "" Vector__XXX

BO_ 1407 Radar2_Obj12_A: 8 Bosch_Radar2
 SG_ Radar2_Obj12_wObstacle : 53|5@0+ (0.03125,0) [0|0.96875] "" Vector__XXX
 SG_ Radar2_Obj12_wNonObstacle : 63|5@0+ (0.03125,0) [0|0.96875] "" Vector__XXX
 SG_ Radar2_Obj12_wExist : 36|5@0+ (0.03125,0) [0|0.96875] "-" Vector__XXX
 SG_ Radar2_Obj12_ax : 47|10@0+ (0.03125,-16) [-16|15.96875] "m/s2" Vector__XXX
 SG_ Radar2_Obj12_vx : 11|12@0+ (0.0625,-128) [-128|127.9375] "m/s" Vector__XXX
 SG_ Radar2_Obj12_dy : 31|11@0+ (0.125,-128) [-128|127.875] "m" Vector__XXX
 SG_ Radar2_Obj12_dx : 7|12@0+ (0.0625,-128) [-128|127.9375] "m" Vector__XXX
 SG_ Radar2_Obj12_flagValid : 48|1@0+ (1,0) [0|1] "" Vector__XXX
 SG_ Radar2_Obj12_flagHist : 57|1@0+ (1,0) [0|1] "" Vector__XXX
 SG_ Radar2_Obj12_flagMeas : 58|1@0+ (1,0) [0|1] "" Vector__XXX
 SG_ Radar2_Obj12_MessAconsistBit : 56|1@0+ (1,0) [0|1] "" Vector__XXX

BO_ 1408 Radar2_Obj12_B: 8 Bosch_Radar2
 SG_ Radar2_Obj12_wClass : 55|5@0+ (0.03125,0) [0|0.96875] "" Vector__XXX
 SG_ Radar2_Obj12_dxRearEndLoss : 63|6@0+ (0.125,0) [0|7.875] "m" Vector__XXX
 SG_ Radar2_Obj12_dySigma : 45|6@0+ (0.0625,0) [0|3.9375] "m" Vector__XXX
 SG_ Radar2_Obj12_dLength : 13|6@0+ (0.125,0) [0|7.875] "m" Vector__XXX
 SG_ Radar2_Obj12_class : 50|3@0+ (1,0) [0|7] "" Vector__XXX
 SG_ Radar2_Obj12_dz : 23|6@0+ (0.25,-5) [-5|10.75] "m" Vector__XXX
 SG_ Radar2_Obj12_movingState : 17|2@0+ (1,0) [0|3] "" Vector__XXX
 SG_ Radar2_Obj12_vy : 7|10@0+ (0.125,-64) [-64|63.875] "m/s" Vector__XXX
 SG_ Radar2_Obj12_vxSigma : 25|6@0+ (0.0625,0) [0|3.9375] "m/s" Vector__XXX
 SG_ Radar2_Obj12_dxSigma : 31|6@0+ (0.0625,0) [0|3.9375] "m" Vector__XXX
 SG_ Radar2_Obj12_axSigma : 35|6@0+ (0.0625,0) [0|3.9375] "m/s2" Vector__XXX
 SG_ Radar2_Obj12_MessBconsistBit : 56|1@0+ (1,0) [0|1] "" Vector__XXX

BO_ 1417 Radar2_Obj13_A: 8 Bosch_Radar2
 SG_ Radar2_Obj13_wObstacle : 53|5@0+ (0.03125,0) [0|0.96875] "" Vector__XXX
 SG_ Radar2_Obj13_wNonObstacle : 63|5@0+ (0.03125,0) [0|0.96875] "" Vector__XXX
 SG_ Radar2_Obj13_wExist : 36|5@0+ (0.03125,0) [0|0.96875] "-" Vector__XXX
 SG_ Radar2_Obj13_ax : 47|10@0+ (0.03125,-16) [-16|15.96875] "m/s2" Vector__XXX
 SG_ Radar2_Obj13_vx : 11|12@0+ (0.0625,-128) [-128|127.9375] "m/s" Vector__XXX
 SG_ Radar2_Obj13_dy : 31|11@0+ (0.125,-128) [-128|127.875] "m" Vector__XXX
 SG_ Radar2_Obj13_dx : 7|12@0+ (0.0625,-128) [-128|127.9375] "m" Vector__XXX
 SG_ Radar2_Obj13_flagValid : 48|1@0+ (1,0) [0|1] "" Vector__XXX
 SG_ Radar2_Obj13_flagHist : 57|1@0+ (1,0) [0|1] "" Vector__XXX
 SG_ Radar2_Obj13_flagMeas : 58|1@0+ (1,0) [0|1] "" Vector__XXX
 SG_ Radar2_Obj13_MessAconsistBit : 56|1@0+ (1,0) [0|1] "" Vector__XXX

BO_ 1418 Radar2_Obj13_B: 8 Bosch_Radar2
 SG_ Radar2_Obj13_wClass : 55|5@0+ (0.03125,0) [0|0.96875] "" Vector__XXX
 SG_ Radar2_Obj13_dxRearEndLoss : 63|6@0+ (0.125,0) [0|7.875] "m" Vector__XXX
 SG_ Radar2_Obj13_dySigma : 45|6@0+ (0.0625,0) [0|3.9375] "m" Vector__XXX
 SG_ Radar2_Obj13_dLength : 13|6@0+ (0.125,0) [0|7.875] "m" Vector__XXX
 SG_ Radar2_Obj13_class : 50|3@0+ (1,0) [0|7] "" Vector__XXX
 SG_ Radar2_Obj13_dz : 23|6@0+ (0.25,-5) [-5|10.75] "m" Vector__XXX
 SG_ Radar2_Obj13_movingState : 17|2@0+ (1,0) [0|3] "" Vector__XXX
 SG_ Radar2_Obj13_vy : 7|10@0+ (0.125,-64) [-64|63.875] "m/s" Vector__XXX
 SG_ Radar2_Obj13_vxSigma : 25|6@0+ (0.0625,0) [0|3.9375] "m/s" Vector__XXX
 SG_ Radar2_Obj13_dxSigma : 31|6@0+ (0.0625,0) [0|3.9375] "m" Vector__XXX
 SG_ Radar2_Obj13_axSigma : 35|6@0+ (0.0625,0) [0|3.9375] "m/s2" Vector__XXX
 SG_ Radar2_Obj13_MessBconsistBit : 56|1@0+ (1,0) [0|1] "" Vector__XXX

BO_ 1427 Radar2_Obj14_A: 8 Bosch_Radar2
 SG_ Radar2_Obj14_wObstacle : 53|5@0+ (0.03125,0) [0|0.96875] "" Vector__XXX
 SG_ Radar2_Obj14_wNonObstacle : 63|5@0+ (0.03125,0) [0|0.96875] "" Vector__XXX
 SG_ Radar2_Obj14_wExist : 36|5@0+ (0.03125,0) [0|0.96875] "-" Vector__XXX
 SG_ Radar2_Obj14_ax : 47|10@0+ (0.03125,-16) [-16|15.96875] "m/s2" Vector__XXX
 SG_ Radar2_Obj14_vx : 11|12@0+ (0.0625,-128) [-128|127.9375] "m/s" Vector__XXX
 SG_ Radar2_Obj14_dy : 31|11@0+ (0.125,-128) [-128|127.875] "m" Vector__XXX
 SG_ Radar2_Obj14_dx : 7|12@0+ (0.0625,-128) [-128|127.9375] "m" Vector__XXX
 SG_ Radar2_Obj14_flagValid : 48|1@0+ (1,0) [0|1] "" Vector__XXX
 SG_ Radar2_Obj14_flagHist : 57|1@0+ (1,0) [0|1] "" Vector__XXX
 SG_ Radar2_Obj14_flagMeas : 58|1@0+ (1,0) [0|1] "" Vector__XXX
 SG_ Radar2_Obj14_MessAconsistBit : 56|1@0+ (1,0) [0|1] "" Vector__XXX

BO_ 1428 Radar2_Obj14_B: 8 Bosch_Radar2
 SG_ Radar2_Obj14_wClass : 55|5@0+ (0.03125,0) [0|0.96875] "" Vector__XXX
 SG_ Radar2_Obj14_dxRearEndLoss : 63|6@0+ (0.125,0) [0|7.875] "m" Vector__XXX
 SG_ Radar2_Obj14_dySigma : 45|6@0+ (0.0625,0) [0|3.9375] "m" Vector__XXX
 SG_ Radar2_Obj14_dLength : 13|6@0+ (0.125,0) [0|7.875] "m" Vector__XXX
 SG_ Radar2_Obj14_class : 50|3@0+ (1,0) [0|7] "" Vector__XXX
 SG_ Radar2_Obj14_dz : 23|6@0+ (0.25,-5) [-5|10.75] "m" Vector__XXX
 SG_ Radar2_Obj14_movingState : 17|2@0+ (1,0) [0|3] "" Vector__XXX
 SG_ Radar2_Obj14_vy : 7|10@0+ (0.125,-64) [-64|63.875] "m/s" Vector__XXX
 SG_ Radar2_Obj14_vxSigma : 25|6@0+ (0.0625,0) [0|3.9375] "m/s" Vector__XXX
 SG_ Radar2_Obj14_dxSigma : 31|6@0+ (0.0625,0) [0|3.9375] "m" Vector__XXX
 SG_ Radar2_Obj14_axSigma : 35|6@0+ (0.0625,0) [0|3.9375] "m/s2" Vector__XXX
 SG_ Radar2_Obj14_MessBconsistBit : 56|1@0+ (1,0) [0|1] "" Vector__XXX

BO_ 1437 Radar2_Obj15_A: 8 Bosch_Radar2
 SG_ Radar2_Obj15_wObstacle : 53|5@0+ (0.03125,0) [0|0.96875] "" Vector__XXX
 SG_ Radar2_Obj15_wNonObstacle : 63|5@0+ (0.03125,0) [0|0.96875] "" Vector__XXX
 SG_ Radar2_Obj15_wExist : 36|5@0+ (0.03125,0) [0|0.96875] "-" Vector__XXX
 SG_ Radar2_Obj15_ax : 47|10@0+ (0.03125,-16) [-16|15.96875] "m/s2" Vector__XXX
 SG_ Radar2_Obj15_vx : 11|12@0+ (0.0625,-128) [-128|127.9375] "m/s" Vector__XXX
 SG_ Radar2_Obj15_dy : 31|11@0+ (0.125,-128) [-128|127.875] "m" Vector__XXX
 SG_ Radar2_Obj15_dx : 7|12@0+ (0.0625,-128) [-128|127.9375] "m" Vector__XXX
 SG_ Radar2_Obj15_flagValid : 48|1@0+ (1,0) [0|1] "" Vector__XXX
 SG_ Radar2_Obj15_flagHist : 57|1@0+ (1,0) [0|1] "" Vector__XXX
 SG_ Radar2_Obj15_flagMeas : 58|1@0+ (1,0) [0|1] "" Vector__XXX
 SG_ Radar2_Obj15_MessAconsistBit : 56|1@0+ (1,0) [0|1] "" Vector__XXX

BO_ 1438 Radar2_Obj15_B: 8 Bosch_Radar2
 SG_ Radar2_Obj15_wClass : 55|5@0+ (0.03125,0) [0|0.96875] "" Vector__XXX
 SG_ Radar2_Obj15_dxRearEndLoss : 63|6@0+ (0.125,0) [0|7.875] "m" Vector__XXX
 SG_ Radar2_Obj15_dySigma : 45|6@0+ (0.0625,0) [0|3.9375] "m" Vector__XXX
 SG_ Radar2_Obj15_dLength : 13|6@0+ (0.125,0) [0|7.875] "m" Vector__XXX
 SG_ Radar2_Obj15_class : 50|3@0+ (1,0) [0|7] "" Vector__XXX
 SG_ Radar2_Obj15_dz : 23|6@0+ (0.25,-5) [-5|10.75] "m" Vector__XXX
 SG_ Radar2_Obj15_movingState : 17|2@0+ (1,0) [0|3] "" Vector__XXX
 SG_ Radar2_Obj15_vy : 7|10@0+ (0.125,-64) [-64|63.875] "m/s" Vector__XXX
 SG_ Radar2_Obj15_vxSigma : 25|6@0+ (0.0625,0) [0|3.9375] "m/s" Vector__XXX
 SG_ Radar2_Obj15_dxSigma : 31|6@0+ (0.0625,0) [0|3.9375] "m" Vector__XXX
 SG_ Radar2_Obj15_axSigma : 35|6@0+ (0.0625,0) [0|3.9375] "m/s2" Vector__XXX
 SG_ Radar2_Obj15_MessBconsistBit : 56|1@0+ (1,0) [0|1] "" Vector__XXX

BO_ 1447 Radar2_Obj16_A: 8 Bosch_Radar2
 SG_ Radar2_Obj16_wObstacle : 53|5@0+ (0.03125,0) [0|0.96875] "" Vector__XXX
 SG_ Radar2_Obj16_wNonObstacle : 63|5@0+ (0.03125,0) [0|0.96875] "" Vector__XXX
 SG_ Radar2_Obj16_wExist : 36|5@0+ (0.03125,0) [0|0.96875] "-" Vector__XXX
 SG_ Radar2_Obj16_ax : 47|10@0+ (0.03125,-16) [-16|15.96875] "m/s2" Vector__XXX
 SG_ Radar2_Obj16_vx : 11|12@0+ (0.0625,-128) [-128|127.9375] "m/s" Vector__XXX
 SG_ Radar2_Obj16_dy : 31|11@0+ (0.125,-128) [-128|127.875] "m" Vector__XXX
 SG_ Radar2_Obj16_dx : 7|12@0+ (0.0625,-128) [-128|127.9375] "m" Vector__XXX
 SG_ Radar2_Obj16_flagValid : 48|1@0+ (1,0) [0|1] "" Vector__XXX
 SG_ Radar2_Obj16_flagHist : 57|1@0+ (1,0) [0|1] "" Vector__XXX
 SG_ Radar2_Obj16_flagMeas : 58|1@0+ (1,0) [0|1] "" Vector__XXX
 SG_ Radar2_Obj16_MessAconsistBit : 56|1@0+ (1,0) [0|1] "" Vector__XXX

BO_ 1448 Radar2_Obj16_B: 8 Bosch_Radar2
 SG_ Radar2_Obj16_wClass : 55|5@0+ (0.03125,0) [0|0.96875] "" Vector__XXX
 SG_ Radar2_Obj16_dxRearEndLoss : 63|6@0+ (0.125,0) [0|7.875] "m" Vector__XXX
 SG_ Radar2_Obj16_dySigma : 45|6@0+ (0.0625,0) [0|3.9375] "m" Vector__XXX
 SG_ Radar2_Obj16_dLength : 13|6@0+ (0.125,0) [0|7.875] "m" Vector__XXX
 SG_ Radar2_Obj16_class : 50|3@0+ (1,0) [0|7] "" Vector__XXX
 SG_ Radar2_Obj16_dz : 23|6@0+ (0.25,-5) [-5|10.75] "m" Vector__XXX
 SG_ Radar2_Obj16_movingState : 17|2@0+ (1,0) [0|3] "" Vector__XXX
 SG_ Radar2_Obj16_vy : 7|10@0+ (0.125,-64) [-64|63.875] "m/s" Vector__XXX
 SG_ Radar2_Obj16_vxSigma : 25|6@0+ (0.0625,0) [0|3.9375] "m/s" Vector__XXX
 SG_ Radar2_Obj16_dxSigma : 31|6@0+ (0.0625,0) [0|3.9375] "m" Vector__XXX
 SG_ Radar2_Obj16_axSigma : 35|6@0+ (0.0625,0) [0|3.9375] "m/s2" Vector__XXX
 SG_ Radar2_Obj16_MessBconsistBit : 56|1@0+ (1,0) [0|1] "" Vector__XXX

BO_ 1457 Radar2_Obj17_A: 8 Bosch_Radar2
 SG_ Radar2_Obj17_wObstacle : 53|5@0+ (0.03125,0) [0|0.96875] "" Vector__XXX
 SG_ Radar2_Obj17_wNonObstacle : 63|5@0+ (0.03125,0) [0|0.96875] "" Vector__XXX
 SG_ Radar2_Obj17_wExist : 36|5@0+ (0.03125,0) [0|0.96875] "-" Vector__XXX
 SG_ Radar2_Obj17_ax : 47|10@0+ (0.03125,-16) [-16|15.96875] "m/s2" Vector__XXX
 SG_ Radar2_Obj17_vx : 11|12@0+ (0.0625,-128) [-128|127.9375] "m/s" Vector__XXX
 SG_ Radar2_Obj17_dy : 31|11@0+ (0.125,-128) [-128|127.875] "m" Vector__XXX
 SG_ Radar2_Obj17_dx : 7|12@0+ (0.0625,-128) [-128|127.9375] "m" Vector__XXX
 SG_ Radar2_Obj17_flagValid : 48|1@0+ (1,0) [0|1] "" Vector__XXX
 SG_ Radar2_Obj17_flagHist : 57|1@0+ (1,0) [0|1] "" Vector__XXX
 SG_ Radar2_Obj17_flagMeas : 58|1@0+ (1,0) [0|1] "" Vector__XXX
 SG_ Radar2_Obj17_MessAconsistBit : 56|1@0+ (1,0) [0|1] "" Vector__XXX

BO_ 1458 Radar2_Obj17_B: 8 Bosch_Radar2
 SG_ Radar2_Obj17_wClass : 55|5@0+ (0.03125,0) [0|0.96875] "" Vector__XXX
 SG_ Radar2_Obj17_dxRearEndLoss : 63|6@0+ (0.125,0) [0|7.875] "m" Vector__XXX
 SG_ Radar2_Obj17_dySigma : 45|6@0+ (0.0625,0) [0|3.9375] "m" Vector__XXX
 SG_ Radar2_Obj17_dLength : 13|6@0+ (0.125,0) [0|7.875] "m" Vector__XXX
 SG_ Radar2_Obj17_class : 50|3@0+ (1,0) [0|7] "" Vector__XXX
 SG_ Radar2_Obj17_dz : 23|6@0+ (0.25,-5) [-5|10.75] "m" Vector__XXX
 SG_ Radar2_Obj17_movingState : 17|2@0+ (1,0) [0|3] "" Vector__XXX
 SG_ Radar2_Obj17_vy : 7|10@0+ (0.125,-64) [-64|63.875] "m/s" Vector__XXX
 SG_ Radar2_Obj17_vxSigma : 25|6@0+ (0.0625,0) [0|3.9375] "m/s" Vector__XXX
 SG_ Radar2_Obj17_dxSigma : 31|6@0+ (0.0625,0) [0|3.9375] "m" Vector__XXX
 SG_ Radar2_Obj17_axSigma : 35|6@0+ (0.0625,0) [0|3.9375] "m/s2" Vector__XXX
 SG_ Radar2_Obj17_MessBconsistBit : 56|1@0+ (1,0) [0|1] "" Vector__XXX

BO_ 1467 Radar2_Obj18_A: 8 Bosch_Radar2
 SG_ Radar2_Obj18_wObstacle : 53|5@0+ (0.03125,0) [0|0.96875] "" Vector__XXX
 SG_ Radar2_Obj18_wNonObstacle : 63|5@0+ (0.03125,0) [0|0.96875] "" Vector__XXX
 SG_ Radar2_Obj18_wExist : 36|5@0+ (0.03125,0) [0|0.96875] "-" Vector__XXX
 SG_ Radar2_Obj18_ax : 47|10@0+ (0.03125,-16) [-16|15.96875] "m/s2" Vector__XXX
 SG_ Radar2_Obj18_vx : 11|12@0+ (0.0625,-128) [-128|127.9375] "m/s" Vector__XXX
 SG_ Radar2_Obj18_dy : 31|11@0+ (0.125,-128) [-128|127.875] "m" Vector__XXX
 SG_ Radar2_Obj18_dx : 7|12@0+ (0.0625,-128) [-128|127.9375] "m" Vector__XXX
 SG_ Radar2_Obj18_flagValid : 48|1@0+ (1,0) [0|1] "" Vector__XXX
 SG_ Radar2_Obj18_flagHist : 57|1@0+ (1,0) [0|1] "" Vector__XXX
 SG_ Radar2_Obj18_flagMeas : 58|1@0+ (1,0) [0|1] "" Vector__XXX
 SG_ Radar2_Obj18_MessAconsistBit : 56|1@0+ (1,0) [0|1] "" Vector__XXX

BO_ 1468 Radar2_Obj18_B: 8 Bosch_Radar2
 SG_ Radar2_Obj18_wClass : 55|5@0+ (0.03125,0) [0|0.96875] "" Vector__XXX
 SG_ Radar2_Obj18_dxRearEndLoss : 63|6@0+ (0.125,0) [0|7.875] "m" Vector__XXX
 SG_ Radar2_Obj18_dySigma : 45|6@0+ (0.0625,0) [0|3.9375] "m" Vector__XXX
 SG_ Radar2_Obj18_dLength : 13|6@0+ (0.125,0) [0|7.875] "m" Vector__XXX
 SG_ Radar2_Obj18_class : 50|3@0+ (1,0) [0|7] "" Vector__XXX
 SG_ Radar2_Obj18_dz : 23|6@0+ (0.25,-5) [-5|10.75] "m" Vector__XXX
 SG_ Radar2_Obj18_movingState : 17|2@0+ (1,0) [0|3] "" Vector__XXX
 SG_ Radar2_Obj18_vy : 7|10@0+ (0.125,-64) [-64|63.875] "m/s" Vector__XXX
 SG_ Radar2_Obj18_vxSigma : 25|6@0+ (0.0625,0) [0|3.9375] "m/s" Vector__XXX
 SG_ Radar2_Obj18_dxSigma : 31|6@0+ (0.0625,0) [0|3.9375] "m" Vector__XXX
 SG_ Radar2_Obj18_axSigma : 35|6@0+ (0.0625,0) [0|3.9375] "m/s2" Vector__XXX
 SG_ Radar2_Obj18_MessBconsistBit : 56|1@0+ (1,0) [0|1] "" Vector__XXX

BO_ 1477 Radar2_Obj19_A: 8 Bosch_Radar2
 SG_ Radar2_Obj19_wObstacle : 53|5@0+ (0.03125,0) [0|0.96875] "" Vector__XXX
 SG_ Radar2_Obj19_wNonObstacle : 63|5@0+ (0.03125,0) [0|0.96875] "" Vector__XXX
 SG_ Radar2_Obj19_wExist : 36|5@0+ (0.03125,0) [0|0.96875] "-" Vector__XXX
 SG_ Radar2_Obj19_ax : 47|10@0+ (0.03125,-16) [-16|15.96875] "m/s2" Vector__XXX
 SG_ Radar2_Obj19_vx : 11|12@0+ (0.0625,-128) [-128|127.9375] "m/s" Vector__XXX
 SG_ Radar2_Obj19_dy : 31|11@0+ (0.125,-128) [-128|127.875] "m" Vector__XXX
 SG_ Radar2_Obj19_dx : 7|12@0+ (0.0625,-128) [-128|127.9375] "m" Vector__XXX
 SG_ Radar2_Obj19_flagValid : 48|1@0+ (1,0) [0|1] "" Vector__XXX
 SG_ Radar2_Obj19_flagHist : 57|1@0+ (1,0) [0|1] "" Vector__XXX
 SG_ Radar2_Obj19_flagMeas : 58|1@0+ (1,0) [0|1] "" Vector__XXX
 SG_ Radar2_Obj19_MessAconsistBit : 56|1@0+ (1,0) [0|1] "" Vector__XXX

BO_ 1478 Radar2_Obj19_B: 8 Bosch_Radar2
 SG_ Radar2_Obj19_wClass : 55|5@0+ (0.03125,0) [0|0.96875] "" Vector__XXX
 SG_ Radar2_Obj19_dxRearEndLoss : 63|6@0+ (0.125,0) [0|7.875] "m" Vector__XXX
 SG_ Radar2_Obj19_dySigma : 45|6@0+ (0.0625,0) [0|3.9375] "m" Vector__XXX
 SG_ Radar2_Obj19_dLength : 13|6@0+ (0.125,0) [0|7.875] "m" Vector__XXX
 SG_ Radar2_Obj19_class : 50|3@0+ (1,0) [0|7] "" Vector__XXX
 SG_ Radar2_Obj19_dz : 23|6@0+ (0.25,-5) [-5|10.75] "m" Vector__XXX
 SG_ Radar2_Obj19_movingState : 17|2@0+ (1,0) [0|3] "" Vector__XXX
 SG_ Radar2_Obj19_vy : 7|10@0+ (0.125,-64) [-64|63.875] "m/s" Vector__XXX
 SG_ Radar2_Obj19_vxSigma : 25|6@0+ (0.0625,0) [0|3.9375] "m/s" Vector__XXX
 SG_ Radar2_Obj19_dxSigma : 31|6@0+ (0.0625,0) [0|3.9375] "m" Vector__XXX
 SG_ Radar2_Obj19_axSigma : 35|6@0+ (0.0625,0) [0|3.9375] "m/s2" Vector__XXX
 SG_ Radar2_Obj19_MessBconsistBit : 56|1@0+ (1,0) [0|1] "" Vector__XXX

BO_ 1487 Radar2_Obj20_A: 8 Bosch_Radar2
 SG_ Radar2_Obj20_wObstacle : 53|5@0+ (0.03125,0) [0|0.96875] "" Vector__XXX
 SG_ Radar2_Obj20_wNonObstacle : 63|5@0+ (0.03125,0) [0|0.96875] "" Vector__XXX
 SG_ Radar2_Obj20_wExist : 36|5@0+ (0.03125,0) [0|0.96875] "-" Vector__XXX
 SG_ Radar2_Obj20_ax : 47|10@0+ (0.03125,-16) [-16|15.96875] "m/s2" Vector__XXX
 SG_ Radar2_Obj20_vx : 11|12@0+ (0.0625,-128) [-128|127.9375] "m/s" Vector__XXX
 SG_ Radar2_Obj20_dy : 31|11@0+ (0.125,-128) [-128|127.875] "m" Vector__XXX
 SG_ Radar2_Obj20_dx : 7|12@0+ (0.0625,-128) [-128|127.9375] "m" Vector__XXX
 SG_ Radar2_Obj20_flagValid : 48|1@0+ (1,0) [0|1] "" Vector__XXX
 SG_ Radar2_Obj20_flagHist : 57|1@0+ (1,0) [0|1] "" Vector__XXX
 SG_ Radar2_Obj20_flagMeas : 58|1@0+ (1,0) [0|1] "" Vector__XXX
 SG_ Radar2_Obj20_MessAconsistBit : 56|1@0+ (1,0) [0|1] "" Vector__XXX

BO_ 1488 Radar2_Obj20_B: 8 Bosch_Radar2
 SG_ Radar2_Obj20_wClass : 55|5@0+ (0.03125,0) [0|0.96875] "" Vector__XXX
 SG_ Radar2_Obj20_dxRearEndLoss : 63|6@0+ (0.125,0) [0|7.875] "m" Vector__XXX
 SG_ Radar2_Obj20_dySigma : 45|6@0+ (0.0625,0) [0|3.9375] "m" Vector__XXX
 SG_ Radar2_Obj20_dLength : 13|6@0+ (0.125,0) [0|7.875] "m" Vector__XXX
 SG_ Radar2_Obj20_class : 50|3@0+ (1,0) [0|7] "" Vector__XXX
 SG_ Radar2_Obj20_dz : 23|6@0+ (0.25,-5) [-5|10.75] "m" Vector__XXX
 SG_ Radar2_Obj20_movingState : 17|2@0+ (1,0) [0|3] "" Vector__XXX
 SG_ Radar2_Obj20_vy : 7|10@0+ (0.125,-64) [-64|63.875] "m/s" Vector__XXX
 SG_ Radar2_Obj20_vxSigma : 25|6@0+ (0.0625,0) [0|3.9375] "m/s" Vector__XXX
 SG_ Radar2_Obj20_dxSigma : 31|6@0+ (0.0625,0) [0|3.9375] "m" Vector__XXX
 SG_ Radar2_Obj20_axSigma : 35|6@0+ (0.0625,0) [0|3.9375] "m/s2" Vector__XXX
 SG_ Radar2_Obj20_MessBconsistBit : 56|1@0+ (1,0) [0|1] "" Vector__XXX

BO_ 1497 Radar2_Obj21_A: 8 Bosch_Radar2
 SG_ Radar2_Obj21_wObstacle : 53|5@0+ (0.03125,0) [0|0.96875] "" Vector__XXX
 SG_ Radar2_Obj21_wNonObstacle : 63|5@0+ (0.03125,0) [0|0.96875] "" Vector__XXX
 SG_ Radar2_Obj21_wExist : 36|5@0+ (0.03125,0) [0|0.96875] "-" Vector__XXX
 SG_ Radar2_Obj21_ax : 47|10@0+ (0.03125,-16) [-16|15.96875] "m/s2" Vector__XXX
 SG_ Radar2_Obj21_vx : 11|12@0+ (0.0625,-128) [-128|127.9375] "m/s" Vector__XXX
 SG_ Radar2_Obj21_dy : 31|11@0+ (0.125,-128) [-128|127.875] "m" Vector__XXX
 SG_ Radar2_Obj21_dx : 7|12@0+ (0.0625,-128) [-128|127.9375] "m" Vector__XXX
 SG_ Radar2_Obj21_flagValid : 48|1@0+ (1,0) [0|1] "" Vector__XXX
 SG_ Radar2_Obj21_flagHist : 57|1@0+ (1,0) [0|1] "" Vector__XXX
 SG_ Radar2_Obj21_flagMeas : 58|1@0+ (1,0) [0|1] "" Vector__XXX
 SG_ Radar2_Obj21_MessAconsistBit : 56|1@0+ (1,0) [0|1] "" Vector__XXX

BO_ 1498 Radar2_Obj21_B: 8 Bosch_Radar2
 SG_ Radar2_Obj21_wClass : 55|5@0+ (0.03125,0) [0|0.96875] "" Vector__XXX
 SG_ Radar2_Obj21_dxRearEndLoss : 63|6@0+ (0.125,0) [0|7.875] "m" Vector__XXX
 SG_ Radar2_Obj21_dySigma : 45|6@0+ (0.0625,0) [0|3.9375] "m" Vector__XXX
 SG_ Radar2_Obj21_dLength : 13|6@0+ (0.125,0) [0|7.875] "m" Vector__XXX
 SG_ Radar2_Obj21_class : 50|3@0+ (1,0) [0|7] "" Vector__XXX
 SG_ Radar2_Obj21_dz : 23|6@0+ (0.25,-5) [-5|10.75] "m" Vector__XXX
 SG_ Radar2_Obj21_movingState : 17|2@0+ (1,0) [0|3] "" Vector__XXX
 SG_ Radar2_Obj21_vy : 7|10@0+ (0.125,-64) [-64|63.875] "m/s" Vector__XXX
 SG_ Radar2_Obj21_vxSigma : 25|6@0+ (0.0625,0) [0|3.9375] "m/s" Vector__XXX
 SG_ Radar2_Obj21_dxSigma : 31|6@0+ (0.0625,0) [0|3.9375] "m" Vector__XXX
 SG_ Radar2_Obj21_axSigma : 35|6@0+ (0.0625,0) [0|3.9375] "m/s2" Vector__XXX
 SG_ Radar2_Obj21_MessBconsistBit : 56|1@0+ (1,0) [0|1] "" Vector__XXX

BO_ 1507 Radar2_Obj22_A: 8 Bosch_Radar2
 SG_ Radar2_Obj22_wObstacle : 53|5@0+ (0.03125,0) [0|0.96875] "" Vector__XXX
 SG_ Radar2_Obj22_wNonObstacle : 63|5@0+ (0.03125,0) [0|0.96875] "" Vector__XXX
 SG_ Radar2_Obj22_wExist : 36|5@0+ (0.03125,0) [0|0.96875] "-" Vector__XXX
 SG_ Radar2_Obj22_ax : 47|10@0+ (0.03125,-16) [-16|15.96875] "m/s2" Vector__XXX
 SG_ Radar2_Obj22_vx : 11|12@0+ (0.0625,-128) [-128|127.9375] "m/s" Vector__XXX
 SG_ Radar2_Obj22_dy : 31|11@0+ (0.125,-128) [-128|127.875] "m" Vector__XXX
 SG_ Radar2_Obj22_dx : 7|12@0+ (0.0625,-128) [-128|127.9375] "m" Vector__XXX
 SG_ Radar2_Obj22_flagValid : 48|1@0+ (1,0) [0|1] "" Vector__XXX
 SG_ Radar2_Obj22_flagHist : 57|1@0+ (1,0) [0|1] "" Vector__XXX
 SG_ Radar2_Obj22_flagMeas : 58|1@0+ (1,0) [0|1] "" Vector__XXX
 SG_ Radar2_Obj22_MessAconsistBit : 56|1@0+ (1,0) [0|1] "" Vector__XXX

BO_ 1508 Radar2_Obj22_B: 8 Bosch_Radar2
 SG_ Radar2_Obj22_wClass : 55|5@0+ (0.03125,0) [0|0.96875] "" Vector__XXX
 SG_ Radar2_Obj22_dxRearEndLoss : 63|6@0+ (0.125,0) [0|7.875] "m" Vector__XXX
 SG_ Radar2_Obj22_dySigma : 45|6@0+ (0.0625,0) [0|3.9375] "m" Vector__XXX
 SG_ Radar2_Obj22_dLength : 13|6@0+ (0.125,0) [0|7.875] "m" Vector__XXX
 SG_ Radar2_Obj22_class : 50|3@0+ (1,0) [0|7] "" Vector__XXX
 SG_ Radar2_Obj22_dz : 23|6@0+ (0.25,-5) [-5|10.75] "m" Vector__XXX
 SG_ Radar2_Obj22_movingState : 17|2@0+ (1,0) [0|3] "" Vector__XXX
 SG_ Radar2_Obj22_vy : 7|10@0+ (0.125,-64) [-64|63.875] "m/s" Vector__XXX
 SG_ Radar2_Obj22_vxSigma : 25|6@0+ (0.0625,0) [0|3.9375] "m/s" Vector__XXX
 SG_ Radar2_Obj22_dxSigma : 31|6@0+ (0.0625,0) [0|3.9375] "m" Vector__XXX
 SG_ Radar2_Obj22_axSigma : 35|6@0+ (0.0625,0) [0|3.9375] "m/s2" Vector__XXX
 SG_ Radar2_Obj22_MessBconsistBit : 56|1@0+ (1,0) [0|1] "" Vector__XXX

BO_ 1517 Radar2_Obj23_A: 8 Bosch_Radar2
 SG_ Radar2_Obj23_wObstacle : 53|5@0+ (0.03125,0) [0|0.96875] "" Vector__XXX
 SG_ Radar2_Obj23_wNonObstacle : 63|5@0+ (0.03125,0) [0|0.96875] "" Vector__XXX
 SG_ Radar2_Obj23_wExist : 36|5@0+ (0.03125,0) [0|0.96875] "-" Vector__XXX
 SG_ Radar2_Obj23_ax : 47|10@0+ (0.03125,-16) [-16|15.96875] "m/s2" Vector__XXX
 SG_ Radar2_Obj23_vx : 11|12@0+ (0.0625,-128) [-128|127.9375] "m/s" Vector__XXX
 SG_ Radar2_Obj23_dy : 31|11@0+ (0.125,-128) [-128|127.875] "m" Vector__XXX
 SG_ Radar2_Obj23_dx : 7|12@0+ (0.0625,-128) [-128|127.9375] "m" Vector__XXX
 SG_ Radar2_Obj23_flagValid : 48|1@0+ (1,0) [0|1] "" Vector__XXX
 SG_ Radar2_Obj23_flagHist : 57|1@0+ (1,0) [0|1] "" Vector__XXX
 SG_ Radar2_Obj23_flagMeas : 58|1@0+ (1,0) [0|1] "" Vector__XXX
 SG_ Radar2_Obj23_MessAconsistBit : 56|1@0+ (1,0) [0|1] "" Vector__XXX

BO_ 1518 Radar2_Obj23_B: 8 Bosch_Radar2
 SG_ Radar2_Obj23_wClass : 55|5@0+ (0.03125,0) [0|0.96875] "" Vector__XXX
 SG_ Radar2_Obj23_dxRearEndLoss : 63|6@0+ (0.125,0) [0|7.875] "m" Vector__XXX
 SG_ Radar2_Obj23_dySigma : 45|6@0+ (0.0625,0) [0|3.9375] "m" Vector__XXX
 SG_ Radar2_Obj23_dLength : 13|6@0+ (0.125,0) [0|7.875] "m" Vector__XXX
 SG_ Radar2_Obj23_class : 50|3@0+ (1,0) [0|7] "" Vector__XXX
 SG_ Radar2_Obj23_dz : 23|6@0+ (0.25,-5) [-5|10.75] "m" Vector__XXX
 SG_ Radar2_Obj23_movingState : 17|2@0+ (1,0) [0|3] "" Vector__XXX
 SG_ Radar2_Obj23_vy : 7|10@0+ (0.125,-64) [-64|63.875] "m/s" Vector__XXX
 SG_ Radar2_Obj23_vxSigma : 25|6@0+ (0.0625,0) [0|3.9375] "m/s" Vector__XXX
 SG_ Radar2_Obj23_dxSigma : 31|6@0+ (0.0625,0) [0|3.9375] "m" Vector__XXX
 SG_ Radar2_Obj23_axSigma : 35|6@0+ (0.0625,0) [0|3.9375] "m/s2" Vector__XXX
 SG_ Radar2_Obj23_MessBconsistBit : 56|1@0+ (1,0) [0|1] "" Vector__XXX

BO_ 1527 Radar2_Obj24_A: 8 Bosch_Radar2
 SG_ Radar2_Obj24_wObstacle : 53|5@0+ (0.03125,0) [0|0.96875] "" Vector__XXX
 SG_ Radar2_Obj24_wNonObstacle : 63|5@0+ (0.03125,0) [0|0.96875] "" Vector__XXX
 SG_ Radar2_Obj24_wExist : 36|5@0+ (0.03125,0) [0|0.96875] "-" Vector__XXX
 SG_ Radar2_Obj24_ax : 47|10@0+ (0.03125,-16) [-16|15.96875] "m/s2" Vector__XXX
 SG_ Radar2_Obj24_vx : 11|12@0+ (0.0625,-128) [-128|127.9375] "m/s" Vector__XXX
 SG_ Radar2_Obj24_dy : 31|11@0+ (0.125,-128) [-128|127.875] "m" Vector__XXX
 SG_ Radar2_Obj24_dx : 7|12@0+ (0.0625,-128) [-128|127.9375] "m" Vector__XXX
 SG_ Radar2_Obj24_flagValid : 48|1@0+ (1,0) [0|1] "" Vector__XXX
 SG_ Radar2_Obj24_flagHist : 57|1@0+ (1,0) [0|1] "" Vector__XXX
 SG_ Radar2_Obj24_flagMeas : 58|1@0+ (1,0) [0|1] "" Vector__XXX
 SG_ Radar2_Obj24_MessAconsistBit : 56|1@0+ (1,0) [0|1] "" Vector__XXX

BO_ 1528 Radar2_Obj24_B: 8 Bosch_Radar2
 SG_ Radar2_Obj24_wClass : 55|5@0+ (0.03125,0) [0|0.96875] "" Vector__XXX
 SG_ Radar2_Obj24_dxRearEndLoss : 63|6@0+ (0.125,0) [0|7.875] "m" Vector__XXX
 SG_ Radar2_Obj24_dySigma : 45|6@0+ (0.0625,0) [0|3.9375] "m" Vector__XXX
 SG_ Radar2_Obj24_dLength : 13|6@0+ (0.125,0) [0|7.875] "m" Vector__XXX
 SG_ Radar2_Obj24_class : 50|3@0+ (1,0) [0|7] "" Vector__XXX
 SG_ Radar2_Obj24_dz : 23|6@0+ (0.25,-5) [-5|10.75] "m" Vector__XXX
 SG_ Radar2_Obj24_movingState : 17|2@0+ (1,0) [0|3] "" Vector__XXX
 SG_ Radar2_Obj24_vy : 7|10@0+ (0.125,-64) [-64|63.875] "m/s" Vector__XXX
 SG_ Radar2_Obj24_vxSigma : 25|6@0+ (0.0625,0) [0|3.9375] "m/s" Vector__XXX
 SG_ Radar2_Obj24_dxSigma : 31|6@0+ (0.0625,0) [0|3.9375] "m" Vector__XXX
 SG_ Radar2_Obj24_axSigma : 35|6@0+ (0.0625,0) [0|3.9375] "m/s2" Vector__XXX
 SG_ Radar2_Obj24_MessBconsistBit : 56|1@0+ (1,0) [0|1] "" Vector__XXX

BO_ 1537 Radar2_Obj25_A: 8 Bosch_Radar2
 SG_ Radar2_Obj25_wObstacle : 53|5@0+ (0.03125,0) [0|0.96875] "" Vector__XXX
 SG_ Radar2_Obj25_wNonObstacle : 63|5@0+ (0.03125,0) [0|0.96875] "" Vector__XXX
 SG_ Radar2_Obj25_wExist : 36|5@0+ (0.03125,0) [0|0.96875] "-" Vector__XXX
 SG_ Radar2_Obj25_ax : 47|10@0+ (0.03125,-16) [-16|15.96875] "m/s2" Vector__XXX
 SG_ Radar2_Obj25_vx : 11|12@0+ (0.0625,-128) [-128|127.9375] "m/s" Vector__XXX
 SG_ Radar2_Obj25_dy : 31|11@0+ (0.125,-128) [-128|127.875] "m" Vector__XXX
 SG_ Radar2_Obj25_dx : 7|12@0+ (0.0625,-128) [-128|127.9375] "m" Vector__XXX
 SG_ Radar2_Obj25_flagValid : 48|1@0+ (1,0) [0|1] "" Vector__XXX
 SG_ Radar2_Obj25_flagHist : 57|1@0+ (1,0) [0|1] "" Vector__XXX
 SG_ Radar2_Obj25_flagMeas : 58|1@0+ (1,0) [0|1] "" Vector__XXX
 SG_ Radar2_Obj25_MessAconsistBit : 56|1@0+ (1,0) [0|1] "" Vector__XXX

BO_ 1538 Radar2_Obj25_B: 8 Bosch_Radar2
 SG_ Radar2_Obj25_wClass : 55|5@0+ (0.03125,0) [0|0.96875] "" Vector__XXX
 SG_ Radar2_Obj25_dxRearEndLoss : 63|6@0+ (0.125,0) [0|7.875] "m" Vector__XXX
 SG_ Radar2_Obj25_dySigma : 45|6@0+ (0.0625,0) [0|3.9375] "m" Vector__XXX
 SG_ Radar2_Obj25_dLength : 13|6@0+ (0.125,0) [0|7.875] "m" Vector__XXX
 SG_ Radar2_Obj25_class : 50|3@0+ (1,0) [0|7] "" Vector__XXX
 SG_ Radar2_Obj25_dz : 23|6@0+ (0.25,-5) [-5|10.75] "m" Vector__XXX
 SG_ Radar2_Obj25_movingState : 17|2@0+ (1,0) [0|3] "" Vector__XXX
 SG_ Radar2_Obj25_vy : 7|10@0+ (0.125,-64) [-64|63.875] "m/s" Vector__XXX
 SG_ Radar2_Obj25_vxSigma : 25|6@0+ (0.0625,0) [0|3.9375] "m/s" Vector__XXX
 SG_ Radar2_Obj25_dxSigma : 31|6@0+ (0.0625,0) [0|3.9375] "m" Vector__XXX
 SG_ Radar2_Obj25_axSigma : 35|6@0+ (0.0625,0) [0|3.9375] "m/s2" Vector__XXX
 SG_ Radar2_Obj25_MessBconsistBit : 56|1@0+ (1,0) [0|1] "" Vector__XXX

BO_ 1547 Radar2_Obj26_A: 8 Bosch_Radar2
 SG_ Radar2_Obj26_wObstacle : 53|5@0+ (0.03125,0) [0|0.96875] "" Vector__XXX
 SG_ Radar2_Obj26_wNonObstacle : 63|5@0+ (0.03125,0) [0|0.96875] "" Vector__XXX
 SG_ Radar2_Obj26_wExist : 36|5@0+ (0.03125,0) [0|0.96875] "-" Vector__XXX
 SG_ Radar2_Obj26_ax : 47|10@0+ (0.03125,-16) [-16|15.96875] "m/s2" Vector__XXX
 SG_ Radar2_Obj26_vx : 11|12@0+ (0.0625,-128) [-128|127.9375] "m/s" Vector__XXX
 SG_ Radar2_Obj26_dy : 31|11@0+ (0.125,-128) [-128|127.875] "m" Vector__XXX
 SG_ Radar2_Obj26_dx : 7|12@0+ (0.0625,-128) [-128|127.9375] "m" Vector__XXX
 SG_ Radar2_Obj26_flagValid : 48|1@0+ (1,0) [0|1] "" Vector__XXX
 SG_ Radar2_Obj26_flagHist : 57|1@0+ (1,0) [0|1] "" Vector__XXX
 SG_ Radar2_Obj26_flagMeas : 58|1@0+ (1,0) [0|1] "" Vector__XXX
 SG_ Radar2_Obj26_MessAconsistBit : 56|1@0+ (1,0) [0|1] "" Vector__XXX

BO_ 1548 Radar2_Obj26_B: 8 Bosch_Radar2
 SG_ Radar2_Obj26_wClass : 55|5@0+ (0.03125,0) [0|0.96875] "" Vector__XXX
 SG_ Radar2_Obj26_dxRearEndLoss : 63|6@0+ (0.125,0) [0|7.875] "m" Vector__XXX
 SG_ Radar2_Obj26_dySigma : 45|6@0+ (0.0625,0) [0|3.9375] "m" Vector__XXX
 SG_ Radar2_Obj26_dLength : 13|6@0+ (0.125,0) [0|7.875] "m" Vector__XXX
 SG_ Radar2_Obj26_class : 50|3@0+ (1,0) [0|7] "" Vector__XXX
 SG_ Radar2_Obj26_dz : 23|6@0+ (0.25,-5) [-5|10.75] "m" Vector__XXX
 SG_ Radar2_Obj26_movingState : 17|2@0+ (1,0) [0|3] "" Vector__XXX
 SG_ Radar2_Obj26_vy : 7|10@0+ (0.125,-64) [-64|63.875] "m/s" Vector__XXX
 SG_ Radar2_Obj26_vxSigma : 25|6@0+ (0.0625,0) [0|3.9375] "m/s" Vector__XXX
 SG_ Radar2_Obj26_dxSigma : 31|6@0+ (0.0625,0) [0|3.9375] "m" Vector__XXX
 SG_ Radar2_Obj26_axSigma : 35|6@0+ (0.0625,0) [0|3.9375] "m/s2" Vector__XXX
 SG_ Radar2_Obj26_MessBconsistBit : 56|1@0+ (1,0) [0|1] "" Vector__XXX

BO_ 1557 Radar2_Obj27_A: 8 Bosch_Radar2
 SG_ Radar2_Obj27_wObstacle : 53|5@0+ (0.03125,0) [0|0.96875] "" Vector__XXX
 SG_ Radar2_Obj27_wNonObstacle : 63|5@0+ (0.03125,0) [0|0.96875] "" Vector__XXX
 SG_ Radar2_Obj27_wExist : 36|5@0+ (0.03125,0) [0|0.96875] "-" Vector__XXX
 SG_ Radar2_Obj27_ax : 47|10@0+ (0.03125,-16) [-16|15.96875] "m/s2" Vector__XXX
 SG_ Radar2_Obj27_vx : 11|12@0+ (0.0625,-128) [-128|127.9375] "m/s" Vector__XXX
 SG_ Radar2_Obj27_dy : 31|11@0+ (0.125,-128) [-128|127.875] "m" Vector__XXX
 SG_ Radar2_Obj27_dx : 7|12@0+ (0.0625,-128) [-128|127.9375] "m" Vector__XXX
 SG_ Radar2_Obj27_flagValid : 48|1@0+ (1,0) [0|1] "" Vector__XXX
 SG_ Radar2_Obj27_flagHist : 57|1@0+ (1,0) [0|1] "" Vector__XXX
 SG_ Radar2_Obj27_flagMeas : 58|1@0+ (1,0) [0|1] "" Vector__XXX
 SG_ Radar2_Obj27_MessAconsistBit : 56|1@0+ (1,0) [0|1] "" Vector__XXX

BO_ 1558 Radar2_Obj27_B: 8 Bosch_Radar2
 SG_ Radar2_Obj27_wClass : 55|5@0+ (0.03125,0) [0|0.96875] "" Vector__XXX
 SG_ Radar2_Obj27_dxRearEndLoss : 63|6@0+ (0.125,0) [0|7.875] "m" Vector__XXX
 SG_ Radar2_Obj27_dySigma : 45|6@0+ (0.0625,0) [0|3.9375] "m" Vector__XXX
 SG_ Radar2_Obj27_dLength : 13|6@0+ (0.125,0) [0|7.875] "m" Vector__XXX
 SG_ Radar2_Obj27_class : 50|3@0+ (1,0) [0|7] "" Vector__XXX
 SG_ Radar2_Obj27_dz : 23|6@0+ (0.25,-5) [-5|10.75] "m" Vector__XXX
 SG_ Radar2_Obj27_movingState : 17|2@0+ (1,0) [0|3] "" Vector__XXX
 SG_ Radar2_Obj27_vy : 7|10@0+ (0.125,-64) [-64|63.875] "m/s" Vector__XXX
 SG_ Radar2_Obj27_vxSigma : 25|6@0+ (0.0625,0) [0|3.9375] "m/s" Vector__XXX
 SG_ Radar2_Obj27_dxSigma : 31|6@0+ (0.0625,0) [0|3.9375] "m" Vector__XXX
 SG_ Radar2_Obj27_axSigma : 35|6@0+ (0.0625,0) [0|3.9375] "m/s2" Vector__XXX
 SG_ Radar2_Obj27_MessBconsistBit : 56|1@0+ (1,0) [0|1] "" Vector__XXX

BO_ 1567 Radar2_Obj28_A: 8 Bosch_Radar2
 SG_ Radar2_Obj28_wObstacle : 53|5@0+ (0.03125,0) [0|0.96875] "" Vector__XXX
 SG_ Radar2_Obj28_wNonObstacle : 63|5@0+ (0.03125,0) [0|0.96875] "" Vector__XXX
 SG_ Radar2_Obj28_wExist : 36|5@0+ (0.03125,0) [0|0.96875] "-" Vector__XXX
 SG_ Radar2_Obj28_ax : 47|10@0+ (0.03125,-16) [-16|15.96875] "m/s2" Vector__XXX
 SG_ Radar2_Obj28_vx : 11|12@0+ (0.0625,-128) [-128|127.9375] "m/s" Vector__XXX
 SG_ Radar2_Obj28_dy : 31|11@0+ (0.125,-128) [-128|127.875] "m" Vector__XXX
 SG_ Radar2_Obj28_dx : 7|12@0+ (0.0625,-128) [-128|127.9375] "m" Vector__XXX
 SG_ Radar2_Obj28_flagValid : 48|1@0+ (1,0) [0|1] "" Vector__XXX
 SG_ Radar2_Obj28_flagHist : 57|1@0+ (1,0) [0|1] "" Vector__XXX
 SG_ Radar2_Obj28_flagMeas : 58|1@0+ (1,0) [0|1] "" Vector__XXX
 SG_ Radar2_Obj28_MessAconsistBit : 56|1@0+ (1,0) [0|1] "" Vector__XXX

BO_ 1568 Radar2_Obj28_B: 8 Bosch_Radar2
 SG_ Radar2_Obj28_wClass : 55|5@0+ (0.03125,0) [0|0.96875] "" Vector__XXX
 SG_ Radar2_Obj28_dxRearEndLoss : 63|6@0+ (0.125,0) [0|7.875] "m" Vector__XXX
 SG_ Radar2_Obj28_dySigma : 45|6@0+ (0.0625,0) [0|3.9375] "m" Vector__XXX
 SG_ Radar2_Obj28_dLength : 13|6@0+ (0.125,0) [0|7.875] "m" Vector__XXX
 SG_ Radar2_Obj28_class : 50|3@0+ (1,0) [0|7] "" Vector__XXX
 SG_ Radar2_Obj28_dz : 23|6@0+ (0.25,-5) [-5|10.75] "m" Vector__XXX
 SG_ Radar2_Obj28_movingState : 17|2@0+ (1,0) [0|3] "" Vector__XXX
 SG_ Radar2_Obj28_vy : 7|10@0+ (0.125,-64) [-64|63.875] "m/s" Vector__XXX
 SG_ Radar2_Obj28_vxSigma : 25|6@0+ (0.0625,0) [0|3.9375] "m/s" Vector__XXX
 SG_ Radar2_Obj28_dxSigma : 31|6@0+ (0.0625,0) [0|3.9375] "m" Vector__XXX
 SG_ Radar2_Obj28_axSigma : 35|6@0+ (0.0625,0) [0|3.9375] "m/s2" Vector__XXX
 SG_ Radar2_Obj28_MessBconsistBit : 56|1@0+ (1,0) [0|1] "" Vector__XXX

BO_ 1577 Radar2_Obj29_A: 8 Bosch_Radar2
 SG_ Radar2_Obj29_wObstacle : 53|5@0+ (0.03125,0) [0|0.96875] "" Vector__XXX
 SG_ Radar2_Obj29_wNonObstacle : 63|5@0+ (0.03125,0) [0|0.96875] "" Vector__XXX
 SG_ Radar2_Obj29_wExist : 36|5@0+ (0.03125,0) [0|0.96875] "-" Vector__XXX
 SG_ Radar2_Obj29_ax : 47|10@0+ (0.03125,-16) [-16|15.96875] "m/s2" Vector__XXX
 SG_ Radar2_Obj29_vx : 11|12@0+ (0.0625,-128) [-128|127.9375] "m/s" Vector__XXX
 SG_ Radar2_Obj29_dy : 31|11@0+ (0.125,-128) [-128|127.875] "m" Vector__XXX
 SG_ Radar2_Obj29_dx : 7|12@0+ (0.0625,-128) [-128|127.9375] "m" Vector__XXX
 SG_ Radar2_Obj29_flagValid : 48|1@0+ (1,0) [0|1] "" Vector__XXX
 SG_ Radar2_Obj29_flagHist : 57|1@0+ (1,0) [0|1] "" Vector__XXX
 SG_ Radar2_Obj29_flagMeas : 58|1@0+ (1,0) [0|1] "" Vector__XXX
 SG_ Radar2_Obj29_MessAconsistBit : 56|1@0+ (1,0) [0|1] "" Vector__XXX

BO_ 1578 Radar2_Obj29_B: 8 Bosch_Radar2
 SG_ Radar2_Obj29_wClass : 55|5@0+ (0.03125,0) [0|0.96875] "" Vector__XXX
 SG_ Radar2_Obj29_dxRearEndLoss : 63|6@0+ (0.125,0) [0|7.875] "m" Vector__XXX
 SG_ Radar2_Obj29_dySigma : 45|6@0+ (0.0625,0) [0|3.9375] "m" Vector__XXX
 SG_ Radar2_Obj29_dLength : 13|6@0+ (0.125,0) [0|7.875] "m" Vector__XXX
 SG_ Radar2_Obj29_class : 50|3@0+ (1,0) [0|7] "" Vector__XXX
 SG_ Radar2_Obj29_dz : 23|6@0+ (0.25,-5) [-5|10.75] "m" Vector__XXX
 SG_ Radar2_Obj29_movingState : 17|2@0+ (1,0) [0|3] "" Vector__XXX
 SG_ Radar2_Obj29_vy : 7|10@0+ (0.125,-64) [-64|63.875] "m/s" Vector__XXX
 SG_ Radar2_Obj29_vxSigma : 25|6@0+ (0.0625,0) [0|3.9375] "m/s" Vector__XXX
 SG_ Radar2_Obj29_dxSigma : 31|6@0+ (0.0625,0) [0|3.9375] "m" Vector__XXX
 SG_ Radar2_Obj29_axSigma : 35|6@0+ (0.0625,0) [0|3.9375] "m/s2" Vector__XXX
 SG_ Radar2_Obj29_MessBconsistBit : 56|1@0+ (1,0) [0|1] "" Vector__XXX

BO_ 1587 Radar2_Obj30_A: 8 Bosch_Radar2
 SG_ Radar2_Obj30_wObstacle : 53|5@0+ (0.03125,0) [0|0.96875] "" Vector__XXX
 SG_ Radar2_Obj30_wNonObstacle : 63|5@0+ (0.03125,0) [0|0.96875] "" Vector__XXX
 SG_ Radar2_Obj30_wExist : 36|5@0+ (0.03125,0) [0|0.96875] "-" Vector__XXX
 SG_ Radar2_Obj30_ax : 47|10@0+ (0.03125,-16) [-16|15.96875] "m/s2" Vector__XXX
 SG_ Radar2_Obj30_vx : 11|12@0+ (0.0625,-128) [-128|127.9375] "m/s" Vector__XXX
 SG_ Radar2_Obj30_dy : 31|11@0+ (0.125,-128) [-128|127.875] "m" Vector__XXX
 SG_ Radar2_Obj30_dx : 7|12@0+ (0.0625,-128) [-128|127.9375] "m" Vector__XXX
 SG_ Radar2_Obj30_flagValid : 48|1@0+ (1,0) [0|1] "" Vector__XXX
 SG_ Radar2_Obj30_flagHist : 57|1@0+ (1,0) [0|1] "" Vector__XXX
 SG_ Radar2_Obj30_flagMeas : 58|1@0+ (1,0) [0|1] "" Vector__XXX
 SG_ Radar2_Obj30_MessAconsistBit : 56|1@0+ (1,0) [0|1] "" Vector__XXX

BO_ 1588 Radar2_Obj30_B: 8 Bosch_Radar2
 SG_ Radar2_Obj30_wClass : 55|5@0+ (0.03125,0) [0|0.96875] "" Vector__XXX
 SG_ Radar2_Obj30_dxRearEndLoss : 63|6@0+ (0.125,0) [0|7.875] "m" Vector__XXX
 SG_ Radar2_Obj30_dySigma : 45|6@0+ (0.0625,0) [0|3.9375] "m" Vector__XXX
 SG_ Radar2_Obj30_dLength : 13|6@0+ (0.125,0) [0|7.875] "m" Vector__XXX
 SG_ Radar2_Obj30_class : 50|3@0+ (1,0) [0|7] "" Vector__XXX
 SG_ Radar2_Obj30_dz : 23|6@0+ (0.25,-5) [-5|10.75] "m" Vector__XXX
 SG_ Radar2_Obj30_movingState : 17|2@0+ (1,0) [0|3] "" Vector__XXX
 SG_ Radar2_Obj30_vy : 7|10@0+ (0.125,-64) [-64|63.875] "m/s" Vector__XXX
 SG_ Radar2_Obj30_vxSigma : 25|6@0+ (0.0625,0) [0|3.9375] "m/s" Vector__XXX
 SG_ Radar2_Obj30_dxSigma : 31|6@0+ (0.0625,0) [0|3.9375] "m" Vector__XXX
 SG_ Radar2_Obj30_axSigma : 35|6@0+ (0.0625,0) [0|3.9375] "m/s2" Vector__XXX
 SG_ Radar2_Obj30_MessBconsistBit : 56|1@0+ (1,0) [0|1] "" Vector__XXX

BO_ 1597 Radar2_Obj31_A: 8 Bosch_Radar2
 SG_ Radar2_Obj31_wObstacle : 53|5@0+ (0.03125,0) [0|0.96875] "" Vector__XXX
 SG_ Radar2_Obj31_wNonObstacle : 63|5@0+ (0.03125,0) [0|0.96875] "" Vector__XXX
 SG_ Radar2_Obj31_wExist : 36|5@0+ (0.03125,0) [0|0.96875] "-" Vector__XXX
 SG_ Radar2_Obj31_ax : 47|10@0+ (0.03125,-16) [-16|15.96875] "m/s2" Vector__XXX
 SG_ Radar2_Obj31_vx : 11|12@0+ (0.0625,-128) [-128|127.9375] "m/s" Vector__XXX
 SG_ Radar2_Obj31_dy : 31|11@0+ (0.125,-128) [-128|127.875] "m" Vector__XXX
 SG_ Radar2_Obj31_dx : 7|12@0+ (0.0625,-128) [-128|127.9375] "m" Vector__XXX
 SG_ Radar2_Obj31_flagValid : 48|1@0+ (1,0) [0|1] "" Vector__XXX
 SG_ Radar2_Obj31_flagHist : 57|1@0+ (1,0) [0|1] "" Vector__XXX
 SG_ Radar2_Obj31_flagMeas : 58|1@0+ (1,0) [0|1] "" Vector__XXX
 SG_ Radar2_Obj31_MessAconsistBit : 56|1@0+ (1,0) [0|1] "" Vector__XXX

BO_ 1598 Radar2_Obj31_B: 8 Bosch_Radar2
 SG_ Radar2_Obj31_wClass : 55|5@0+ (0.03125,0) [0|0.96875] "" Vector__XXX
 SG_ Radar2_Obj31_dxRearEndLoss : 63|6@0+ (0.125,0) [0|7.875] "m" Vector__XXX
 SG_ Radar2_Obj31_dySigma : 45|6@0+ (0.0625,0) [0|3.9375] "m" Vector__XXX
 SG_ Radar2_Obj31_dLength : 13|6@0+ (0.125,0) [0|7.875] "m" Vector__XXX
 SG_ Radar2_Obj31_class : 50|3@0+ (1,0) [0|7] "" Vector__XXX
 SG_ Radar2_Obj31_dz : 23|6@0+ (0.25,-5) [-5|10.75] "m" Vector__XXX
 SG_ Radar2_Obj31_movingState : 17|2@0+ (1,0) [0|3] "" Vector__XXX
 SG_ Radar2_Obj31_vy : 7|10@0+ (0.125,-64) [-64|63.875] "m/s" Vector__XXX
 SG_ Radar2_Obj31_vxSigma : 25|6@0+ (0.0625,0) [0|3.9375] "m/s" Vector__XXX
 SG_ Radar2_Obj31_dxSigma : 31|6@0+ (0.0625,0) [0|3.9375] "m" Vector__XXX
 SG_ Radar2_Obj31_axSigma : 35|6@0+ (0.0625,0) [0|3.9375] "m/s2" Vector__XXX
 SG_ Radar2_Obj31_MessBconsistBit : 56|1@0+ (1,0) [0|1] "" Vector__XXX

BO_ 1607 Radar2_Target00_A: 8 Bosch_Radar2
 SG_ Radar2_Target00_wObstacle : 53|5@0+ (0.03125,0) [0|0.96875] "" Vector__XXX
 SG_ Radar2_Target00_wNonObstacle : 63|5@0+ (0.03125,0) [0|0.96875] "" Vector__XXX
 SG_ Radar2_Target00_wExist : 36|5@0+ (0.03125,0) [0|0.96875] "-" Vector__XXX
 SG_ Radar2_Target00_ax : 47|10@0+ (0.03125,-16) [-16|15.96875] "m/s2" Vector__XXX
 SG_ Radar2_Target00_vx : 11|12@0+ (0.0625,-128) [-128|127.9375] "m/s" Vector__XXX
 SG_ Radar2_Target00_dy : 31|11@0+ (0.125,-128) [-128|127.875] "m" Vector__XXX
 SG_ Radar2_Target00_dx : 7|12@0+ (0.0625,-128) [-128|127.9375] "m" Vector__XXX
 SG_ Radar2_Target00_flagValid : 48|1@0+ (1,0) [0|1] "" Vector__XXX
 SG_ Radar2_Target00_flagHist : 57|1@0+ (1,0) [0|1] "" Vector__XXX
 SG_ Radar2_Target00_flagMeas : 58|1@0+ (1,0) [0|1] "" Vector__XXX
 SG_ Radar2_Target00_MessAconsistBit : 56|1@0+ (1,0) [0|1] "" Vector__XXX

BO_ 1608 Radar2_Target00_B: 8 Bosch_Radar2
 SG_ Radar2_Target00_wClass : 55|5@0+ (0.03125,0) [0|0.96875] "" Vector__XXX
 SG_ Radar2_Target00_dxRearEndLoss : 63|6@0+ (0.125,0) [0|7.875] "m" Vector__XXX
 SG_ Radar2_Target00_dySigma : 45|6@0+ (0.0625,0) [0|3.9375] "m" Vector__XXX
 SG_ Radar2_Target00_dLength : 13|6@0+ (0.125,0) [0|7.875] "m" Vector__XXX
 SG_ Radar2_Target00_class : 50|3@0+ (1,0) [0|7] "" Vector__XXX
 SG_ Radar2_Target00_dz : 23|6@0+ (0.25,-5) [-5|10.75] "m" Vector__XXX
 SG_ Radar2_Target00_movingState : 17|2@0+ (1,0) [0|3] "" Vector__XXX
 SG_ Radar2_Target00_vy : 7|10@0+ (0.125,-64) [-64|63.875] "m/s" Vector__XXX
 SG_ Radar2_Target00_vxSigma : 25|6@0+ (0.0625,0) [0|3.9375] "m/s" Vector__XXX
 SG_ Radar2_Target00_dxSigma : 31|6@0+ (0.0625,0) [0|3.9375] "m" Vector__XXX
 SG_ Radar2_Target00_axSigma : 35|6@0+ (0.0625,0) [0|3.9375] "m/s2" Vector__XXX
 SG_ Radar2_Target00_MessBconsistBit : 56|1@0+ (1,0) [0|1] "" Vector__XXX

BO_ 1617 Radar2_Target01_A: 8 Bosch_Radar2
 SG_ Radar2_Target01_wObstacle : 53|5@0+ (0.03125,0) [0|0.96875] "" Vector__XXX
 SG_ Radar2_Target01_wNonObstacle : 63|5@0+ (0.03125,0) [0|0.96875] "" Vector__XXX
 SG_ Radar2_Target01_wExist : 36|5@0+ (0.03125,0) [0|0.96875] "-" Vector__XXX
 SG_ Radar2_Target01_ax : 47|10@0+ (0.03125,-16) [-16|15.96875] "m/s2" Vector__XXX
 SG_ Radar2_Target01_vx : 11|12@0+ (0.0625,-128) [-128|127.9375] "m/s" Vector__XXX
 SG_ Radar2_Target01_dy : 31|11@0+ (0.125,-128) [-128|127.875] "m" Vector__XXX
 SG_ Radar2_Target01_dx : 7|12@0+ (0.0625,-128) [-128|127.9375] "m" Vector__XXX
 SG_ Radar2_Target01_flagValid : 48|1@0+ (1,0) [0|1] "" Vector__XXX
 SG_ Radar2_Target01_flagHist : 57|1@0+ (1,0) [0|1] "" Vector__XXX
 SG_ Radar2_Target01_flagMeas : 58|1@0+ (1,0) [0|1] "" Vector__XXX
 SG_ Radar2_Target01_MessAconsistBit : 56|1@0+ (1,0) [0|1] "" Vector__XXX

BO_ 1618 Radar2_Target01_B: 8 Bosch_Radar2
 SG_ Radar2_Target01_wClass : 55|5@0+ (0.03125,0) [0|0.96875] "" Vector__XXX
 SG_ Radar2_Target01_dxRearEndLoss : 63|6@0+ (0.125,0) [0|7.875] "m" Vector__XXX
 SG_ Radar2_Target01_dySigma : 45|6@0+ (0.0625,0) [0|3.9375] "m" Vector__XXX
 SG_ Radar2_Target01_dLength : 13|6@0+ (0.125,0) [0|7.875] "m" Vector__XXX
 SG_ Radar2_Target01_class : 50|3@0+ (1,0) [0|7] "" Vector__XXX
 SG_ Radar2_Target01_dz : 23|6@0+ (0.25,-5) [-5|10.75] "m" Vector__XXX
 SG_ Radar2_Target01_movingState : 17|2@0+ (1,0) [0|3] "" Vector__XXX
 SG_ Radar2_Target01_vy : 7|10@0+ (0.125,-64) [-64|63.875] "m/s" Vector__XXX
 SG_ Radar2_Target01_vxSigma : 25|6@0+ (0.0625,0) [0|3.9375] "m/s" Vector__XXX
 SG_ Radar2_Target01_dxSigma : 31|6@0+ (0.0625,0) [0|3.9375] "m" Vector__XXX
 SG_ Radar2_Target01_axSigma : 35|6@0+ (0.0625,0) [0|3.9375] "m/s2" Vector__XXX
 SG_ Radar2_Target01_MessBconsistBit : 56|1@0+ (1,0) [0|1] "" Vector__XXX

BO_ 1627 Radar2_Target02_A: 8 Bosch_Radar2
 SG_ Radar2_Target02_wObstacle : 53|5@0+ (0.03125,0) [0|0.96875] "" Vector__XXX
 SG_ Radar2_Target02_wNonObstacle : 63|5@0+ (0.03125,0) [0|0.96875] "" Vector__XXX
 SG_ Radar2_Target02_wExist : 36|5@0+ (0.03125,0) [0|0.96875] "-" Vector__XXX
 SG_ Radar2_Target02_ax : 47|10@0+ (0.03125,-16) [-16|15.96875] "m/s2" Vector__XXX
 SG_ Radar2_Target02_vx : 11|12@0+ (0.0625,-128) [-128|127.9375] "m/s" Vector__XXX
 SG_ Radar2_Target02_dy : 31|11@0+ (0.125,-128) [-128|127.875] "m" Vector__XXX
 SG_ Radar2_Target02_dx : 7|12@0+ (0.0625,-128) [-128|127.9375] "m" Vector__XXX
 SG_ Radar2_Target02_flagValid : 48|1@0+ (1,0) [0|1] "" Vector__XXX
 SG_ Radar2_Target02_flagHist : 57|1@0+ (1,0) [0|1] "" Vector__XXX
 SG_ Radar2_Target02_flagMeas : 58|1@0+ (1,0) [0|1] "" Vector__XXX
 SG_ Radar2_Target02_MessAconsistBit : 56|1@0+ (1,0) [0|1] "" Vector__XXX

BO_ 1628 Radar2_Target02_B: 8 Bosch_Radar2
 SG_ Radar2_Target02_wClass : 55|5@0+ (0.03125,0) [0|0.96875] "" Vector__XXX
 SG_ Radar2_Target02_dxRearEndLoss : 63|6@0+ (0.125,0) [0|7.875] "m" Vector__XXX
 SG_ Radar2_Target02_dySigma : 45|6@0+ (0.0625,0) [0|3.9375] "m" Vector__XXX
 SG_ Radar2_Target02_dLength : 13|6@0+ (0.125,0) [0|7.875] "m" Vector__XXX
 SG_ Radar2_Target02_class : 50|3@0+ (1,0) [0|7] "" Vector__XXX
 SG_ Radar2_Target02_dz : 23|6@0+ (0.25,-5) [-5|10.75] "m" Vector__XXX
 SG_ Radar2_Target02_movingState : 17|2@0+ (1,0) [0|3] "" Vector__XXX
 SG_ Radar2_Target02_vy : 7|10@0+ (0.125,-64) [-64|63.875] "m/s" Vector__XXX
 SG_ Radar2_Target02_vxSigma : 25|6@0+ (0.0625,0) [0|3.9375] "m/s" Vector__XXX
 SG_ Radar2_Target02_dxSigma : 31|6@0+ (0.0625,0) [0|3.9375] "m" Vector__XXX
 SG_ Radar2_Target02_axSigma : 35|6@0+ (0.0625,0) [0|3.9375] "m/s2" Vector__XXX
 SG_ Radar2_Target02_MessBconsistBit : 56|1@0+ (1,0) [0|1] "" Vector__XXX

BO_ 1637 Radar2_Target03_A: 8 Bosch_Radar2
 SG_ Radar2_Target03_wObstacle : 53|5@0+ (0.03125,0) [0|0.96875] "" Vector__XXX
 SG_ Radar2_Target03_wNonObstacle : 63|5@0+ (0.03125,0) [0|0.96875] "" Vector__XXX
 SG_ Radar2_Target03_wExist : 36|5@0+ (0.03125,0) [0|0.96875] "-" Vector__XXX
 SG_ Radar2_Target03_ax : 47|10@0+ (0.03125,-16) [-16|15.96875] "m/s2" Vector__XXX
 SG_ Radar2_Target03_vx : 11|12@0+ (0.0625,-128) [-128|127.9375] "m/s" Vector__XXX
 SG_ Radar2_Target03_dy : 31|11@0+ (0.125,-128) [-128|127.875] "m" Vector__XXX
 SG_ Radar2_Target03_dx : 7|12@0+ (0.0625,-128) [-128|127.9375] "m" Vector__XXX
 SG_ Radar2_Target03_flagValid : 48|1@0+ (1,0) [0|1] "" Vector__XXX
 SG_ Radar2_Target03_flagHist : 57|1@0+ (1,0) [0|1] "" Vector__XXX
 SG_ Radar2_Target03_flagMeas : 58|1@0+ (1,0) [0|1] "" Vector__XXX
 SG_ Radar2_Target03_MessAconsistBit : 56|1@0+ (1,0) [0|1] "" Vector__XXX

BO_ 1638 Radar2_Target03_B: 8 Bosch_Radar2
 SG_ Radar2_Target03_wClass : 55|5@0+ (0.03125,0) [0|0.96875] "" Vector__XXX
 SG_ Radar2_Target03_dxRearEndLoss : 63|6@0+ (0.125,0) [0|7.875] "m" Vector__XXX
 SG_ Radar2_Target03_dySigma : 45|6@0+ (0.0625,0) [0|3.9375] "m" Vector__XXX
 SG_ Radar2_Target03_dLength : 13|6@0+ (0.125,0) [0|7.875] "m" Vector__XXX
 SG_ Radar2_Target03_class : 50|3@0+ (1,0) [0|7] "" Vector__XXX
 SG_ Radar2_Target03_dz : 23|6@0+ (0.25,-5) [-5|10.75] "m" Vector__XXX
 SG_ Radar2_Target03_movingState : 17|2@0+ (1,0) [0|3] "" Vector__XXX
 SG_ Radar2_Target03_vy : 7|10@0+ (0.125,-64) [-64|63.875] "m/s" Vector__XXX
 SG_ Radar2_Target03_vxSigma : 25|6@0+ (0.0625,0) [0|3.9375] "m/s" Vector__XXX
 SG_ Radar2_Target03_dxSigma : 31|6@0+ (0.0625,0) [0|3.9375] "m" Vector__XXX
 SG_ Radar2_Target03_axSigma : 35|6@0+ (0.0625,0) [0|3.9375] "m/s2" Vector__XXX
 SG_ Radar2_Target03_MessBconsistBit : 56|1@0+ (1,0) [0|1] "" Vector__XXX

BO_ 1647 Radar2_Target04_A: 8 Bosch_Radar2
 SG_ Radar2_Target04_wObstacle : 53|5@0+ (0.03125,0) [0|0.96875] "" Vector__XXX
 SG_ Radar2_Target04_wNonObstacle : 63|5@0+ (0.03125,0) [0|0.96875] "" Vector__XXX
 SG_ Radar2_Target04_wExist : 36|5@0+ (0.03125,0) [0|0.96875] "-" Vector__XXX
 SG_ Radar2_Target04_ax : 47|10@0+ (0.03125,-16) [-16|15.96875] "m/s2" Vector__XXX
 SG_ Radar2_Target04_vx : 11|12@0+ (0.0625,-128) [-128|127.9375] "m/s" Vector__XXX
 SG_ Radar2_Target04_dy : 31|11@0+ (0.125,-128) [-128|127.875] "m" Vector__XXX
 SG_ Radar2_Target04_dx : 7|12@0+ (0.0625,-128) [-128|127.9375] "m" Vector__XXX
 SG_ Radar2_Target04_flagValid : 48|1@0+ (1,0) [0|1] "" Vector__XXX
 SG_ Radar2_Target04_flagHist : 57|1@0+ (1,0) [0|1] "" Vector__XXX
 SG_ Radar2_Target04_flagMeas : 58|1@0+ (1,0) [0|1] "" Vector__XXX
 SG_ Radar2_Target04_MessAconsistBit : 56|1@0+ (1,0) [0|1] "" Vector__XXX

BO_ 1648 Radar2_Target04_B: 8 Bosch_Radar2
 SG_ Radar2_Target04_wClass : 55|5@0+ (0.03125,0) [0|0.96875] "" Vector__XXX
 SG_ Radar2_Target04_dxRearEndLoss : 63|6@0+ (0.125,0) [0|7.875] "m" Vector__XXX
 SG_ Radar2_Target04_dySigma : 45|6@0+ (0.0625,0) [0|3.9375] "m" Vector__XXX
 SG_ Radar2_Target04_dLength : 13|6@0+ (0.125,0) [0|7.875] "m" Vector__XXX
 SG_ Radar2_Target04_class : 50|3@0+ (1,0) [0|7] "" Vector__XXX
 SG_ Radar2_Target04_dz : 23|6@0+ (0.25,-5) [-5|10.75] "m" Vector__XXX
 SG_ Radar2_Target04_movingState : 17|2@0+ (1,0) [0|3] "" Vector__XXX
 SG_ Radar2_Target04_vy : 7|10@0+ (0.125,-64) [-64|63.875] "m/s" Vector__XXX
 SG_ Radar2_Target04_vxSigma : 25|6@0+ (0.0625,0) [0|3.9375] "m/s" Vector__XXX
 SG_ Radar2_Target04_dxSigma : 31|6@0+ (0.0625,0) [0|3.9375] "m" Vector__XXX
 SG_ Radar2_Target04_axSigma : 35|6@0+ (0.0625,0) [0|3.9375] "m/s2" Vector__XXX
 SG_ Radar2_Target04_MessBconsistBit : 56|1@0+ (1,0) [0|1] "" Vector__XXX

BO_ 1657 Radar2_Target05_A: 8 Bosch_Radar2
 SG_ Radar2_Target05_wObstacle : 53|5@0+ (0.03125,0) [0|0.96875] "" Vector__XXX
 SG_ Radar2_Target05_wNonObstacle : 63|5@0+ (0.03125,0) [0|0.96875] "" Vector__XXX
 SG_ Radar2_Target05_wExist : 36|5@0+ (0.03125,0) [0|0.96875] "-" Vector__XXX
 SG_ Radar2_Target05_ax : 47|10@0+ (0.03125,-16) [-16|15.96875] "m/s2" Vector__XXX
 SG_ Radar2_Target05_vx : 11|12@0+ (0.0625,-128) [-128|127.9375] "m/s" Vector__XXX
 SG_ Radar2_Target05_dy : 31|11@0+ (0.125,-128) [-128|127.875] "m" Vector__XXX
 SG_ Radar2_Target05_dx : 7|12@0+ (0.0625,-128) [-128|127.9375] "m" Vector__XXX
 SG_ Radar2_Target05_flagValid : 48|1@0+ (1,0) [0|1] "" Vector__XXX
 SG_ Radar2_Target05_flagHist : 57|1@0+ (1,0) [0|1] "" Vector__XXX
 SG_ Radar2_Target05_flagMeas : 58|1@0+ (1,0) [0|1] "" Vector__XXX
 SG_ Radar2_Target05_MessAconsistBit : 56|1@0+ (1,0) [0|1] "" Vector__XXX

BO_ 1658 Radar2_Target05_B: 8 Bosch_Radar2
 SG_ Radar2_Target05_wClass : 55|5@0+ (0.03125,0) [0|0.96875] "" Vector__XXX
 SG_ Radar2_Target05_dxRearEndLoss : 63|6@0+ (0.125,0) [0|7.875] "m" Vector__XXX
 SG_ Radar2_Target05_dySigma : 45|6@0+ (0.0625,0) [0|3.9375] "m" Vector__XXX
 SG_ Radar2_Target05_dLength : 13|6@0+ (0.125,0) [0|7.875] "m" Vector__XXX
 SG_ Radar2_Target05_class : 50|3@0+ (1,0) [0|7] "" Vector__XXX
 SG_ Radar2_Target05_dz : 23|6@0+ (0.25,-5) [-5|10.75] "m" Vector__XXX
 SG_ Radar2_Target05_movingState : 17|2@0+ (1,0) [0|3] "" Vector__XXX
 SG_ Radar2_Target05_vy : 7|10@0+ (0.125,-64) [-64|63.875] "m/s" Vector__XXX
 SG_ Radar2_Target05_vxSigma : 25|6@0+ (0.0625,0) [0|3.9375] "m/s" Vector__XXX
 SG_ Radar2_Target05_dxSigma : 31|6@0+ (0.0625,0) [0|3.9375] "m" Vector__XXX
 SG_ Radar2_Target05_axSigma : 35|6@0+ (0.0625,0) [0|3.9375] "m/s2" Vector__XXX
 SG_ Radar2_Target05_MessBconsistBit : 56|1@0+ (1,0) [0|1] "" Vector__XXX

BO_ 1667 Radar2_Object_Ender: 8 Bosch_Radar2
 SG_ Radar2_PacketChecksum : 63|8@0+ (1,0) [0|0] "" Vector__XXX
 SG_ Radar2_Object_timestamp : 7|8@0+ (0.0009765625,0) [0|0.2490234375] "s" Vector__XXX
 SG_ Radar2_MessEnderConsistBit : 48|1@0+ (1,0) [0|1] "" Vector__XXX
 SG_ Radar2_TCCounter : 31|8@0+ (1,0) [0|0] "" Vector__XXX

BO_ 1282 Radar2_Object_Starter: 8 Bosch_Radar2
 SG_ Radar2_Veh_vEgo : 23|12@0+ (0.0625,-128) [-128|127.9375] "m/s" Vector__XXX
 SG_ Radar2_Veh_aEgo : 27|10@0+ (0.03125,-16) [-16|15.96875] "m/s²" Vector__XXX
 SG_ Radar2_Veh_slipAngle : 45|14@0+ (6.103515625E-005,-0.5) [-0.5|0.49993896484375] "Rad" Vector__XXX
 SG_ Radar2_Veh_psiDt : 7|16@0+ (6.103515625E-005,-2) [-2|1.99993896484375] "rad/s" Vector__XXX
 SG_ Radar2_MessStarterConsistBit : 56|1@0+ (1,0) [0|1] "" Vector__XXX

BO_ 1672 Radar2_Status: 8 Bosch_Radar2
 SG_ R2_Stat_HWFail : 20|1@0+ (1,0) [0|1] "" Vector__XXX
 SG_ R2_Stat_SGUFail : 21|1@0+ (1,0) [0|1] "" Vector__XXX
 SG_ R2_Stat_AbsorptionBlindness : 39|8@0+ (0.00390625,0) [0|0.99609375] "" Vector__XXX
 SG_ R2_Stat_DistortionBlindness : 47|8@0+ (0.00390625,0) [0|0.99609375] "" Vector__XXX
 SG_ R2_Stat_ITCInfo : 7|16@0+ (1,0) [0|65535] "" Vector__XXX
 SG_ R2_Stat_HorizontalMisalignment : 19|12@0+ (0.0001,-0.2048) [-0.2048|0.2047] "rad" Vector__XXX
 SG_ R2_Stat_MC : 51|4@0+ (1,0) [0|15] "" Vector__XXX
 SG_ R2_Stat_CRC : 63|8@0+ (1,0) [0|255] "" Vector__XXX

BO_ 200 Radar_Input_Veh_DynData: 8 RADAR_INPUT
 SG_ RI_Veh_velocity : 23|16@0- (0.0625,0) [-2048|2047.9375] "km/h"  Bosch_Radar2,Bosch_Radar1
 SG_ RI_Veh_yawRate : 37|14@0- (0.05,0) [-409.6|409.55] "deg/s"  Bosch_Radar2,Bosch_Radar1
 SG_ RI_Veh_standstill : 38|1@0+ (1,0) [0|1] ""  Bosch_Radar2,Bosch_Radar1
 SG_ RI_Veh_Steer_angle : 7|16@0- (0.03125,0) [-1024|1023.96875] "deg"  Bosch_Radar2,Bosch_Radar1
 SG_ RI_Veh_Use_Steer_angle : 39|1@0+ (1,0) [0|1] ""  Bosch_Radar2,Bosch_Radar1
 SG_ RI_Veh_PRNDSTAT : 50|3@0+ (1,0) [0|7] ""  Bosch_Radar2,Bosch_Radar1
 SG_ RI_Veh_AnyWheelSlipEvent : 51|1@0+ (1,0) [0|1] ""  Bosch_Radar2,Bosch_Radar1
 SG_ RI_Veh_MC : 55|4@0+ (1,0) [0|15] ""  Bosch_Radar2,Bosch_Radar1
 SG_ RI_Veh_CRC : 63|8@0+ (1,0) [0|255] ""  Bosch_Radar2,Bosch_Radar1

BO_ 201 Radar_Input_Veh_Dim: 8 RADAR_INPUT
 SG_ RI_VD_Max_Width : 7|8@0+ (0.03125,0) [0|7.96875] "m"  Bosch_Radar2,Bosch_Radar1
 SG_ RI_VD_Min_Width : 15|8@0+ (0.03125,0) [0|7.96875] "m"  Bosch_Radar2,Bosch_Radar1
 SG_ RI_VD_LongFrontBumperPos : 16|9@0- (0.03125,0) [-8|7.96875] "m"  Bosch_Radar2,Bosch_Radar1
 SG_ RI_VD_LongRearBumperPos : 32|9@0- (0.03125,0) [-8|7.96875] "m"  Bosch_Radar2,Bosch_Radar1
 SG_ RI_VD_MC : 51|4@0+ (1,0) [0|15] ""  Bosch_Radar2,Bosch_Radar1
 SG_ RI_VD_CRC : 63|8@0+ (1,0) [0|255] ""  Bosch_Radar2,Bosch_Radar1

BO_ 202 Radar_Input_Wheel_Info: 5 RADAR_INPUT
 SG_ RI_WI_WheelBase : 7|8@0+ (0.03125,0) [0|7.96875] "m"  Bosch_Radar2,Bosch_Radar1
 SG_ RI_WI_TrackWidth : 15|8@0+ (0.03125,0) [0|7.96875] "m"  Bosch_Radar2,Bosch_Radar1
 SG_ RI_WI_Steering_Angle_Ratio : 23|8@0+ (0.125,0) [0|31.875] ""  Bosch_Radar2,Bosch_Radar1
 SG_ RI_WI_MC : 27|4@0+ (1,0) [0|15] ""  Bosch_Radar2,Bosch_Radar1
 SG_ RI_WI_CRC : 39|8@0+ (1,0) [0|255] ""  Bosch_Radar2,Bosch_Radar1

BO_ 490 Radar1_Input_MountInfo: 8 RADAR_INPUT
 SG_ R1I_MI_LongSensorMountToRearAxle : 0|9@0- (0.03125,0) [-8|7.96875] "m"  Bosch_Radar1
 SG_ R1I_MI_LatSensorMountToCenter : 7|7@0- (0.03125,0) [-2|1.96875] "m"  Bosch_Radar1
 SG_ R1I_MI_SensorHeight : 23|8@0+ (0.005,0) [0|1.275] "m"  Bosch_Radar1
 SG_ R1I_MI_SensorMountAngle : 30|15@0- (0.0002,0) [-3.2768|3.2766] "rad"  Bosch_Radar1
 SG_ R1I_MI_SensorOrientation : 31|1@0+ (1,0) [0|1] ""  Bosch_Radar1
 SG_ R1I_MI_MC : 51|4@0+ (1,0) [0|15] ""  Bosch_Radar1
 SG_ R1I_MI_CRC : 63|8@0+ (1,0) [0|255] ""  Bosch_Radar1

BO_ 492 Radar2_Input_MountInfo: 8 RADAR_INPUT
 SG_ R2I_MI_LongSensorMountToRearAxle : 0|9@0- (0.03125,0) [-8|7.96875] "m"  Bosch_Radar2
 SG_ R2I_MI_LatSensorMountToCenter : 7|7@0- (0.03125,0) [-2|1.96875] "m"  Bosch_Radar2
 SG_ R2I_MI_SensorHeight : 23|8@0+ (0.005,0) [0|1.275] "m"  Bosch_Radar2
 SG_ R2I_MI_SensorMountAngle : 30|15@0- (0.0002,0) [-3.2768|3.2766] "rad"  Bosch_Radar2
 SG_ R2I_MI_SensorOrientation : 31|1@0+ (1,0) [0|1] ""  Bosch_Radar2
 SG_ R2I_MI_MC : 51|4@0+ (1,0) [0|15] ""  Bosch_Radar2
 SG_ R2I_MI_CRC : 63|8@0+ (1,0) [0|255] ""  Bosch_Radar2

CM_ "XGU Network";
CM_ BO_ 1670 "Radar1 sensor status message";
CM_ SG_ 1670 R1_Stat_HWFail "Radar1 Hardware Failure indicator";
CM_ SG_ 1670 R1_Stat_SGUFail "Radar1 System Fault indicator";
CM_ SG_ 1670 R1_Stat_AbsorptionBlindness "Radar1 Absorption Blindness status indicator";
CM_ SG_ 1670 R1_Stat_DistortionBlindness "Radar1 Distortion Blindness status indicator";
CM_ SG_ 1670 R1_Stat_ITCInfo "Radar1 ITC of the lowest active fault";
CM_ SG_ 1670 R1_Stat_HorizontalMisalignment "Radar1 Horizontal Misalignment";
CM_ SG_ 1670 R1_Stat_MC "Radar1 Status Message Counter";
CM_ SG_ 1670 R1_Stat_CRC "Radar1 Status CRC";
CM_ BO_ 1672 "Radar2 sensor status message";
CM_ SG_ 1672 R2_Stat_HWFail "Radar2 Hardware Failure indicator";
CM_ SG_ 1672 R2_Stat_SGUFail "Radar2 System Fault indicator";
CM_ SG_ 1672 R2_Stat_AbsorptionBlindness "Radar2 Absorption Blindness status indicator";
CM_ SG_ 1672 R2_Stat_DistortionBlindness "Radar2 Distortion Blindness status indicator";
CM_ SG_ 1672 R2_Stat_ITCInfo "Radar2 ITC of the lowest active fault";
CM_ SG_ 1672 R2_Stat_HorizontalMisalignment "Radar2 Horizontal Misalignment";
CM_ SG_ 1672 R2_Stat_MC "Radar2 Status Message Counter";
CM_ SG_ 1672 R2_Stat_CRC "Radar2 Status CRC";
CM_ BO_ 200 "Vehicle Dynamic Data Message";
CM_ SG_ 200 RI_Veh_velocity "Vehicle velocity";
CM_ SG_ 200 RI_Veh_yawRate "Vehicle YawRate";
CM_ SG_ 200 RI_Veh_standstill "1: Vehicle is at standstill. 0: Vehicle is not at standstill.";
CM_ SG_ 200 RI_Veh_Steer_angle "Vehicle steering angle";
CM_ SG_ 200 RI_Veh_Use_Steer_angle "1: Radar will use vehicle steering angle";
CM_ SG_ 200 RI_Veh_PRNDSTAT "Vehicle Current Gear Status";
CM_ SG_ 200 RI_Veh_AnyWheelSlipEvent "Indicates that any type of ESP event (ESC,ABS,etc.) is active";
CM_ SG_ 200 RI_Veh_MC "Radar_Input_Veh_DynData Message Counter";
CM_ SG_ 200 RI_Veh_CRC "Radar_Input_Veh_DynData CRC";
CM_ BO_ 201 "Vehicle Dimension information";
CM_ SG_ 201 RI_VD_Max_Width "Maximum width of vehicle";
CM_ SG_ 201 RI_VD_Min_Width "Minimum width of vehicle";
CM_ SG_ 201 RI_VD_LongFrontBumperPos "Longitudinal distance to front bumper from center of rear axle";
CM_ SG_ 201 RI_VD_LongRearBumperPos "Longitudinal distance to rear bumper from center of rear axle";
CM_ SG_ 201 RI_VD_MC "Radar_Input_Veh_Dim Message Counter";
CM_ SG_ 201 RI_VD_CRC "Radar_Input_Veh_Dim CRC";
CM_ BO_ 202 "Vehicle Wheel-related information";
CM_ SG_ 202 RI_WI_WheelBase "Distance from center of front wheel to center of rear wheel";
CM_ SG_ 202 RI_WI_TrackWidth "Distance from center of left wheel to center of right wheel of the non-driven axle";
CM_ SG_ 202 RI_WI_Steering_Angle_Ratio "Ratio of steering wheel angle to angle at the wheels";
CM_ SG_ 202 RI_WI_MC "Radar_Input_Wheel_Info Message Counter";
CM_ SG_ 202 RI_WI_CRC "Radar_Input_Wheel_Info CRC";
CM_ BO_ 490 "Radar1 Sensor Mounting Information";
CM_ SG_ 490 R1I_MI_LongSensorMountToRearAxle "Longitudinal distance to sensor from center of rear axle";
CM_ SG_ 490 R1I_MI_LatSensorMountToCenter "Lateral distance to sensor from center of vehicle, Left = positive";
CM_ SG_ 490 R1I_MI_SensorHeight "Sensor mounting height from ground";
CM_ SG_ 490 R1I_MI_SensorMountAngle "Sensor Mounting Angle, 0: Straight Forward, Positive: Counter-Clockwise, Negative: Clockwise";
CM_ SG_ 490 R1I_MI_SensorOrientation "Sensor Orientation: 0: Connector Down, 1: Connector Up";
CM_ SG_ 490 R1I_MI_MC "Radar1_Input_MountInfo Message Counter";
CM_ SG_ 490 R1I_MI_CRC "Radar1_Input_MountInfo CRC";
CM_ BO_ 492 "Radar2 Sensor Mounting Information";
CM_ SG_ 492 R2I_MI_LongSensorMountToRearAxle "Longitudinal distance to sensor from center of rear axle";
CM_ SG_ 492 R2I_MI_LatSensorMountToCenter "Lateral distance to sensor from center of vehicle, Left = positive";
CM_ SG_ 492 R2I_MI_SensorHeight "Sensor mounting height from ground";
CM_ SG_ 492 R2I_MI_SensorMountAngle "Sensor Mounting Angle, 0: Straight Forward, Positive: Counter-Clockwise, Negative: Clockwise";
CM_ SG_ 492 R2I_MI_SensorOrientation "Sensor Orientation: 0: Connector Down, 1: Connector Up";
CM_ SG_ 492 R2I_MI_MC "Radar2_Input_MountInfo Message Counter";
CM_ SG_ 492 R2I_MI_CRC "Radar2_Input_MountInfo CRC";
BA_DEF_ SG_  "GenSigSendOnInit" ENUM  "Not Initialized","Application","Handler";
BA_DEF_ SG_  "GenSigSendType" ENUM  "not used","not used","not used","not used","not used","not used","not used","NoSigSendType","not used","not used","OnAnyChange","OnChangeIfActive","OnDelta";
BA_DEF_ SG_  "GenSigStartValue" INT 0 65535;
BA_DEF_ BO_  "GenMsgSendType" ENUM  "cyclic","triggered";
BA_DEF_ BU_  "NmNode" ENUM  "No","Yes";
BA_DEF_ BU_  "MessageManagerUsed" ENUM  "No","Yes";
BA_DEF_  "NmType" STRING ;
BA_DEF_  "Manufacturer" ENUM  "Unknown","DBAG","VAG","BMW","PAG","GM";
BA_DEF_  "NmBaseAddress" HEX 0 2032;
BA_DEF_  "NmMessageCount" INT 0 32;
BA_DEF_  "Baudrate" INT 0 1000000;
BA_DEF_ BO_  "GenMsgCycleTime" INT 0 100000;
BA_DEF_  "BusType" STRING ;
BA_DEF_DEF_  "GenSigSendOnInit" "Not Initialized";
BA_DEF_DEF_  "GenSigSendType" "NoSigSendType";
BA_DEF_DEF_  "GenSigStartValue" 0;
BA_DEF_DEF_  "GenMsgSendType" "triggered";
BA_DEF_DEF_  "NmNode" "Yes";
BA_DEF_DEF_  "MessageManagerUsed" "Yes";
BA_DEF_DEF_  "NmType" "GMLAN";
BA_DEF_DEF_  "Manufacturer" "Unknown";
BA_DEF_DEF_  "NmBaseAddress" 1568;
BA_DEF_DEF_  "NmMessageCount" 32;
BA_DEF_DEF_  "Baudrate" 0;
BA_DEF_DEF_  "GenMsgCycleTime" 0;
BA_DEF_DEF_  "BusType" "";
BA_ "BusType" "CAN";
BA_ "NmType" "unknown";
BA_ "NmBaseAddress" 0;
BA_ "Baudrate" 500;
BA_ "GenMsgCycleTime" BO_ 200 20;
BA_ "GenMsgSendType" BO_ 200 0;
BA_ "GenMsgCycleTime" BO_ 201 1000;
BA_ "GenMsgSendType" BO_ 201 0;
BA_ "GenMsgSendType" BO_ 202 0;
BA_ "GenMsgCycleTime" BO_ 202 1000;
BA_ "GenMsgCycleTime" BO_ 490 1000;
BA_ "GenMsgSendType" BO_ 490 0;
BA_ "GenMsgCycleTime" BO_ 492 1000;
BA_ "GenMsgSendType" BO_ 492 0;
BA_ "GenSigStartValue" SG_ 1285 Radar1_Obj00_dx 2048;
BA_ "GenSigStartValue" SG_ 1295 Radar1_Obj01_dx 2048;
BA_ "GenSigStartValue" SG_ 1305 Radar1_Obj02_dx 2048;
BA_ "GenSigStartValue" SG_ 1315 Radar1_Obj03_dx 2048;
BA_ "GenSigStartValue" SG_ 1325 Radar1_Obj04_dx 2048;
BA_ "GenSigStartValue" SG_ 1335 Radar1_Obj05_dx 2048;
BA_ "GenSigStartValue" SG_ 1345 Radar1_Obj06_dx 2048;
BA_ "GenSigStartValue" SG_ 1355 Radar1_Obj07_dx 2048;
BA_ "GenSigStartValue" SG_ 1365 Radar1_Obj08_dx 2048;
BA_ "GenSigStartValue" SG_ 1375 Radar1_Obj09_dx 2048;
BA_ "GenSigStartValue" SG_ 1385 Radar1_Obj10_dx 2048;
BA_ "GenSigStartValue" SG_ 1395 Radar1_Obj11_dx 2048;
BA_ "GenSigStartValue" SG_ 1405 Radar1_Obj12_dx 2048;
BA_ "GenSigStartValue" SG_ 1415 Radar1_Obj13_dx 2048;
BA_ "GenSigStartValue" SG_ 1425 Radar1_Obj14_dx 2048;
BA_ "GenSigStartValue" SG_ 1435 Radar1_Obj15_dx 2048;
BA_ "GenSigStartValue" SG_ 1445 Radar1_Obj16_dx 2048;
BA_ "GenSigStartValue" SG_ 1455 Radar1_Obj17_dx 2048;
BA_ "GenSigStartValue" SG_ 1465 Radar1_Obj18_dx 2048;
BA_ "GenSigStartValue" SG_ 1475 Radar1_Obj19_dx 2048;
BA_ "GenSigStartValue" SG_ 1485 Radar1_Obj20_dx 2048;
BA_ "GenSigStartValue" SG_ 1495 Radar1_Obj21_dx 2048;
BA_ "GenSigStartValue" SG_ 1505 Radar1_Obj22_dx 2048;
BA_ "GenSigStartValue" SG_ 1515 Radar1_Obj23_dx 2048;
BA_ "GenSigStartValue" SG_ 1525 Radar1_Obj24_dx 2048;
BA_ "GenSigStartValue" SG_ 1535 Radar1_Obj25_dx 2048;
BA_ "GenSigStartValue" SG_ 1545 Radar1_Obj26_dx 2048;
BA_ "GenSigStartValue" SG_ 1555 Radar1_Obj27_dx 2048;
BA_ "GenSigStartValue" SG_ 1565 Radar1_Obj28_dx 2048;
BA_ "GenSigStartValue" SG_ 1575 Radar1_Obj29_dx 2048;
BA_ "GenSigStartValue" SG_ 1585 Radar1_Obj30_dx 2048;
BA_ "GenSigStartValue" SG_ 1595 Radar1_Obj31_dx 2048;
BA_ "GenSigStartValue" SG_ 1605 Radar1_Target00_dx 2048;
BA_ "GenSigStartValue" SG_ 1615 Radar1_Target01_dx 2048;
BA_ "GenSigStartValue" SG_ 1625 Radar1_Target02_dx 2048;
BA_ "GenSigStartValue" SG_ 1635 Radar1_Target03_dx 2048;
BA_ "GenSigStartValue" SG_ 1645 Radar1_Target04_dx 2048;
BA_ "GenSigStartValue" SG_ 1655 Radar1_Target05_dx 2048;
BA_ "GenSigStartValue" SG_ 1287 Radar2_Obj00_dx 2048;
BA_ "GenSigStartValue" SG_ 1297 Radar2_Obj01_dx 2048;
BA_ "GenSigStartValue" SG_ 1307 Radar2_Obj02_dx 2048;
BA_ "GenSigStartValue" SG_ 1317 Radar2_Obj03_dx 2048;
BA_ "GenSigStartValue" SG_ 1327 Radar2_Obj04_dx 2048;
BA_ "GenSigStartValue" SG_ 1337 Radar2_Obj05_dx 2048;
BA_ "GenSigStartValue" SG_ 1347 Radar2_Obj06_dx 2048;
BA_ "GenSigStartValue" SG_ 1357 Radar2_Obj07_dx 2048;
BA_ "GenSigStartValue" SG_ 1367 Radar2_Obj08_dx 2048;
BA_ "GenSigStartValue" SG_ 1377 Radar2_Obj09_dx 2048;
BA_ "GenSigStartValue" SG_ 1387 Radar2_Obj10_dx 2048;
BA_ "GenSigStartValue" SG_ 1397 Radar2_Obj11_dx 2048;
BA_ "GenSigStartValue" SG_ 1407 Radar2_Obj12_dx 2048;
BA_ "GenSigStartValue" SG_ 1417 Radar2_Obj13_dx 2048;
BA_ "GenSigStartValue" SG_ 1427 Radar2_Obj14_dx 2048;
BA_ "GenSigStartValue" SG_ 1437 Radar2_Obj15_dx 2048;
BA_ "GenSigStartValue" SG_ 1447 Radar2_Obj16_dx 2048;
BA_ "GenSigStartValue" SG_ 1457 Radar2_Obj17_dx 2048;
BA_ "GenSigStartValue" SG_ 1467 Radar2_Obj18_dx 2048;
BA_ "GenSigStartValue" SG_ 1477 Radar2_Obj19_dx 2048;
BA_ "GenSigStartValue" SG_ 1487 Radar2_Obj20_dx 2048;
BA_ "GenSigStartValue" SG_ 1497 Radar2_Obj21_dx 2048;
BA_ "GenSigStartValue" SG_ 1507 Radar2_Obj22_dx 2048;
BA_ "GenSigStartValue" SG_ 1517 Radar2_Obj23_dx 2048;
BA_ "GenSigStartValue" SG_ 1527 Radar2_Obj24_dx 2048;
BA_ "GenSigStartValue" SG_ 1537 Radar2_Obj25_dx 2048;
BA_ "GenSigStartValue" SG_ 1547 Radar2_Obj26_dx 2048;
BA_ "GenSigStartValue" SG_ 1557 Radar2_Obj27_dx 2048;
BA_ "GenSigStartValue" SG_ 1567 Radar2_Obj28_dx 2048;
BA_ "GenSigStartValue" SG_ 1577 Radar2_Obj29_dx 2048;
BA_ "GenSigStartValue" SG_ 1587 Radar2_Obj30_dx 2048;
BA_ "GenSigStartValue" SG_ 1597 Radar2_Obj31_dx 2048;
BA_ "GenSigStartValue" SG_ 1607 Radar2_Target00_dx 2048;
BA_ "GenSigStartValue" SG_ 1617 Radar2_Target01_dx 2048;
BA_ "GenSigStartValue" SG_ 1627 Radar2_Target02_dx 2048;
BA_ "GenSigStartValue" SG_ 1637 Radar2_Target03_dx 2048;
BA_ "GenSigStartValue" SG_ 1647 Radar2_Target04_dx 2048;
BA_ "GenSigStartValue" SG_ 1657 Radar2_Target05_dx 2048;
VAL_ 1285 Radar1_Obj00_flagValid 1 "Radar1_object_valid" 0 "Radar1_object_invalid" ;
VAL_ 1285 Radar1_Obj00_flagHist 1 "Radar1_object_prev_present" 0 "Radar1_new_object" ;
VAL_ 1285 Radar1_Obj00_flagMeas 1 "Radar1_object_measured" 0 "Radar1_object_not_measured" ;
VAL_ 1286 Radar1_Obj00_class 4 "constElem" 3 "movingPedestrian" 2 "movingTwoWheelVeh" 1 "movingFourWheelVeh" 0 "unknown" ;
VAL_ 1286 Radar1_Obj00_movingState 3 "standing" 2 "stopped" 1 "moving" 0 "Unknown/Unclassified" ;
VAL_ 1287 Radar2_Obj00_flagValid 1 "Radar1_object_valid" 0 "Radar1_object_invalid" ;
VAL_ 1287 Radar2_Obj00_flagHist 1 "Radar1_object_prev_present" 0 "Radar1_new_object" ;
VAL_ 1287 Radar2_Obj00_flagMeas 1 "Radar1_object_measured" 0 "Radar1_object_not_measured" ;
VAL_ 1288 Radar2_Obj00_class 4 "constElem" 3 "movingPedestrian" 2 "movingTwoWheelVeh" 1 "movingFourWheelVeh" 0 "unknown" ;
VAL_ 1288 Radar2_Obj00_movingState 3 "standing" 2 "stopped" 1 "moving" 0 "Unknown/Unclassified" ;
VAL_ 200 RI_Veh_PRNDSTAT 0 "Park" 1 "Reverse" 2 "Neutral" 3 "Drive" ;
